VERSION ""

NS_ :

BS_:

BU_: ACCL BGW DBPC DCFL DCFR DCRL DCRR DSM ECPM FBCM FFL FLDC FRDC HLL HLR HUD IHUB LGL PBPC PSM RCLL RCLR RLDC RLSM RRDC RRSM TOOL RCCL RCCR SCAM DEMFL DEMFR DEMRL DEMRR DOSFL DOSFR DOSRL DOSRR
VAL_TABLE_ GLOB_VehicleSpeedDir 3 "SNA" 1 "Positive" 0 "Negative" ;
VAL_TABLE_ GLOB_UnlockPreference 3 "SNA" 1 "UnlockAllDoors" 0 "UnlockNearestDoor" ;
VAL_TABLE_ GLOB_DistanceUnits 3 "SNA" 1 "Mile" 0 "Kilometer" ;
VAL_TABLE_ GLOB_ChargeDisplaySetting 3 "SNA" 1 "Percentage" 0 "Miles" ;
VAL_TABLE_ GLOB_DewPointTempRls 3 "SNA" 2 "Err" 1 "Vel" 0 "Nr" ;
VAL_TABLE_ GLOB_RsSchwallRls 1 "Active" 0 "Inactive" ;
VAL_TABLE_ GLOB_WiperSpeedRls 3 "SNA" 2 "HighWiperSpeed" 1 "LowWiperSpeed" 0 "Stop" ;
VAL_TABLE_ GLOB_RlsStatus 7 "SNA" 3 "RlsActive" 2 "OverVoltage" 1 "LowVoltage" 0 "RlsRebooting" ;
VAL_TABLE_ GLOB_HumSnsIntFltRls 1 "Error" 0 "Normal" ;
VAL_TABLE_ GLOB_HeadLightsOnRls 1 "On" 0 "Off" ;
VAL_TABLE_ GLOB_AmbientBrightnessRls 1 "Error" 0 "Calculating" ;
VAL_TABLE_ GLOB_AmbientBrightnessRlsU16 2047 "Error" ;
VAL_TABLE_ GLOB_LowBeamRequest 15 "SNA" 7 "SubtractThreeDeg" 6 "SubtractTwoDeg" 5 "SubtractOneDeg" 4 "ZeroDeg" 3 "AddOneDeg" 2 "AddTwoDeg" 1 "AddThreeDeg" 0 "Stop" ;
VAL_TABLE_ GLOB_DriverMirrorHeaterState 3 "SNA" 2 "Fault" 1 "On" 0 "Off" ;
VAL_TABLE_ GLOB_ExtLightTemperatureStatus 3 "SNA" 2 "Under" 1 "Over" 0 "Ok" ;
VAL_TABLE_ GLOB_DoorStopSource 15 "SNA" 7 "Overcurrent" 6 "PreventativeObstacleDetection" 5 "ReactiveObstacleDetection" 4 "InteriorButton" 3 "ExteriorButton" 2 "Cpillar" 1 "Bpillar" 0 "Ihub" ;
VAL_TABLE_ BPG_ChargeStatus 15 "SNA" 10 "ChargeRetry" 9 "EvseInterruptedAndPluggedIn" 8 "UserInterruptedAndPluggedIn" 7 "ChargeToTargetAndPluggedIn" 6 "ChargeToTargetAndNotPluggedIn" 5 "ChargeCompleteAndNotPluggedIn" 4 "ChargeCompleteAndPluggedIn" 3 "Faulted" 2 "Charging" 1 "PluggedInAndNotCharging" 0 "NotPluggedIn" ;
VAL_TABLE_ GLOB_HonkThreeTimes 3 "SNA" 1 "HonkThreeTimes" 0 "NoCommand" ;
VAL_TABLE_ GLOB_FlashLights 3 "SNA" 1 "FlashLights" 0 "NoCommand" ;
VAL_TABLE_ GLOB_LedStatus 3 "SNA" 1 "Failure" 0 "Ok" ;
VAL_TABLE_ GLOB_BusStates 1 "Sleep" 0 "DoNotSleep" ;
VAL_TABLE_ GLOB_TemperatureStatus 3 "SNA" 2 "UnderTemperature" 1 "OverTemperature" 0 "Ok" ;
VAL_TABLE_ GLOB_SafeMode 3 "SNA" 1 "SafeMode" 0 "NormalMode" ;
VAL_TABLE_ GLOB_OffOnAutoSna 3 "SNA" 2 "Auto" 1 "On" 0 "Off" ;
VAL_TABLE_ GLOB_LanguageSelection 3 "SNA" 1 "Chinese" 0 "English" ;
VAL_TABLE_ GLOB_MassageIntensity 7 "SNA" 5 "5" 4 "4" 3 "3" 2 "2" 1 "1" 0 "0" ;
VAL_TABLE_ GLOB_SeatBeltState 1 "Buckled" 0 "Unbuckled" ;
VAL_TABLE_ BGW_BPillarScreenReq 7 "SNA" 4 "Doors" 3 "Charging" 2 "Welcome" 1 "Home" 0 "Off" ;
VAL_TABLE_ GLOB_SteerCommand 7 "SNA" 4 "Out" 3 "In" 2 "Down" 1 "Up" 0 "NoCommand" ;
VAL_TABLE_ GLOB_FwdRwdUpDn 7 "SNA" 4 "MoveDown" 3 "MoveUp" 2 "MoveRearward" 1 "MoveForward" 0 "NoCommand" ;
VAL_TABLE_ GLOB_TapHoldUpDn 7 "SNA" 4 "HoldUpward" 3 "TapUpward" 2 "HoldDownward" 1 "TapDownward" 0 "NoCommand" ;
VAL_TABLE_ GLOB_TapHoldFwdRwd 7 "SNA" 4 "HoldRearward" 3 "TapRearward" 2 "HoldForward" 1 "TapForward" 0 "NoCommand" ;
VAL_TABLE_ BGW_SeatShoulderCmd 3 "SNA" 2 "MoveBackward" 1 "MoveForward" 0 "NoCommand" ;
VAL_TABLE_ GLOB_SeatHeatVent 7 "SNA" 6 "VentHigh" 5 "VentMedium" 4 "VentLow" 3 "HeatHigh" 2 "HeatMedium" 1 "HeatLow" 0 "Off" ;
VAL_TABLE_ GLOB_MassageType 7 "SNA" 3 "Type3" 2 "Type2" 1 "Type1" 0 "Off" ;
VAL_TABLE_ GLOB_LatchStatus 6 "Unknown" 7 "SNA" 3 "Error" 2 "Primary" 1 "Secondary" 0 "Open" ;
VAL_TABLE_ GLOB_DoorCloseCmdSource 6 "CpillarClose" 7 "SNA" 5 "BpillarClose" 4 "BrakePressed" 3 "ExteriorButton" 2 "InteriorButton" 1 "EdgeSwitch" 0 "IhubClose" ;
VAL_TABLE_ GLOB_DoorOpenCmdSource 255 "SNA" 10 "CpillarOpen" 9 "CpillarPop" 8 "BpillarOpen" 7 "BpillarPop" 6 "InteriorButtonPop" 5 "InteriorButtonOpen" 4 "ExteriorButtonPop" 3 "ExteriorButtonOpen" 2 "EdgeSwitch" 1 "IhubOpen" 0 "IhubPop" ;
VAL_TABLE_ GLOB_WindowOpenSource 7 "SNA" 4 "IhubOpen" 3 "Dcrr" 2 "Dcrl" 1 "Dcfr" 0 "Dcfl" ;
VAL_TABLE_ GLOB_WindowCloseSource 7 "SNA" 4 "IhubClose" 3 "Dcrr" 2 "Dcrl" 1 "Dcfr" 0 "Dcfl" ;
VAL_TABLE_ GLOB_Latch 3 "SNA" 1 "Latch" 0 "NoLatch" ;
VAL_TABLE_ GLOB_VehicleVoltageMode 3 "SNA" 2 "Reserved" 1 "LowAndHighVoltage" 0 "False" ;
VAL_TABLE_ GLOB_VehicleDriveMode 3 "SNA" 2 "Moving" 1 "Run" 0 "False" ;
VAL_TABLE_ GLOB_VehicleSpeedQ 3 "InSpec" 0 "UndefinableAccuracySna" ;
VAL_TABLE_ GLOB_BaudRateOption 7 "SNA" 2 "Baud500k" 1 "Baud250k" 0 "Baud125k" ;
VAL_TABLE_ BGW_State 7 "SNA" 5 "EndDriveState" 4 "ExitingDriveState" 3 "DriveState" 2 "DriveAuthorizedState" 1 "DriveLikelyState" 0 "IdleState" ;
VAL_TABLE_ BGW_DoorState 3 "SNA" 2 "DoorError" 1 "DoorOpen" 0 "DoorClosed" ;
VAL_TABLE_ BGW_WakeUpCause 31 "SNA" 8 "LiftgateInteriorButton" 7 "IoExpander" 6 "Lin" 5 "WupLine" 4 "Rtc" 3 "ThermalCan" 2 "TelematicsCan" 1 "BodyCan" 0 "UnknownCause" ;
VAL_TABLE_ FBCM_HornStatus 3 "SNA" 2 "Fault" 1 "HornOn" 0 "HornOff" ;
VAL_TABLE_ FBCM_LockRejected 3 "SNA" 1 "LockRejected" 0 "LockNotRejected" ;
VAL_TABLE_ FBCM_StateVehicle 7 "SNA" 4 "SelfDriveState" 3 "DriveState" 2 "AccessoryState" 1 "StandbyState" 0 "SleepState" ;
VAL_TABLE_ FBCM_WasherFluidLevel 3 "SNA" 1 "Low" 0 "Off" ;
VAL_TABLE_ GLOB_LockRequest 3 "SNA" 2 "LockRequest" 1 "UnlockRequest" 0 "NoRequest" ;
VAL_TABLE_ GLOB_LightSync 3 "SNA" 2 "LampOff" 1 "LampOn" 0 "NoEffect" ;
VAL_TABLE_ GLOB_Bool 3 "SNA" 1 "True" 0 "False" ;
VAL_TABLE_ GLOB_BootloaderStuckSignal 255 "SNA" 18 "EcuSpecificReason3" 17 "EcuSpecificReason2" 16 "EcuSpecificReason1" 15 "Reserved12" 14 "Reserved11" 13 "Reserved10" 12 "Reserved9" 11 "Reserved8" 10 "Reserved7" 9 "Reserved6" 8 "Reserved5" 7 "Reserved4" 6 "Reserved3" 5 "Reserved2" 4 "Reserved1" 3 "BootloaderSelfCheckFail" 2 "ApplicationCrcfail" 1 "ApplicationNotPresent" 0 "NormalStartup" ;
VAL_TABLE_ GLOB_FrontTrunkStatus 3 "SNA" 2 "Ambiguous" 1 "Open" 0 "Closed" ;
VAL_TABLE_ GLOB_ChargePortDoorReq 3 "SNA" 2 "NoCommand" 1 "Open" 0 "Close" ;
VAL_TABLE_ GLOB_ChargePortDoorStatus 7 "SNA" 5 "DoorFault" 4 "DoorObstructed" 3 "DoorClosing" 2 "DoorOpen" 1 "DoorOpening" 0 "DoorClosed" ;
VAL_TABLE_ GLOB_DoorController 3 "SNA" 2 "Fault" 1 "Pressed" 0 "Unpressed" ;
VAL_TABLE_ GLOB_DoorOpenClose 7 "SNA" 4 "DoorStop" 3 "DoorPop" 2 "DoorClose" 1 "DoorOpen" 0 "NoCommand" ;
VAL_TABLE_ GLOB_DoorOperations 15 "SNA" 7 "PopDoor" 4 "DoorClose" 3 "DoorOpen" 1 "DoorStop" 0 "NoAction" ;
VAL_TABLE_ GLOB_DoorState 15 "SNA" 9 "DoorCinchingFailure" 8 "DoorUnlatchingError" 7 "DoorClosingError" 6 "DoorOpeningError" 5 "DoorClosingObstruction" 4 "DoorOpeningObstruction" 3 "DoorClosing" 2 "DoorOpening" 1 "DoorOpen" 0 "DoorClosed" ;
VAL_TABLE_ GLOB_FiveLevelIntensity 7 "SNA" 5 "Level5" 4 "Level4" 3 "Level3" 2 "Level2" 1 "Level1" 0 "Off" ;
VAL_TABLE_ GLOB_FimStatus 3 "SNA" 2 "InhibitedOnlyRemoteCause" 1 "InhibitedLocalCause" 0 "NotInhibited" ;
VAL_TABLE_ GLOB_LiftgateOperations 7 "SNA" 3 "Stop" 2 "Open" 1 "Close" 0 "NoAction" ;
VAL_TABLE_ GLOB_LiftgateStatus 15 "SNA" 7 "LiftgateClosingObstruction" 6 "LiftgateOpeningObstruction" 5 "HardwareFault" 4 "LiftgateClosing" 3 "LiftgateOpening" 2 "LiftgateClose" 1 "LiftgateAjar" 0 "LiftgateOpen" ;
VAL_TABLE_ GLOB_LightCmd 3 "SNA" 1 "TurnLightOn" 0 "TurnLightOff" ;
VAL_TABLE_ GLOB_LightStatus 3 "SNA" 2 "LightFault" 1 "LightOn" 0 "LightOff" ;
VAL_TABLE_ GLOB_LockUnlock 3 "SNA" 2 "NoChange" 1 "Unlock" 0 "Lock" ;
VAL_TABLE_ GLOB_LvMode 7 "SNA" 3 "Disconnected" 2 "ExtremelyLimited" 1 "Limited" 0 "LvAvailable" ;
VAL_TABLE_ GLOB_MirrorFold 3 "SNA" 2 "FoldIn" 1 "FoldOut" 0 "NoCommand" ;
VAL_TABLE_ GLOB_MirrorState 7 "SNA" 4 "Retracting" 3 "Retracted" 2 "Presenting" 1 "Presented" 0 "Unknown" ;
VAL_TABLE_ GLOB_MirrorTiltInOut 3 "SNA" 2 "TiltOut" 1 "TiltIn" 0 "NoCommand" ;
VAL_TABLE_ GLOB_MirrorTiltUpDown 3 "SNA" 2 "TiltDown" 1 "TiltUp" 0 "NoCommand" ;
VAL_TABLE_ GLOB_MirrorMoveInOutStatus 3 "SNA" 2 "MovingOut" 1 "MovingIn" 0 "NotMoving" ;
VAL_TABLE_ GLOB_MirrorMoveUpDownStatus 3 "SNA" 2 "MovingDown" 1 "MovingUp" 0 "NotMoving" ;
VAL_TABLE_ GLOB_OnOffError 3 "SNA" 2 "Error" 1 "On" 0 "Off" ;
VAL_TABLE_ GLOB_OnOffSna 3 "SNA" 1 "On" 0 "Off" ;
VAL_TABLE_ GLOB_EnableDisableSna 3 "SNA" 1 "Enable" 0 "Disable" ;
VAL_TABLE_ GLOB_PanelId 7 "SNA" 5 "All" 4 "Dbpc" 3 "Rrdp" 2 "Rldp" 1 "Pdp" 0 "Ddp" ;
VAL_TABLE_ GLOB_ResetCause 255 "SNA" 18 "EcuSpecificReason3" 17 "EcuSpecificReason2" 16 "EcuSpecificReason1" 15 "Reserved10" 14 "Reserved9" 13 "Reserved8" 12 "Reserved7" 11 "Reserved6" 10 "Reserved5" 9 "Reserved4" 8 "Reserved3" 7 "Reserved2" 6 "Reserved1" 5 "SoftwareException" 4 "UdsResetRequest" 3 "PowerMonitor" 2 "WatchdogTimer" 1 "WakeSignal" 0 "NormalWakeCanOrRtc" ;
VAL_TABLE_ GLOB_RsdFoldUnfold 7 "SNA" 3 "NoAction" 2 "Stop" 1 "UnfoldDown" 0 "FoldUp" ;
VAL_TABLE_ GLOB_SeatAntiPanicStatus 3 "SNA" 2 "AntiPanicStatusUnused" 1 "AntiPanicStatusActive" 0 "AntiPanicStatusInactive" ;
VAL_TABLE_ GLOB_BoolNoSNA 1 "True" 0 "False" ;
VAL_TABLE_ GLOB_SeatFaultStatus 3 "SNA" 2 "FaultStatusFaultFailure" 1 "FaultStatusFaultWarning" 0 "FaultStatusNoFault" ;
VAL_TABLE_ GLOB_SeatInitStatus 3 "SNA" 1 "InitStatusFault" 0 "InitStatusNoFault" ;
VAL_TABLE_ GLOB_SeatPsngrTiltCmd 3 "SNA" 2 "MoveDown" 1 "MoveUp" 0 "Stop" ;
VAL_TABLE_ GLOB_SeatRearRBackrestCmd 3 "SNA" 2 "MoveBackward" 1 "MoveForward" 0 "Stop" ;
VAL_TABLE_ GLOB_SeatVBatEleStatus 3 "SNA" 1 "VbatComfortFault" 0 "VbatComfortNoFault" ;
VAL_TABLE_ GLOB_SeatVBatPowerStatus 3 "SNA" 1 "VbatMotorFault" 0 "VbatMotorNoFault" ;
VAL_TABLE_ GLOB_SequenceIdAes 255 "SNA" 99 "Null" 98 "PreparingToCharge" 97 "ChargingInProgress" 96 "ChargingErrorState" 95 "BatteryLowState" 94 "ScheduleToCharge" 93 "PickupMode" 92 "Awake" 91 "Unlock" 90 "Lock" 89 "GoodBye" 88 "OpenLeftFront" 87 "CloseLeftFront" 86 "OpenRightFront" 85 "CloseRightFront" 84 "OpenLeftRear" 83 "CloseLeftRear" 82 "OpenRightRear" 81 "CloseRightRear" 80 "DriveDefault" 79 "DriveEce" 78 "DriveFmvss" 77 "DriveCcc" ;
VAL_TABLE_ GLOB_SequenceIdExterior 61 "RedCalibration" 60 "GreenCalibration" 59 "BlueCalibration" 58 "PinkCalibration" 255 "SNA" 23 "ReservedC" 22 "ReservedB" 21 "ReservedA" 20 "ChargeComplete" 19 "ScheduledToCharge" 18 "ErrorState" 17 "ChargingInProgress" 16 "PreparingToCharge" 15 "AirportPickupMode" 14 "RndToP" 13 "PtoRnd" 12 "DoorCloseRearRight" 11 "DoorCloseRearLeft" 10 "DoorCloseFrontRight" 9 "DoorCloseFrontLeft" 8 "DoorOpenRearRight" 7 "DoorOpenRearLeft" 6 "DoorOpenFrontRight" 5 "DoorOpenFrontLeft" 4 "Lock" 3 "Unlock" 2 "Sleep" 1 "Awake" 0 "Off" ;
VAL_TABLE_ GLOB_SequenceStatus 3 "SNA" 1 "Running" 0 "NotRunning" ;
VAL_TABLE_ GLOB_SnaU08 255 "SNA" ;
VAL_TABLE_ GLOB_SnaU10 1023 "SNA" ;
VAL_TABLE_ GLOB_TempDisplayUnits 3 "SNA" 1 "Fahrenheit" 0 "Celsius" ;
VAL_TABLE_ GLOB_EventsUnread 3 "SNA" 2 "NotUsed" 1 "NewEvents" 0 "NoNewEvents" ;
VAL_TABLE_ GLOB_Dem 3 "SNA" 2 "Untested" 1 "Set" 0 "Cleared" ;
VAL_TABLE_ GLOB_WindowStatus 7 "SNA" 5 "TempShutoff" 4 "Error" 3 "WindowRollingDown" 2 "WindowRollingUp" 1 "WindowOpen" 0 "WindowClosed" ;
VAL_TABLE_ GLOB_WindowRequest 7 "SNA" 4 "PropUp" 3 "PropDown" 2 "AutoUp" 1 "AutoDown" 0 "NoCommand" ;
VAL_TABLE_ GLOB_WindowDoorControllerReq 7 "SNA" 6 "AutoUp" 5 "AutoDown" 2 "PropUp" 1 "PropDown" 0 "NoCommand" ;
VAL_TABLE_ GLOB_WiperCommand 15 "SNA" 9 "IntermittentMode1" 8 "IntermittentMode2" 7 "IntermittentMode3" 6 "IntermittentMode4" 5 "IntermittentMode5" 4 "ServicePosition" 3 "HighWipes" 2 "LowWipes" 1 "Park" 0 "NoWipe" ;
VAL_TABLE_ GLOB_WiperStatus 15 "SNA" 10 "WiperFailure" 9 "IntermittentMode1" 8 "IntermittentMode2" 7 "IntermittentMode3" 6 "IntermittentMode4" 5 "IntermittentMode5" 4 "ServicePosition" 3 "HighWipes" 2 "LowWipes" 1 "Parked" 0 "NoWipe" ;
VAL_TABLE_ GLOB_LightLaneChangeOnReq 3 "SNA" 2 "TurnLightOn" 1 "TurnLightOff" 0 "NoCommand" ;
VAL_TABLE_ GLOB_Prnd 255 "SNA" 3 "Drive" 2 "Neutral" 1 "Reverse" 0 "Park" ;
VAL_TABLE_ IHUB_ExteriorLightReq 7 "SNA" 4 "Auto" 3 "HighBeam" 2 "LowBeam" 1 "Parking" 0 "Off" ;
VAL_TABLE_ GLOB_LocalSwitchState 7 "SNA" 2 "LocalSwitchClosed" 1 "LocalSwitchOpen" 0 "NoSwitch" ;
VAL_TABLE_ GLOB_FbcmWakeCause 5 "HornSwitch" 7 "SNA" 4 "Dcfr" 3 "Dcfl" 2 "Bgw" 1 "HazardLights" 0 "Unknown" ;
VAL_TABLE_ GLOB_DoorFrontWakeCause 7 "SNA" 4 "Fbcm" 3 "ExtDoorOpenSw" 2 "IntOpenCloseSw" 1 "IntDoorReleaseSw" 0 "Unknown" ;
VAL_TABLE_ GLOB_DoorRearWakeCause 7 "SNA" 4 "Bgw" 3 "ExtDoorOpenSw" 2 "IntOpenCloseSw" 1 "IntDoorReleaseSw" 0 "Unknown" ;
VAL_TABLE_ BGW_ResetCause 255 "SNA" 250 "UnknownReason" 21 "ExrF31" 20 "HsmF29" 19 "SoftF28" 18 "NmiF27" 17 "StDoneF25" 16 "OscResetF24" 15 "FccuLongResetF23" 14 "FccuShortResetF22" 13 "Z4aDbgResetF21" 12 "Z4bDbgResetF20" 11 "Z2DbgResetF19" 10 "LvdResetF18" 9 "HvdResetF17" 8 "Pd2LvdResetF14" 7 "HsmResetD29" 6 "SoftwareD28" 5 "SscmResetD27" 4 "SufResetD25" 3 "Core0ResetD24" 2 "Core1ResetD23" 1 "Core2ResetD22" 0 "NormalWakeD31" ;
VAL_TABLE_ GLOB_RSDStatus 3 "SNA" 2 "Unknown" 1 "Moving" 0 "Idle" ;
VAL_TABLE_ GLOB_DEMGesture 3 "SNA" 1 "Swipe" 0 "Tap" ;

BO_ 632 DEMFL_DoorCommand: 1 DEMFL
 SG_ doorDemGesture_DEMFL : 1|2@0+ (1,0) [0|1] ""  DCFL,DCFR,DCRL,DCRR,TOOL

BO_ 664 DEMFR_DoorCommand: 1 DEMFR
 SG_ doorDemGesture_DEMFR : 1|2@0+ (1,0) [0|1] ""  DCFL,DCFR,DCRL,DCRR,TOOL

BO_ 696 DEMRL_DoorCommand: 1 DEMRL
 SG_ doorDemGesture_DEMRL : 1|2@0+ (1,0) [0|1] ""  DCFL,DCFR,DCRL,DCRR,TOOL

BO_ 736 DEMRR_DoorCommand: 1 DEMRR
 SG_ doorDemGesture_DEMRR : 1|2@0+ (1,0) [0|1] ""  DCFL,DCFR,DCRL,DCRR,TOOL

BO_ 808 DOSFL_DoorStatus: 1 DOSFL
 SG_ doorDosObstruction_DOSFL : 1|2@0+ (1,0) [0|1] ""  DCFL,DCFR,DCRL,DCRR,TOOL

BO_ 872 DOSFR_DoorStatus: 1 DOSFR
 SG_ doorDosObstruction_DOSFR : 1|2@0+ (1,0) [0|1] ""  DCFL,DCFR,DCRL,DCRR,TOOL

BO_ 880 DOSRL_DoorStatus: 1 DOSRL
 SG_ doorDosObstruction_DOSRL : 1|2@0+ (1,0) [0|1] ""  DCFL,DCFR,DCRL,DCRR,TOOL

BO_ 888 DOSRR_DoorStatus: 1 DOSRR
 SG_ doorDosObstruction_DOSRR : 1|2@0+ (1,0) [0|1] ""  DCFL,DCFR,DCRL,DCRR,TOOL

BO_ 1661 DEMFL_UDSRequest: 8 TOOL
 SG_ udsClientDataDEMFL_TOOL : 7|64@0+ (1,0) [0|1.84467440737094E+019] ""  DEMFL

BO_ 1662 DEMFL_UDSResponse: 8 DEMFL
 SG_ udsServerData_DEMFL : 7|64@0+ (1,0) [0|1.84467440737094E+019] ""  TOOL

BO_ 1693 DEMFR_UDSRequest: 8 TOOL
 SG_ udsClientDataDEMFR_TOOL : 7|64@0+ (1,0) [0|1.84467440737094E+019] ""  DEMFR

BO_ 1694 DEMFR_UDSResponse: 8 DEMFR
 SG_ udsServerData_DEMFR : 7|64@0+ (1,0) [0|1.84467440737094E+019] ""  TOOL

BO_ 1725 DEMRL_UDSRequest: 8 TOOL
 SG_ udsClientDataDEMRL_TOOL : 7|64@0+ (1,0) [0|1.84467440737094E+019] ""  DEMRL

BO_ 1726 DEMRL_UDSResponse: 8 DEMRL
 SG_ udsServerData_DEMRL : 7|64@0+ (1,0) [0|1.84467440737094E+019] ""  TOOL

BO_ 1765 DEMRR_UDSRequest: 8 TOOL
 SG_ udsClientDataDEMRR_TOOL : 7|64@0+ (1,0) [0|1.84467440737094E+019] ""  DEMRR

BO_ 1766 DEMRR_UDSResponse: 8 DEMRR
 SG_ udsServerData_DEMRR : 7|64@0+ (1,0) [0|1.84467440737094E+019] ""  TOOL

BO_ 1837 DOSFL_UDSRequest: 8 TOOL
 SG_ udsClientDataDOSFL_TOOL : 7|64@0+ (1,0) [0|1.84467440737094E+019] ""  DOSFL

BO_ 1838 DOSFL_UDSResponse: 8 DOSFL
 SG_ udsServerData_DOSFL : 7|64@0+ (1,0) [0|1.84467440737094E+019] ""  TOOL

BO_ 1901 DOSFR_UDSRequest: 8 TOOL
 SG_ udsClientDataDOSFR_TOOL : 7|64@0+ (1,0) [0|1.84467440737094E+019] ""  DOSFR

BO_ 1902 DOSFR_UDSResponse: 8 DOSFR
 SG_ udsServerData_DOSFR : 7|64@0+ (1,0) [0|1.84467440737094E+019] ""  TOOL

BO_ 1909 DOSRL_UDSRequest: 8 TOOL
 SG_ udsClientDataDOSRL_TOOL : 7|64@0+ (1,0) [0|1.84467440737094E+019] ""  DOSRL

BO_ 1910 DOSRL_UDSResponse: 8 DOSRL
 SG_ udsServerData_DOSRL : 7|64@0+ (1,0) [0|1.84467440737094E+019] ""  TOOL

BO_ 1917 DOSRR_UDSRequest: 8 TOOL
 SG_ udsClientDataDOSRR_TOOL : 7|64@0+ (1,0) [0|1.84467440737094E+019] ""  DOSRR

BO_ 1918 DOSRR_UDSResponse: 8 DOSRR
 SG_ udsServerData_DOSRR : 7|64@0+ (1,0) [0|1.84467440737094E+019] ""  TOOL

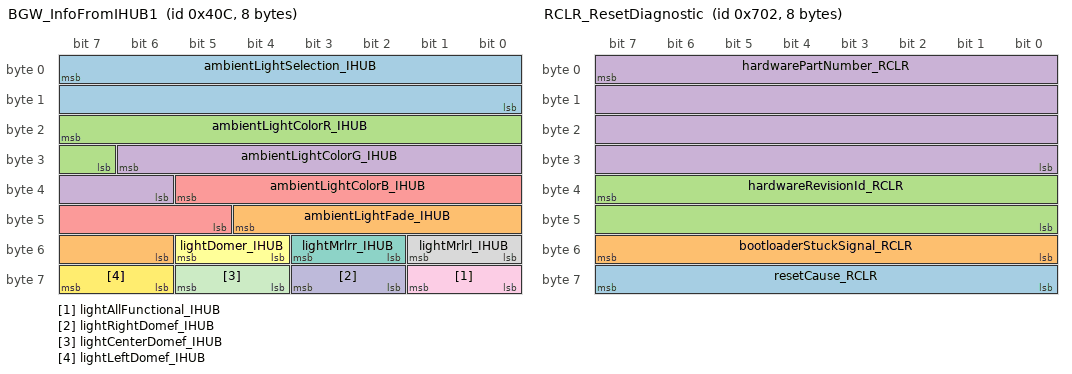
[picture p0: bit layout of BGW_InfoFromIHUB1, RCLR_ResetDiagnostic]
BO_ 1036 BGW_InfoFromIHUB1: 8 BGW
 SG_ ambientLightSelection_IHUB : 7|16@0+ (1,0) [0|65534] ""  FBCM,DCFL,DCFR,DCRL,DCRR
 SG_ ambientLightFade_IHUB : 44|7@0+ (1,0) [0|126] ""  FBCM,DCFL,DCFR,DCRL,DCRR
 SG_ ambientLightColorR_IHUB : 23|9@0+ (1,0) [0|510] ""  FBCM,DCFL,DCFR,DCRL,DCRR
 SG_ ambientLightColorG_IHUB : 30|9@0+ (1,0) [0|510] ""  FBCM,DCFL,DCFR,DCRL,DCRR
 SG_ ambientLightColorB_IHUB : 37|9@0+ (1,0) [0|510] ""  FBCM,DCFL,DCFR,DCRL,DCRR
 SG_ lightDomer_IHUB : 53|2@0+ (1,0) [0|3] ""  FBCM
 SG_ lightMrlrr_IHUB : 51|2@0+ (1,0) [0|3] ""  FBCM
 SG_ lightMrlrl_IHUB : 49|2@0+ (1,0) [0|3] ""  FBCM
 SG_ lightAllFunctional_IHUB : 57|2@0+ (1,0) [0|3] ""  FBCM
 SG_ lightRightDomef_IHUB : 59|2@0+ (1,0) [0|3] ""  FBCM
 SG_ lightCenterDomef_IHUB : 61|2@0+ (1,0) [0|3] ""  FBCM
 SG_ lightLeftDomef_IHUB : 63|2@0+ (1,0) [0|3] ""  FBCM

BO_ 683 DCRL_WindowMirrorPosition: 4 DCRL
 SG_ windowPositionRL_DCRL : 31|8@0+ (1,0) [0|100] ""  BGW

BO_ 715 DCRR_WindowMirrorPosition: 4 DCRR
 SG_ windowPositionRR_DCRR : 31|8@0+ (1,0) [0|100] ""  BGW

BO_ 1740 DCRR_XCPResponse: 8 DCRR
 SG_ xcpResponseData_DCRR : 7|64@0+ (1,0) [0|1.84467440737094E+019] ""  TOOL

BO_ 1739 DCRR_XCPRequest: 8 TOOL
 SG_ xcpRequestDataDCRR_TOOL : 7|64@0+ (1,0) [0|1.84467440737094E+019] ""  DCRR

BO_ 1708 DCRL_XCPResponse: 8 DCRL
 SG_ xcpResponseData_DCRL : 7|64@0+ (1,0) [0|1.84467440737094E+019] ""  TOOL

BO_ 1707 DCRL_XCPRequest: 8 TOOL
 SG_ xcpRequestDataDCRL_TOOL : 7|64@0+ (1,0) [0|1.84467440737094E+019] ""  DCRL

BO_ 1644 DCFR_XCPResponse: 8 DCFR
 SG_ xcpResponseData_DCFR : 7|64@0+ (1,0) [0|1.84467440737094E+019] ""  TOOL

BO_ 1643 DCFR_XCPRequest: 8 TOOL
 SG_ xcpRequestDataDCFR_TOOL : 7|64@0+ (1,0) [0|1.84467440737094E+019] ""  DCFR

BO_ 1636 DCFL_XCPResponse: 8 DCFL
 SG_ xcpResponseData_DCFL : 7|64@0+ (1,0) [0|1.84467440737094E+019] ""  TOOL

BO_ 1635 DCFL_XCPRequest: 8 TOOL
 SG_ xcpRequestDataDCFL_TOOL : 7|64@0+ (1,0) [0|1.84467440737094E+019] ""  DCFL

BO_ 266 BGW_MirrorandSteerCommand2: 3 BGW
 SG_ steeringMoveAbsTiltPos_BGW : 11|12@0+ (1,0) [0|4095] "HallCounts"  FBCM
 SG_ steeringMoveAbsTelePos_BGW : 7|12@0+ (1,0) [0|4095] "HallCounts"  FBCM

BO_ 1794 RCLR_ResetDiagnostic: 8 RCLR
 SG_ resetCause_RCLR : 63|8@0+ (1,0) [0|254] ""  TOOL,BGW
 SG_ bootloaderStuckSignal_RCLR : 55|8@0+ (1,0) [0|254] ""  TOOL,BGW
 SG_ hardwareRevisionId_RCLR : 39|16@0+ (1,0) [0|65534] ""  TOOL,BGW
 SG_ hardwarePartNumber_RCLR : 7|32@0+ (1,0) [0|4294967294] ""  TOOL,BGW

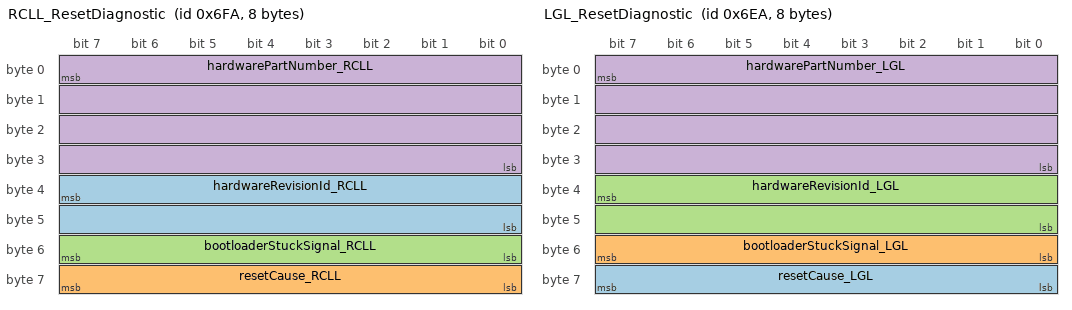
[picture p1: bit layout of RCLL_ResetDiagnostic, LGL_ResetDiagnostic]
BO_ 1786 RCLL_ResetDiagnostic: 8 RCLL
 SG_ hardwareRevisionId_RCLL : 39|16@0+ (1,0) [0|65534] ""  TOOL,BGW
 SG_ resetCause_RCLL : 63|8@0+ (1,0) [0|254] ""  TOOL,BGW
 SG_ bootloaderStuckSignal_RCLL : 55|8@0+ (1,0) [0|254] ""  TOOL,BGW
 SG_ hardwarePartNumber_RCLL : 7|32@0+ (1,0) [0|4294967294] ""  TOOL,BGW

BO_ 1770 LGL_ResetDiagnostic: 8 LGL
 SG_ resetCause_LGL : 63|8@0+ (1,0) [0|254] ""  TOOL,BGW
 SG_ bootloaderStuckSignal_LGL : 55|8@0+ (1,0) [0|254] ""  TOOL,BGW
 SG_ hardwareRevisionId_LGL : 39|16@0+ (1,0) [0|65534] ""  TOOL,BGW
 SG_ hardwarePartNumber_LGL : 7|32@0+ (1,0) [0|4294967294] ""  BGW,TOOL

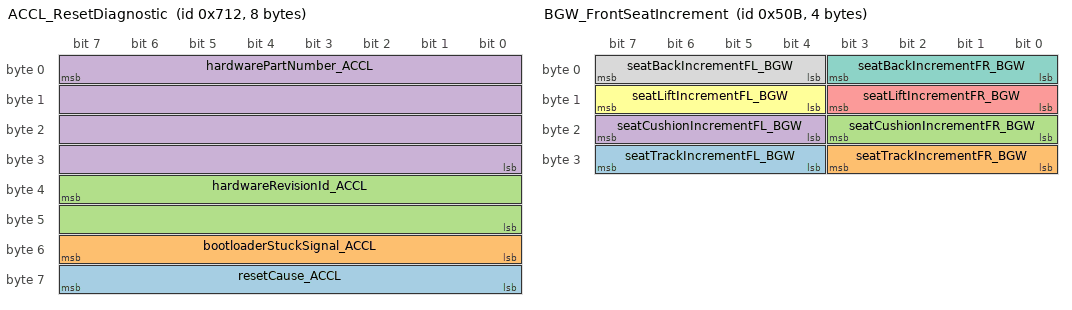
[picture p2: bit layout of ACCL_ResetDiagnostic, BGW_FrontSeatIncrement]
BO_ 1810 ACCL_ResetDiagnostic: 8 ACCL
 SG_ resetCause_ACCL : 63|8@0+ (1,0) [0|254] ""  BGW,TOOL
 SG_ bootloaderStuckSignal_ACCL : 55|8@0+ (1,0) [0|254] ""  BGW,TOOL
 SG_ hardwareRevisionId_ACCL : 39|16@0+ (1,0) [0|65534] ""  BGW,TOOL
 SG_ hardwarePartNumber_ACCL : 7|32@0+ (1,0) [0|4294967294] ""  BGW,TOOL

BO_ 1383 RRDC_SequenceResponse: 8 RRDC
 SG_ sequenceServerData_RRDC : 7|64@0+ (1,0) [0|1.84467440737094E+019] ""  TOOL

BO_ 1382 RRDC_SequenceUpload: 8 TOOL
 SG_ sequenceClientDataRRDC_TOOL : 7|64@0+ (1,0) [0|1.84467440737094E+019] ""  RRDC

BO_ 1375 RLDC_SequenceResponse: 8 RLDC
 SG_ sequenceServerData_RLDC : 7|64@0+ (1,0) [0|1.84467440737094E+019] ""  TOOL

BO_ 1374 RLDC_SequenceUpload: 8 TOOL
 SG_ sequenceClientDataRLDC_TOOL : 7|64@0+ (1,0) [0|1.84467440737094E+019] ""  RLDC

BO_ 1367 FRDC_SequenceResponse: 8 FRDC
 SG_ sequenceServerData_FRDC : 7|64@0+ (1,0) [0|1.84467440737094E+019] ""  TOOL

BO_ 1366 FRDC_SequenceUpload: 8 TOOL
 SG_ sequenceClientDataFRDC_TOOL : 7|64@0+ (1,0) [0|1.84467440737094E+019] ""  FRDC

BO_ 1359 FLDC_SequenceResponse: 8 FLDC
 SG_ sequenceServerData_FLDC : 7|64@0+ (1,0) [0|1.84467440737094E+019] ""  TOOL

BO_ 1358 FLDC_SequenceUpload: 8 TOOL
 SG_ sequenceClientDataFLDC_TOOL : 7|64@0+ (1,0) [0|1.84467440737094E+019] ""  FLDC

BO_ 1291 BGW_FrontSeatIncrement: 4 BGW
 SG_ seatTrackIncrementFL_BGW : 31|4@0+ (1,0) [0|14] "mm"  DSM
 SG_ seatTrackIncrementFR_BGW : 27|4@0+ (1,0) [0|14] "mm"  PSM
 SG_ seatCushionIncrementFR_BGW : 19|4@0+ (0.1,0) [0|1.4] "degrees"  PSM
 SG_ seatCushionIncrementFL_BGW : 23|4@0+ (0.1,0) [0|1.4] "degrees"  DSM
 SG_ seatLiftIncrementFR_BGW : 11|4@0+ (1,0) [0|14] "mm"  PSM
 SG_ seatLiftIncrementFL_BGW : 15|4@0+ (1,0) [0|14] "mm"  DSM
 SG_ seatBackIncrementFR_BGW : 3|4@0+ (0.1,0) [0|1.4] "degrees"  PSM
 SG_ seatBackIncrementFL_BGW : 7|4@0+ (0.1,0) [0|1.4] "degrees"  DSM

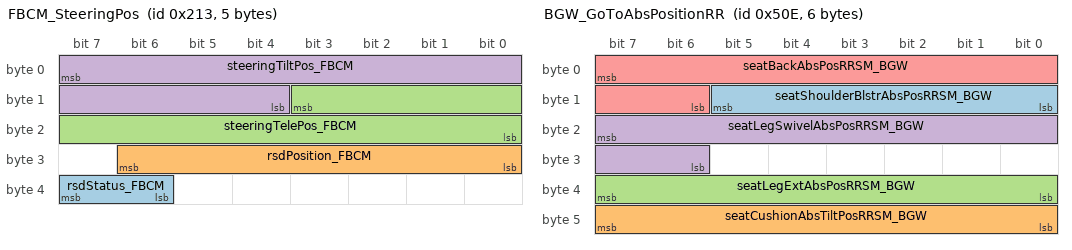
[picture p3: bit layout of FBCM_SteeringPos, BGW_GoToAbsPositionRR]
BO_ 531 FBCM_SteeringPos: 5 FBCM
 SG_ rsdStatus_FBCM : 39|2@0+ (1,0) [0|3] ""  IHUB,BGW
 SG_ rsdPosition_FBCM : 30|7@0+ (1,0) [0|105] ""  IHUB,BGW
 SG_ steeringTelePos_FBCM : 11|12@0+ (1,0) [0|4095] "HallCounts"  BGW
 SG_ steeringTiltPos_FBCM : 7|12@0+ (1,0) [0|4095] "HallCount"  BGW

BO_ 1288 BGW_RearSeatCmds: 8 BGW
 SG_ seatCushionTiltCmdRR_BGW : 11|2@0+ (1,0) [0|0] ""  RRSM
 SG_ seatCushionTiltCmdRL_BGW : 13|2@0+ (1,0) [0|0] ""  RLSM
 SG_ seatLegSwivelIncrementRL_BGW : 63|4@0+ (0.1,0) [0|1.4] "degrees"  RLSM
 SG_ seatLegSwivelIncrementRR_BGW : 59|4@0+ (0.1,0) [0|1.4] "degrees"  RRSM
 SG_ seatLegExtIncrementRL_BGW : 55|4@0+ (1,0) [0|14] "mm"  RLSM
 SG_ seatLegExtIncrementRR_BGW : 51|4@0+ (1,0) [0|14] "mm"  RRSM
 SG_ seatCushionIncrementRL_BGW : 47|4@0+ (0.1,0) [0|1.4] "degrees"  RLSM
 SG_ seatCushionIncrementRR_BGW : 43|4@0+ (0.1,0) [0|1.4] "degrees"  RRSM
 SG_ seatBackIncrementRL_BGW : 39|4@0+ (0.1,0) [0|1.4] "degrees"  RLSM
 SG_ seatBackIncrementRR_BGW : 35|4@0+ (0.1,0) [0|1.4] "degrees"  RRSM
 SG_ seatLegExtCmdRR_BGW : 31|2@0+ (1,0) [0|2] ""  RRSM
 SG_ seatBackCmdRR_BGW : 17|2@0+ (1,0) [0|2] ""  RRSM
 SG_ seatShoulderBolsterCmdRR_BGW : 19|2@0+ (1,0) [0|0] ""  RRSM
 SG_ seatShoulderBolsterCmdRL_BGW : 21|2@0+ (1,0) [0|0] ""  RLSM
 SG_ seatBackCmdRL_BGW : 23|2@0+ (1,0) [0|2] ""  RLSM
 SG_ seatLegSwivelCmdRL_BGW : 9|2@0+ (1,0) [0|2] ""  RLSM
 SG_ seatLegSwivelCmdRR_BGW : 15|2@0+ (1,0) [0|2] ""  RRSM
 SG_ seatLegExtCmdRL_BGW : 1|2@0+ (1,0) [0|2] ""  RLSM
 SG_ seatBackLumbarCmdRR_BGW : 4|3@0+ (1,0) [0|0] ""  RRSM
 SG_ seatBackLumbarCmdRL_BGW : 7|3@0+ (1,0) [0|0] ""  RLSM

BO_ 1294 BGW_GoToAbsPositionRR: 6 BGW
 SG_ seatShoulderBlstrAbsPosRRSM_BGW : 13|6@0+ (0.1,0.4) [0.4|2.4] "V"  RRSM
 SG_ seatCushionAbsTiltPosRRSM_BGW : 47|8@0+ (0.1,0) [0|20] "degrees"  RRSM
 SG_ seatLegExtAbsPosRRSM_BGW : 39|8@0+ (1,0) [0|130] "mm"  RRSM
 SG_ seatLegSwivelAbsPosRRSM_BGW : 23|10@0+ (0.1,0) [0|72.5] "degrees"  RRSM
 SG_ seatBackAbsPosRRSM_BGW : 7|10@0- (0.1,0) [-32|8] "degrees"  RRSM

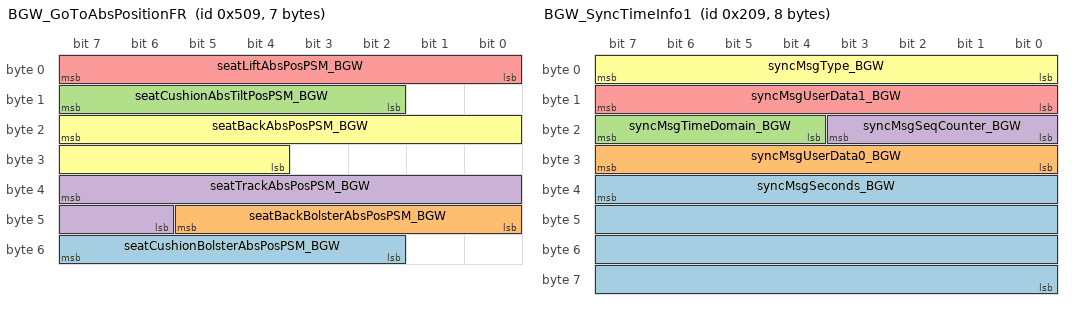
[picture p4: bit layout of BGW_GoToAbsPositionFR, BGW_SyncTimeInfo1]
BO_ 1289 BGW_GoToAbsPositionFR: 7 BGW
 SG_ seatCushionBolsterAbsPosPSM_BGW : 55|6@0+ (0.1,0.4) [0.4|2.4] "V"  PSM
 SG_ seatBackBolsterAbsPosPSM_BGW : 45|6@0+ (0.1,0.4) [0.4|2.4] "V"  PSM
 SG_ seatCushionAbsTiltPosPSM_BGW : 15|6@0+ (0.1,0) [0|6] "degrees"  PSM
 SG_ seatTrackAbsPosPSM_BGW : 39|10@0- (1,0) [-75|185] "mm"  PSM
 SG_ seatLiftAbsPosPSM_BGW : 7|8@0- (1,0) [-22|43] "mm"  PSM
 SG_ seatBackAbsPosPSM_BGW : 23|12@0- (0.1,0) [-20|54] "degrees"  PSM

BO_ 521 BGW_SyncTimeInfo1: 8 BGW
 SG_ syncMsgSeconds_BGW : 39|32@0+ (1,0) [0|4294967294] ""  DCFL,DCFR,DCRL,DCRR,FBCM
 SG_ syncMsgUserData0_BGW : 31|8@0+ (1,0) [0|254] ""  DCFL,DCFR,DCRL,DCRR,FBCM
 SG_ syncMsgTimeDomain_BGW : 23|4@0+ (1,0) [0|14] ""  DCFL,DCFR,DCRL,DCRR,FBCM
 SG_ syncMsgSeqCounter_BGW : 19|4@0+ (1,0) [0|14] ""  DCFL,DCFR,DCRL,DCRR,FBCM
 SG_ syncMsgUserData1_BGW : 15|8@0+ (1,0) [0|254] ""  DCFL,DCFR,DCRL,DCRR,FBCM
 SG_ syncMsgType_BGW : 7|8@0+ (1,0) [0|254] ""  DCFL,DCFR,DCRL,DCRR,FBCM

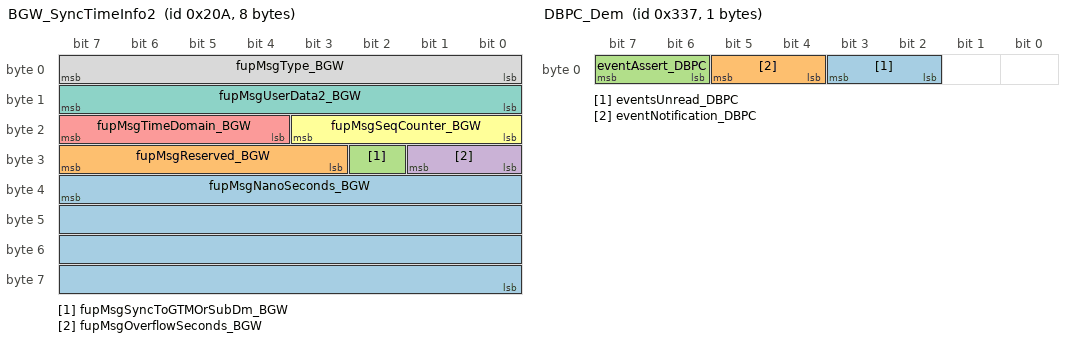
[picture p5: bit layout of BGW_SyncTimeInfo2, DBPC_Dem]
BO_ 522 BGW_SyncTimeInfo2: 8 BGW
 SG_ fupMsgNanoSeconds_BGW : 39|32@0+ (1,0) [0|4294967294] ""  DCFL,DCFR,DCRL,DCRR,FBCM
 SG_ fupMsgReserved_BGW : 31|5@0+ (1,0) [0|30] ""  DCFL,DCFR,DCRL,DCRR,FBCM
 SG_ fupMsgSyncToGTMOrSubDm_BGW : 26|1@0+ (1,0) [0|1] ""  DCFL,DCFR,DCRL,DCRR,FBCM
 SG_ fupMsgOverflowSeconds_BGW : 25|2@0+ (1,0) [0|2] ""  DCFL,DCFR,DCRL,DCRR,FBCM
 SG_ fupMsgTimeDomain_BGW : 23|4@0+ (1,0) [0|14] ""  DCFL,DCFR,DCRL,DCRR,FBCM
 SG_ fupMsgSeqCounter_BGW : 19|4@0+ (1,0) [0|14] ""  DCFL,DCFR,DCRL,DCRR,FBCM
 SG_ fupMsgUserData2_BGW : 15|8@0+ (1,0) [0|254] ""  DCFL,DCFR,DCRL,DCRR,FBCM
 SG_ fupMsgType_BGW : 7|8@0+ (1,0) [0|254] ""  DCFL,DCFR,DCRL,DCRR,FBCM

BO_ 780 BGW_ScreenReq: 2 BGW
 SG_ chargeTargetSOE_BGW : 15|6@0+ (1,38) [38|100] "%"  DBPC
 SG_ bPillarScreenReq_BGW : 7|3@0+ (1,0) [0|7] ""  DBPC

BO_ 823 DBPC_Dem: 1 DBPC
 SG_ eventsUnread_DBPC : 3|2@0+ (1,0) [0|0] ""  TOOL,BGW
 SG_ eventNotification_DBPC : 5|2@0+ (1,0) [0|0] ""  TOOL,BGW
 SG_ eventAssert_DBPC : 7|2@0+ (1,0) [0|0] ""  TOOL,BGW

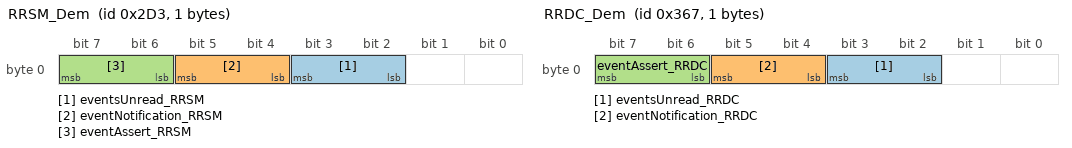
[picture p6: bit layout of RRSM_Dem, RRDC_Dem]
BO_ 723 RRSM_Dem: 1 RRSM
 SG_ eventsUnread_RRSM : 3|2@0+ (1,0) [0|0] ""  BGW,TOOL
 SG_ eventNotification_RRSM : 5|2@0+ (1,0) [0|0] ""  TOOL,BGW
 SG_ eventAssert_RRSM : 7|2@0+ (1,0) [0|0] ""  TOOL,BGW

BO_ 871 RRDC_Dem: 1 RRDC
 SG_ eventsUnread_RRDC : 3|2@0+ (1,0) [0|0] ""  TOOL,BGW
 SG_ eventNotification_RRDC : 5|2@0+ (1,0) [0|0] ""  TOOL,BGW
 SG_ eventAssert_RRDC : 7|2@0+ (1,0) [0|0] ""  TOOL,BGW

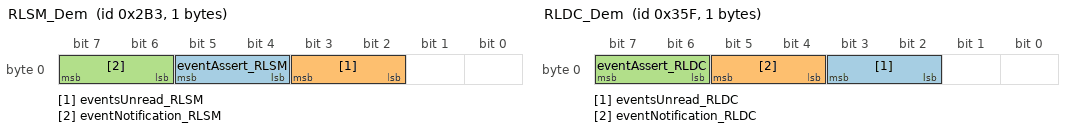
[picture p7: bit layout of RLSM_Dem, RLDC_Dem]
BO_ 691 RLSM_Dem: 1 RLSM
 SG_ eventAssert_RLSM : 5|2@0+ (1,0) [0|0] ""  TOOL,BGW
 SG_ eventsUnread_RLSM : 3|2@0+ (1,0) [0|0] ""  TOOL,BGW
 SG_ eventNotification_RLSM : 7|2@0+ (1,0) [0|0] ""  TOOL,BGW

BO_ 863 RLDC_Dem: 1 RLDC
 SG_ eventsUnread_RLDC : 3|2@0+ (1,0) [0|0] ""  TOOL,BGW
 SG_ eventNotification_RLDC : 5|2@0+ (1,0) [0|0] ""  TOOL,BGW
 SG_ eventAssert_RLDC : 7|2@0+ (1,0) [0|0] ""  TOOL,BGW

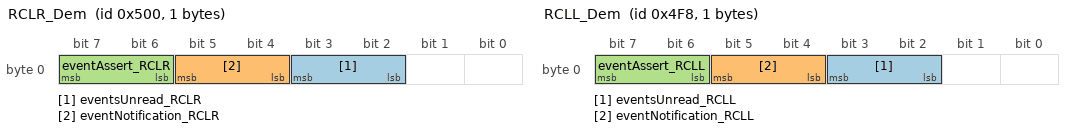
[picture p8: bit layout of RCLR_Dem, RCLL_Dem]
BO_ 1280 RCLR_Dem: 1 RCLR
 SG_ eventsUnread_RCLR : 3|2@0+ (1,0) [0|0] ""  TOOL,BGW
 SG_ eventNotification_RCLR : 5|2@0+ (1,0) [0|0] ""  TOOL,BGW
 SG_ eventAssert_RCLR : 7|2@0+ (1,0) [0|0] ""  TOOL,BGW

BO_ 1272 RCLL_Dem: 1 RCLL
 SG_ eventsUnread_RCLL : 3|2@0+ (1,0) [0|0] ""  TOOL,BGW
 SG_ eventNotification_RCLL : 5|2@0+ (1,0) [0|0] ""  TOOL,BGW
 SG_ eventAssert_RCLL : 7|2@0+ (1,0) [0|0] ""  TOOL,BGW

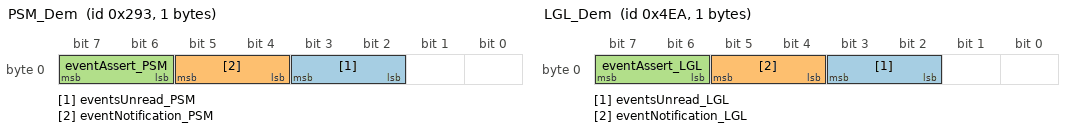
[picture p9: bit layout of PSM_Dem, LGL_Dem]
BO_ 659 PSM_Dem: 1 PSM
 SG_ eventsUnread_PSM : 3|2@0+ (1,0) [0|0] ""  TOOL,BGW
 SG_ eventNotification_PSM : 5|2@0+ (1,0) [0|0] ""  TOOL,BGW
 SG_ eventAssert_PSM : 7|2@0+ (1,0) [0|0] ""  TOOL,BGW

BO_ 1258 LGL_Dem: 1 LGL
 SG_ eventsUnread_LGL : 3|2@0+ (1,0) [0|0] ""  TOOL,BGW
 SG_ eventNotification_LGL : 5|2@0+ (1,0) [0|0] ""  TOOL,BGW
 SG_ eventAssert_LGL : 7|2@0+ (1,0) [0|0] ""  TOOL,BGW

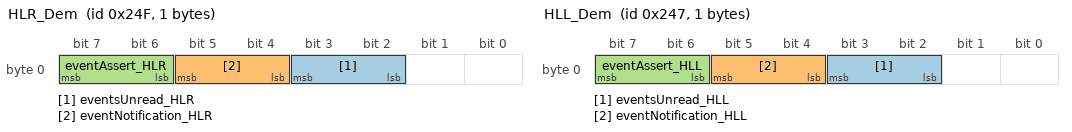
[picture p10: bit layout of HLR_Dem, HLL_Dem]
BO_ 591 HLR_Dem: 1 HLR
 SG_ eventsUnread_HLR : 3|2@0+ (1,0) [0|0] ""  TOOL,BGW
 SG_ eventNotification_HLR : 5|2@0+ (1,0) [0|0] ""  TOOL,BGW
 SG_ eventAssert_HLR : 7|2@0+ (1,0) [0|0] ""  TOOL,BGW

BO_ 583 HLL_Dem: 1 HLL
 SG_ eventsUnread_HLL : 3|2@0+ (1,0) [0|0] ""  TOOL,BGW
 SG_ eventNotification_HLL : 5|2@0+ (1,0) [0|0] ""  TOOL,BGW
 SG_ eventAssert_HLL : 7|2@0+ (1,0) [0|0] ""  TOOL,BGW

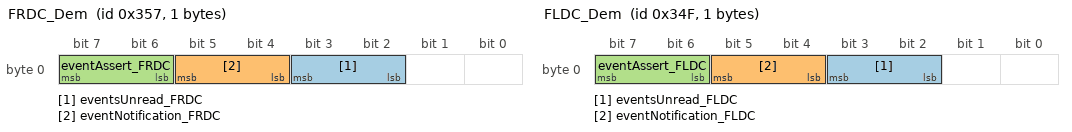
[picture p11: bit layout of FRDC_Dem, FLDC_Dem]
BO_ 855 FRDC_Dem: 1 FRDC
 SG_ eventsUnread_FRDC : 3|2@0+ (1,0) [0|0] ""  TOOL,BGW
 SG_ eventNotification_FRDC : 5|2@0+ (1,0) [0|0] ""  TOOL,BGW
 SG_ eventAssert_FRDC : 7|2@0+ (1,0) [0|0] ""  TOOL,BGW

BO_ 847 FLDC_Dem: 1 FLDC
 SG_ eventsUnread_FLDC : 3|2@0+ (1,0) [0|0] ""  TOOL,BGW
 SG_ eventNotification_FLDC : 5|2@0+ (1,0) [0|0] ""  TOOL,BGW
 SG_ eventAssert_FLDC : 7|2@0+ (1,0) [0|0] ""  TOOL,BGW

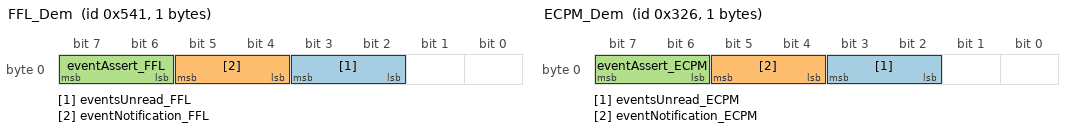
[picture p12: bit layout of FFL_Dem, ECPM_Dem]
BO_ 1345 FFL_Dem: 1 FFL
 SG_ eventsUnread_FFL : 3|2@0+ (1,0) [0|0] ""  TOOL,BGW
 SG_ eventNotification_FFL : 5|2@0+ (1,0) [0|0] ""  TOOL,BGW
 SG_ eventAssert_FFL : 7|2@0+ (1,0) [0|0] ""  TOOL,BGW

BO_ 806 ECPM_Dem: 1 ECPM
 SG_ eventsUnread_ECPM : 3|2@0+ (1,0) [0|0] ""  IHUB,TOOL,BGW
 SG_ eventNotification_ECPM : 5|2@0+ (1,0) [0|0] ""  TOOL,BGW
 SG_ eventAssert_ECPM : 7|2@0+ (1,0) [0|0] ""  TOOL,BGW

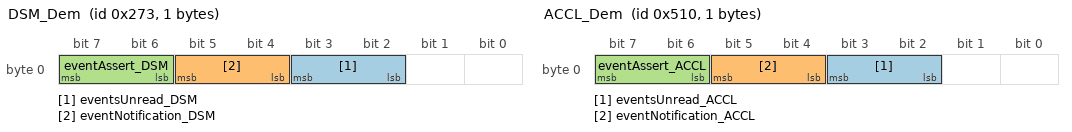
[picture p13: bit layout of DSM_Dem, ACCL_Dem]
BO_ 627 DSM_Dem: 1 DSM
 SG_ eventsUnread_DSM : 3|2@0+ (1,0) [0|0] ""  TOOL,BGW
 SG_ eventNotification_DSM : 5|2@0+ (1,0) [0|0] ""  TOOL,BGW
 SG_ eventAssert_DSM : 7|2@0+ (1,0) [0|0] ""  TOOL,BGW

BO_ 1296 ACCL_Dem: 1 ACCL
 SG_ eventsUnread_ACCL : 3|2@0+ (1,0) [0|0] ""  TOOL,BGW
 SG_ eventNotification_ACCL : 5|2@0+ (1,0) [0|0] ""  TOOL,BGW
 SG_ eventAssert_ACCL : 7|2@0+ (1,0) [0|0] ""  TOOL,BGW

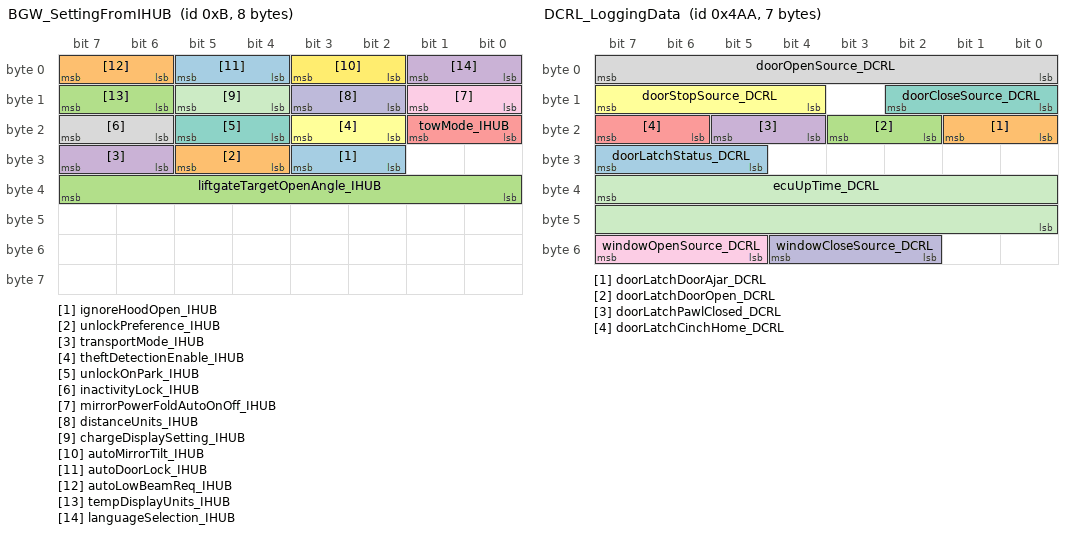
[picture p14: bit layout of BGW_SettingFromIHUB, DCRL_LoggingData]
BO_ 11 BGW_SettingFromIHUB: 8 BGW
 SG_ ignoreHoodOpen_IHUB : 27|2@0+ (1,0) [0|0] ""  FBCM
 SG_ unlockPreference_IHUB : 29|2@0+ (1,0) [0|3] ""  TOOL
 SG_ liftgateTargetOpenAngle_IHUB : 39|8@0+ (0.5,0) [0|73.5] "Degree"  TOOL
 SG_ transportMode_IHUB : 31|2@0+ (1,0) [0|0] ""  TOOL
 SG_ towMode_IHUB : 17|2@0+ (1,0) [0|0] ""  TOOL
 SG_ theftDetectionEnable_IHUB : 19|2@0+ (1,0) [0|0] ""  TOOL
 SG_ unlockOnPark_IHUB : 21|2@0+ (1,0) [0|0] ""  TOOL
 SG_ inactivityLock_IHUB : 23|2@0+ (1,0) [0|0] ""  TOOL
 SG_ mirrorPowerFoldAutoOnOff_IHUB : 9|2@0+ (1,0) [0|2] ""  DCFL,DCFR
 SG_ distanceUnits_IHUB : 11|2@0+ (1,0) [0|0] ""  DBPC
 SG_ chargeDisplaySetting_IHUB : 13|2@0+ (1,0) [0|0] ""  DBPC
 SG_ autoMirrorTilt_IHUB : 3|2@0+ (1,0) [0|0] ""  DCFL,DCFR,DCRL,DCRR
 SG_ autoDoorLock_IHUB : 5|2@0+ (1,0) [0|0] ""  DCFL,DCFR,DCRL,DCRR
 SG_ autoLowBeamReq_IHUB : 7|2@0+ (1,0) [0|2] ""  FBCM
 SG_ tempDisplayUnits_IHUB : 15|2@0+ (1,0) [0|0] ""  DBPC
 SG_ languageSelection_IHUB : 1|2@0+ (1,0) [0|0] ""  DBPC

BO_ 1194 DCRL_LoggingData: 7 DCRL
 SG_ doorLatchStatus_DCRL : 31|3@0+ (1,0) [0|0] ""  BGW,TOOL
 SG_ doorLatchDoorAjar_DCRL : 17|2@0+ (1,0) [0|0] ""  BGW,TOOL
 SG_ doorLatchDoorOpen_DCRL : 19|2@0+ (1,0) [0|0] ""  BGW,TOOL
 SG_ doorLatchPawlClosed_DCRL : 21|2@0+ (1,0) [0|0] ""  BGW,TOOL
 SG_ doorLatchCinchHome_DCRL : 23|2@0+ (1,0) [0|2] ""  BGW,TOOL
 SG_ doorStopSource_DCRL : 15|4@0+ (1,0) [0|0] ""  BGW,TOOL
 SG_ doorCloseSource_DCRL : 10|3@0+ (1,0) [0|0] ""  BGW,TOOL
 SG_ doorOpenSource_DCRL : 7|8@0+ (1,0) [0|0] ""  BGW,TOOL
 SG_ windowOpenSource_DCRL : 55|3@0+ (1,0) [0|2] ""  BGW,TOOL
 SG_ windowCloseSource_DCRL : 52|3@0+ (1,0) [0|2] ""  BGW,TOOL
 SG_ ecuUpTime_DCRL : 39|16@0+ (1,0) [0|65534] "Seconds"  BGW,TOOL

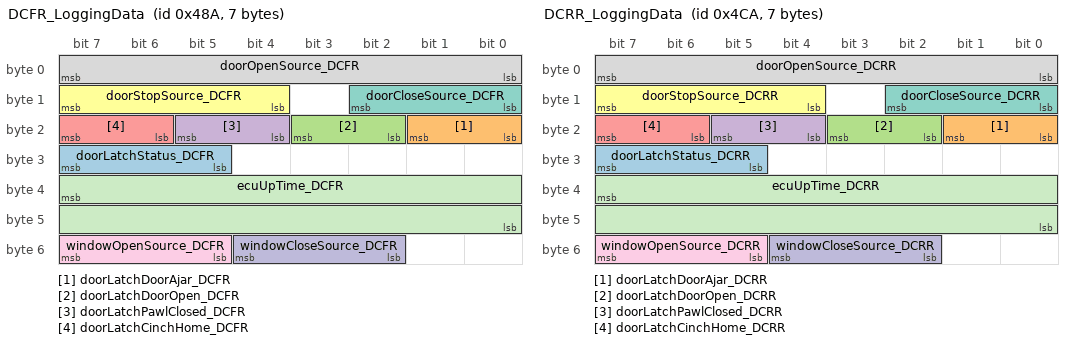
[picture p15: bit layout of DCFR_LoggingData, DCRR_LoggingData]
BO_ 1162 DCFR_LoggingData: 7 DCFR
 SG_ doorLatchStatus_DCFR : 31|3@0+ (1,0) [0|0] ""  BGW,TOOL
 SG_ doorLatchDoorAjar_DCFR : 17|2@0+ (1,0) [0|0] ""  BGW,TOOL
 SG_ doorLatchDoorOpen_DCFR : 19|2@0+ (1,0) [0|0] ""  BGW,TOOL
 SG_ doorLatchPawlClosed_DCFR : 21|2@0+ (1,0) [0|0] ""  BGW,TOOL
 SG_ doorLatchCinchHome_DCFR : 23|2@0+ (1,0) [0|2] ""  BGW,TOOL
 SG_ doorStopSource_DCFR : 15|4@0+ (1,0) [0|0] ""  BGW,TOOL
 SG_ doorCloseSource_DCFR : 10|3@0+ (1,0) [0|0] ""  BGW,TOOL
 SG_ doorOpenSource_DCFR : 7|8@0+ (1,0) [0|0] ""  BGW,TOOL
 SG_ windowOpenSource_DCFR : 55|3@0+ (1,0) [0|2] ""  BGW,TOOL
 SG_ windowCloseSource_DCFR : 52|3@0+ (1,0) [0|2] ""  BGW,TOOL
 SG_ ecuUpTime_DCFR : 39|16@0+ (1,0) [0|65534] "Seconds"  BGW,TOOL

BO_ 1226 DCRR_LoggingData: 7 DCRR
 SG_ doorLatchStatus_DCRR : 31|3@0+ (1,0) [0|0] ""  BGW,TOOL
 SG_ doorLatchDoorAjar_DCRR : 17|2@0+ (1,0) [0|0] ""  BGW,TOOL
 SG_ doorLatchDoorOpen_DCRR : 19|2@0+ (1,0) [0|0] ""  BGW,TOOL
 SG_ doorLatchPawlClosed_DCRR : 21|2@0+ (1,0) [0|0] ""  BGW,TOOL
 SG_ doorLatchCinchHome_DCRR : 23|2@0+ (1,0) [0|2] ""  BGW,TOOL
 SG_ doorStopSource_DCRR : 15|4@0+ (1,0) [0|0] ""  BGW,TOOL
 SG_ doorCloseSource_DCRR : 10|3@0+ (1,0) [0|0] ""  BGW,TOOL
 SG_ doorOpenSource_DCRR : 7|8@0+ (1,0) [0|0] ""  BGW,TOOL
 SG_ windowOpenSource_DCRR : 55|3@0+ (1,0) [0|2] ""  BGW,TOOL
 SG_ windowCloseSource_DCRR : 52|3@0+ (1,0) [0|2] ""  BGW,TOOL
 SG_ ecuUpTime_DCRR : 39|16@0+ (1,0) [0|65534] "Seconds"  BGW,TOOL

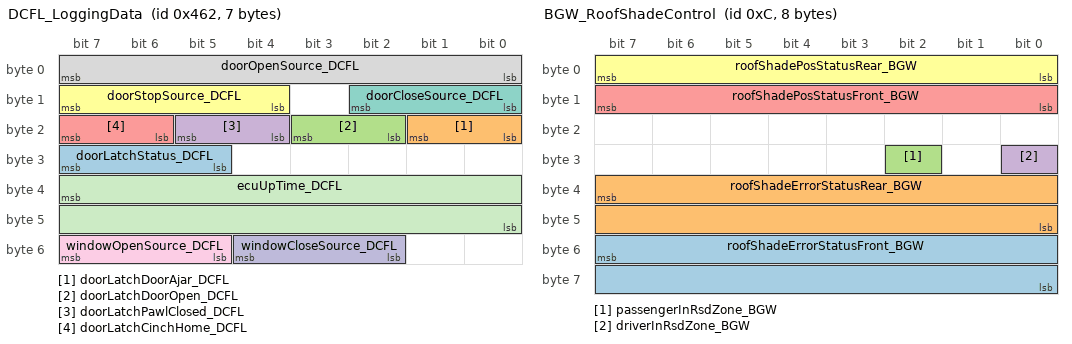
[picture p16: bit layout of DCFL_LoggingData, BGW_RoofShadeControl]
BO_ 1122 DCFL_LoggingData: 7 DCFL
 SG_ doorLatchStatus_DCFL : 31|3@0+ (1,0) [0|0] ""  BGW,TOOL
 SG_ doorLatchDoorAjar_DCFL : 17|2@0+ (1,0) [0|0] ""  BGW,TOOL
 SG_ doorLatchDoorOpen_DCFL : 19|2@0+ (1,0) [0|0] ""  BGW,TOOL
 SG_ doorLatchPawlClosed_DCFL : 21|2@0+ (1,0) [0|0] ""  BGW,TOOL
 SG_ doorLatchCinchHome_DCFL : 23|2@0+ (1,0) [0|2] ""  BGW,TOOL
 SG_ doorStopSource_DCFL : 15|4@0+ (1,0) [0|0] ""  BGW,TOOL
 SG_ doorCloseSource_DCFL : 10|3@0+ (1,0) [0|0] ""  BGW,TOOL
 SG_ doorOpenSource_DCFL : 7|8@0+ (1,0) [0|0] ""  BGW,TOOL
 SG_ windowOpenSource_DCFL : 55|3@0+ (1,0) [0|2] ""  BGW,TOOL
 SG_ windowCloseSource_DCFL : 52|3@0+ (1,0) [0|2] ""  BGW,TOOL
 SG_ ecuUpTime_DCFL : 39|16@0+ (1,0) [0|65534] "Seconds"  BGW,TOOL

BO_ 12 BGW_RoofShadeControl: 8 BGW
 SG_ roofShadeErrorStatusFront_BGW : 55|16@0+ (1,0) [0|65534] ""  TOOL
 SG_ roofShadeErrorStatusRear_BGW : 39|16@0+ (1,0) [0|65534] ""  TOOL
 SG_ passengerInRsdZone_BGW : 26|1@0+ (1,0) [0|1] ""  FBCM
 SG_ driverInRsdZone_BGW : 24|1@0+ (1,0) [0|1] ""  FBCM
 SG_ roofShadePosStatusFront_BGW : 15|8@0+ (0.394,0) [0|100] "Percent"  FBCM
 SG_ roofShadePosStatusRear_BGW : 7|8@0+ (0.394,0) [0|100] "Percent"  FBCM

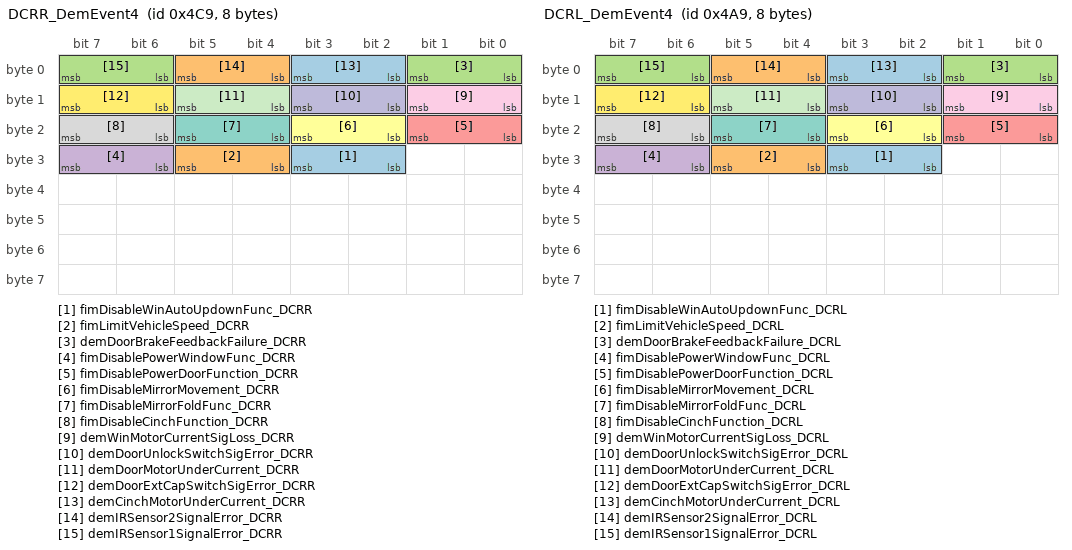
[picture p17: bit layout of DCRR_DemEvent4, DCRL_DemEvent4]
BO_ 1225 DCRR_DemEvent4: 8 DCRR
 SG_ fimDisableWinAutoUpdownFunc_DCRR : 27|2@0+ (1,0) [0|2] ""  TOOL
 SG_ fimLimitVehicleSpeed_DCRR : 29|2@0+ (1,0) [0|2] ""  TOOL
 SG_ demDoorBrakeFeedbackFailure_DCRR : 1|2@0+ (1,0) [0|0] ""  TOOL
 SG_ fimDisablePowerWindowFunc_DCRR : 31|2@0+ (1,0) [0|2] ""  TOOL
 SG_ fimDisablePowerDoorFunction_DCRR : 17|2@0+ (1,0) [0|2] ""  TOOL
 SG_ fimDisableMirrorMovement_DCRR : 19|2@0+ (1,0) [0|2] ""  TOOL
 SG_ fimDisableMirrorFoldFunc_DCRR : 21|2@0+ (1,0) [0|2] ""  TOOL
 SG_ fimDisableCinchFunction_DCRR : 23|2@0+ (1,0) [0|2] ""  TOOL
 SG_ demWinMotorCurrentSigLoss_DCRR : 9|2@0+ (1,0) [0|0] ""  TOOL
 SG_ demDoorUnlockSwitchSigError_DCRR : 11|2@0+ (1,0) [0|0] ""  TOOL
 SG_ demDoorMotorUnderCurrent_DCRR : 13|2@0+ (1,0) [0|0] ""  TOOL
 SG_ demDoorExtCapSwitchSigError_DCRR : 15|2@0+ (1,0) [0|0] ""  TOOL
 SG_ demCinchMotorUnderCurrent_DCRR : 3|2@0+ (1,0) [0|0] ""  TOOL
 SG_ demIRSensor2SignalError_DCRR : 5|2@0+ (1,0) [0|0] ""  TOOL
 SG_ demIRSensor1SignalError_DCRR : 7|2@0+ (1,0) [0|0] ""  TOOL

BO_ 1193 DCRL_DemEvent4: 8 DCRL
 SG_ fimDisableWinAutoUpdownFunc_DCRL : 27|2@0+ (1,0) [0|2] ""  TOOL
 SG_ fimLimitVehicleSpeed_DCRL : 29|2@0+ (1,0) [0|2] ""  TOOL
 SG_ demDoorBrakeFeedbackFailure_DCRL : 1|2@0+ (1,0) [0|0] ""  TOOL
 SG_ fimDisablePowerWindowFunc_DCRL : 31|2@0+ (1,0) [0|2] ""  TOOL
 SG_ fimDisablePowerDoorFunction_DCRL : 17|2@0+ (1,0) [0|2] ""  TOOL
 SG_ fimDisableMirrorMovement_DCRL : 19|2@0+ (1,0) [0|2] ""  TOOL
 SG_ fimDisableMirrorFoldFunc_DCRL : 21|2@0+ (1,0) [0|2] ""  TOOL
 SG_ fimDisableCinchFunction_DCRL : 23|2@0+ (1,0) [0|2] ""  TOOL
 SG_ demWinMotorCurrentSigLoss_DCRL : 9|2@0+ (1,0) [0|0] ""  TOOL
 SG_ demDoorUnlockSwitchSigError_DCRL : 11|2@0+ (1,0) [0|0] ""  TOOL
 SG_ demDoorMotorUnderCurrent_DCRL : 13|2@0+ (1,0) [0|0] ""  TOOL
 SG_ demDoorExtCapSwitchSigError_DCRL : 15|2@0+ (1,0) [0|0] ""  TOOL
 SG_ demCinchMotorUnderCurrent_DCRL : 3|2@0+ (1,0) [0|0] ""  TOOL
 SG_ demIRSensor2SignalError_DCRL : 5|2@0+ (1,0) [0|0] ""  TOOL
 SG_ demIRSensor1SignalError_DCRL : 7|2@0+ (1,0) [0|0] ""  TOOL

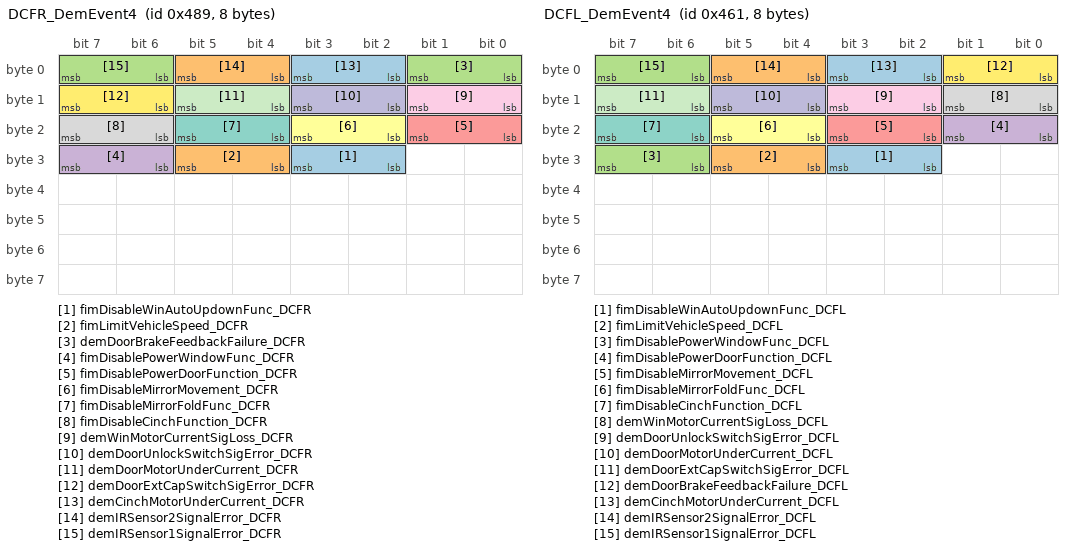
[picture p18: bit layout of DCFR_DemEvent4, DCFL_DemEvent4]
BO_ 1161 DCFR_DemEvent4: 8 DCFR
 SG_ fimDisableWinAutoUpdownFunc_DCFR : 27|2@0+ (1,0) [0|2] ""  TOOL
 SG_ fimLimitVehicleSpeed_DCFR : 29|2@0+ (1,0) [0|2] ""  TOOL
 SG_ demDoorBrakeFeedbackFailure_DCFR : 1|2@0+ (1,0) [0|0] ""  TOOL
 SG_ fimDisablePowerWindowFunc_DCFR : 31|2@0+ (1,0) [0|2] ""  TOOL
 SG_ fimDisablePowerDoorFunction_DCFR : 17|2@0+ (1,0) [0|2] ""  TOOL
 SG_ fimDisableMirrorMovement_DCFR : 19|2@0+ (1,0) [0|2] ""  TOOL
 SG_ fimDisableMirrorFoldFunc_DCFR : 21|2@0+ (1,0) [0|2] ""  TOOL
 SG_ fimDisableCinchFunction_DCFR : 23|2@0+ (1,0) [0|2] ""  TOOL
 SG_ demWinMotorCurrentSigLoss_DCFR : 9|2@0+ (1,0) [0|0] ""  TOOL
 SG_ demDoorUnlockSwitchSigError_DCFR : 11|2@0+ (1,0) [0|0] ""  TOOL
 SG_ demDoorMotorUnderCurrent_DCFR : 13|2@0+ (1,0) [0|0] ""  TOOL
 SG_ demDoorExtCapSwitchSigError_DCFR : 15|2@0+ (1,0) [0|0] ""  TOOL
 SG_ demCinchMotorUnderCurrent_DCFR : 3|2@0+ (1,0) [0|0] ""  TOOL
 SG_ demIRSensor2SignalError_DCFR : 5|2@0+ (1,0) [0|0] ""  TOOL
 SG_ demIRSensor1SignalError_DCFR : 7|2@0+ (1,0) [0|0] ""  TOOL

BO_ 1121 DCFL_DemEvent4: 8 DCFL
 SG_ fimDisableWinAutoUpdownFunc_DCFL : 27|2@0+ (1,0) [0|2] ""  TOOL
 SG_ fimLimitVehicleSpeed_DCFL : 29|2@0+ (1,0) [0|2] ""  TOOL
 SG_ fimDisablePowerWindowFunc_DCFL : 31|2@0+ (1,0) [0|2] ""  TOOL
 SG_ fimDisablePowerDoorFunction_DCFL : 17|2@0+ (1,0) [0|2] ""  TOOL
 SG_ fimDisableMirrorMovement_DCFL : 19|2@0+ (1,0) [0|2] ""  TOOL
 SG_ fimDisableMirrorFoldFunc_DCFL : 21|2@0+ (1,0) [0|2] ""  TOOL
 SG_ fimDisableCinchFunction_DCFL : 23|2@0+ (1,0) [0|2] ""  TOOL
 SG_ demWinMotorCurrentSigLoss_DCFL : 9|2@0+ (1,0) [0|0] ""  TOOL
 SG_ demDoorUnlockSwitchSigError_DCFL : 11|2@0+ (1,0) [0|0] ""  TOOL
 SG_ demDoorMotorUnderCurrent_DCFL : 13|2@0+ (1,0) [0|0] ""  TOOL
 SG_ demDoorExtCapSwitchSigError_DCFL : 15|2@0+ (1,0) [0|0] ""  TOOL
 SG_ demDoorBrakeFeedbackFailure_DCFL : 1|2@0+ (1,0) [0|0] ""  TOOL
 SG_ demCinchMotorUnderCurrent_DCFL : 3|2@0+ (1,0) [0|0] ""  TOOL
 SG_ demIRSensor2SignalError_DCFL : 5|2@0+ (1,0) [0|0] ""  TOOL
 SG_ demIRSensor1SignalError_DCFL : 7|2@0+ (1,0) [0|0] ""  TOOL

BO_ 13 BGW_DemEvent1: 8 BGW
 SG_ demDEMNotification_BGW : 63|2@0+ (1,0) [0|0] ""  TOOL
 SG_ demDEMAssert_BGW : 49|2@0+ (1,0) [0|0] ""  TOOL
 SG_ demLIN2Unresponsive_BGW : 51|2@0+ (1,0) [0|0] ""  TOOL
 SG_ demLIN1Unresponsive_BGW : 53|2@0+ (1,0) [0|0] ""  TOOL
 SG_ demTelematicsCANNetworkError_BGW : 55|2@0+ (1,0) [0|0] ""  TOOL
 SG_ demThermalCANNetworkError_BGW : 41|2@0+ (1,0) [0|0] ""  TOOL
 SG_ demEthernetIHUBMIA_BGW : 43|2@0+ (1,0) [0|0] ""  TOOL
 SG_ demEthernetSDCMMIA_BGW : 45|2@0+ (1,0) [0|0] ""  TOOL
 SG_ demEthernetUnresponsive_BGW : 47|2@0+ (1,0) [0|0] ""  TOOL
 SG_ demRearFogLightNoCurrent_BGW : 33|2@0+ (1,0) [0|0] ""  TOOL
 SG_ demFBCMWakeInMIA_BGW : 35|2@0+ (1,0) [0|0] ""  TOOL
 SG_ demDCFRWakeInMIA_BGW : 37|2@0+ (1,0) [0|0] ""  TOOL
 SG_ demDCFLWakeInMIA_BGW : 39|2@0+ (1,0) [0|0] ""  TOOL
 SG_ demLiftgateLatchHomeSnLoss_BGW : 25|2@0+ (1,0) [0|0] ""  TOOL
 SG_ demLiftgatePawlSignalMissing_BGW : 27|2@0+ (1,0) [0|0] ""  TOOL
 SG_ demLiftgateAjarSignalMissing_BGW : 29|2@0+ (1,0) [0|0] ""  TOOL
 SG_ demLiftgateOpenSignalMissing_BGW : 31|2@0+ (1,0) [0|0] ""  TOOL
 SG_ demLiftgateHallSnsRtSnLoss_BGW : 17|2@0+ (1,0) [0|0] ""  TOOL
 SG_ demLiftgateHallSnsLeftSnLoss_BGW : 19|2@0+ (1,0) [0|0] ""  TOOL
 SG_ demLiftgateMotorRightOvCrn_BGW : 21|2@0+ (1,0) [0|0] ""  TOOL
 SG_ demLiftgateMotorRightSnLoss_BGW : 23|2@0+ (1,0) [0|0] ""  TOOL
 SG_ demLiftgateMotorRightSnErr_BGW : 9|2@0+ (1,0) [0|0] ""  TOOL
 SG_ demLiftgateMotorOvercurrent_BGW : 11|2@0+ (1,0) [0|0] ""  TOOL
 SG_ demLiftgateMotorLeftSnLoss_BGW : 13|2@0+ (1,0) [0|0] ""  TOOL
 SG_ demLiftgateMotorLeftSnErr_BGW : 15|2@0+ (1,0) [0|0] ""  TOOL
 SG_ demLiftgateFailsToClose_BGW : 1|2@0+ (1,0) [0|0] ""  TOOL
 SG_ demLiftgateClosesUncommanded_BGW : 3|2@0+ (1,0) [0|0] ""  TOOL
 SG_ demLgMotorOpAttLt_BGW : 5|2@0+ (1,0) [0|0] ""  TOOL
 SG_ demLiftgateMotorFailsToOpen_BGW : 7|2@0+ (1,0) [0|0] ""  TOOL

BO_ 1224 DCRR_DemEvent3: 8 DCRR
 SG_ demIntOpenSwSnLoss_DCRR : 1|2@0+ (1,0) [0|0] ""  TOOL
 SG_ demIntRelSwSnEr_DCRR : 3|2@0+ (1,0) [0|0] ""  TOOL
 SG_ demInteriorReleaseSwSnLoss_DCRR : 5|2@0+ (1,0) [0|0] ""  TOOL
 SG_ demDoorUnlockSwSnError_DCRR : 7|2@0+ (1,0) [0|0] ""  TOOL
 SG_ demMirrorGlassPosNotReached_DCRR : 9|2@0+ (1,0) [0|0] ""  TOOL
 SG_ demMirrorGlassMvtUcmd_DCRR : 11|2@0+ (1,0) [0|0] ""  TOOL
 SG_ demMirrorGlassMvFail_DCRR : 13|2@0+ (1,0) [0|0] ""  TOOL
 SG_ demIntOpenSwSnEr_DCRR : 15|2@0+ (1,0) [0|0] ""  TOOL
 SG_ demMirrorGlassPosSnsShCir_DCRR : 17|2@0+ (1,0) [0|0] ""  TOOL
 SG_ demMirrorGlassPosSnsOpenCir_DCRR : 19|2@0+ (1,0) [0|0] ""  TOOL
 SG_ demMirrorGlassPosSnsSnEr_DCRR : 21|2@0+ (1,0) [0|0] ""  TOOL
 SG_ demMirrorGlassPosSnsSnLoss_DCRR : 23|2@0+ (1,0) [0|0] ""  TOOL
 SG_ demBodyCANIMUMsgMiss_DCRR : 25|2@0+ (1,0) [0|0] ""  TOOL
 SG_ demBodyCANVehSpdMsgErr_DCRR : 27|2@0+ (1,0) [0|0] ""  TOOL
 SG_ demBodyCANVehSpdMsgMiss_DCRR : 29|2@0+ (1,0) [0|0] ""  TOOL
 SG_ demBodyCANNetworkFailure_DCRR : 31|2@0+ (1,0) [0|0] ""  TOOL
 SG_ demBodyCANLkUnlkMsgMiss_DCRR : 33|2@0+ (1,0) [0|0] ""  TOOL
 SG_ demBodyCANOpClMsgErr_DCRR : 35|2@0+ (1,0) [0|0] ""  TOOL
 SG_ demBodyCANOpClMsgMiss_DCRR : 37|2@0+ (1,0) [0|0] ""  TOOL
 SG_ demBodyCANIMUMessageError_DCRR : 39|2@0+ (1,0) [0|0] ""  TOOL
 SG_ demBodyCANCrashMsgMiss_DCRR : 41|2@0+ (1,0) [0|0] ""  TOOL
 SG_ demBodyCANChildLkMsgErr_DCRR : 43|2@0+ (1,0) [0|0] ""  TOOL
 SG_ demBodyCANChildLkMsgMiss_DCRR : 45|2@0+ (1,0) [0|0] ""  TOOL
 SG_ demBodyCANLockMessageError_DCRR : 47|2@0+ (1,0) [0|0] ""  TOOL
 SG_ demLINNetworkFail_DCRR : 49|2@0+ (1,0) [0|0] ""  TOOL
 SG_ demBodyCANAmbTempMsgErr_DCRR : 51|2@0+ (1,0) [0|0] ""  TOOL
 SG_ demBodyCANAmbTempMsgMiss_DCRR : 53|2@0+ (1,0) [0|0] ""  TOOL
 SG_ demBodyCANCrashMsgErr_DCRR : 55|2@0+ (1,0) [0|0] ""  TOOL
 SG_ demIRSensor2MIA_DCRR : 57|2@0+ (1,0) [0|0] ""  TOOL
 SG_ demIRSensor1MIA_DCRR : 59|2@0+ (1,0) [0|0] ""  TOOL
 SG_ demWinSwErr_DCRR : 61|2@0+ (1,0) [0|0] ""  TOOL
 SG_ demWinSwMIA_DCRR : 63|2@0+ (1,0) [0|0] ""  TOOL

BO_ 719 DCRR_DemEvent2: 8 DCRR
 SG_ demDoorLockSwitchSignalLoss_DCRR : 57|2@0+ (1,0) [0|0] ""  TOOL
 SG_ demDoorExtCapSwSnEr_DCRR : 59|2@0+ (1,0) [0|0] ""  TOOL
 SG_ demDoorExtCapSwSnLoss_DCRR : 61|2@0+ (1,0) [0|0] ""  TOOL
 SG_ demDoorExtCapSwPower_DCRR : 63|2@0+ (1,0) [0|0] ""  TOOL
 SG_ demDoorExtCapSwNoPower_DCRR : 49|2@0+ (1,0) [0|0] ""  TOOL
 SG_ demDoorExtMechSwSnEr_DCRR : 51|2@0+ (1,0) [0|0] ""  TOOL
 SG_ demDoorExtMechSwSnLoss_DCRR : 53|2@0+ (1,0) [0|0] ""  TOOL
 SG_ demDoorExtMechSwPower_DCRR : 55|2@0+ (1,0) [0|0] ""  TOOL
 SG_ demDoorExtMechSwPowerLoss_DCRR : 41|2@0+ (1,0) [0|0] ""  TOOL
 SG_ demWindowHallSignalError_DCRR : 43|2@0+ (1,0) [0|0] ""  TOOL
 SG_ demWindowHallSnsPowerLoss_DCRR : 45|2@0+ (1,0) [0|0] ""  TOOL
 SG_ demWindowHallSignalLoss_DCRR : 47|2@0+ (1,0) [0|0] ""  TOOL
 SG_ demWindowVelocityTimeout_DCRR : 33|2@0+ (1,0) [0|0] ""  TOOL
 SG_ demCinchCloseSignalError_DCRR : 35|2@0+ (1,0) [0|0] ""  TOOL
 SG_ demReverseCinchTimeout_DCRR : 37|2@0+ (1,0) [0|0] ""  TOOL
 SG_ demCinchOpenSignalError_DCRR : 39|2@0+ (1,0) [0|0] ""  TOOL
 SG_ demDoorCinchTimeout_DCRR : 25|2@0+ (1,0) [0|0] ""  TOOL
 SG_ demDoorLatchOpenAlwaysOn_DCRR : 27|2@0+ (1,0) [0|0] ""  TOOL
 SG_ demDoorLatchOpenPowerLoss_DCRR : 29|2@0+ (1,0) [0|0] ""  TOOL
 SG_ demDoorLatchOpenSignalError_DCRR : 31|2@0+ (1,0) [0|0] ""  TOOL
 SG_ demDoorLatchOpenSignalLoss_DCRR : 17|2@0+ (1,0) [0|0] ""  TOOL
 SG_ demDoorLatchPawlSignalError_DCRR : 19|2@0+ (1,0) [0|0] ""  TOOL
 SG_ demDoorLatchPawlSignalLoss_DCRR : 21|2@0+ (1,0) [0|0] ""  TOOL
 SG_ demDoorLatchSensorSnError_DCRR : 23|2@0+ (1,0) [0|0] ""  TOOL
 SG_ demDoorLatchAjarSigLoss_DCRR : 9|2@0+ (1,0) [0|0] ""  TOOL
 SG_ demDoorBrakeHallSnLoss_DCRR : 11|2@0+ (1,0) [0|0] ""  TOOL
 SG_ demDoorHallSensorSnErr_DCRR : 13|2@0+ (1,0) [0|0] ""  TOOL
 SG_ doorHallSensorSlow_DCRR : 15|2@0+ (1,0) [0|0] ""  TOOL
 SG_ demDoorHallSensorFast_DCRR : 1|2@0+ (1,0) [0|0] ""  TOOL
 SG_ demDoorHallSensorSignalLoss_DCRR : 3|2@0+ (1,0) [0|0] ""  TOOL
 SG_ demMirrorMovetUncmd_DCRR : 5|2@0+ (1,0) [0|0] ""  TOOL
 SG_ demMirrorMovementFailure_DCRR : 7|2@0+ (1,0) [0|0] ""  TOOL

BO_ 718 DCRR_DemEvent1: 8 DCRR
 SG_ demDEMNotification_DCRR : 31|2@0+ (1,0) [0|0] ""  TOOL
 SG_ demDEMAssert_DCRR : 1|2@0+ (1,0) [0|0] ""  TOOL
 SG_ demWindowDownFailure_DCRR : 57|2@0+ (1,0) [0|0] ""  TOOL
 SG_ demWindowDownUncommanded_DCRR : 59|2@0+ (1,0) [0|0] ""  TOOL
 SG_ demWindowUpUncommanded_DCRR : 61|2@0+ (1,0) [0|0] ""  TOOL
 SG_ demWindowUpFailure_DCRR : 63|2@0+ (1,0) [0|0] ""  TOOL
 SG_ demDoorCinchUncommanded_DCRR : 49|2@0+ (1,0) [0|0] ""  TOOL
 SG_ demDoorCinchReleaseFailure_DCRR : 51|2@0+ (1,0) [0|0] ""  TOOL
 SG_ demDoorMovementFault_DCRR : 53|2@0+ (1,0) [0|0] ""  TOOL
 SG_ demDoorCloseUncommanded_DCRR : 55|2@0+ (1,0) [0|0] ""  TOOL
 SG_ demDoorCloseFailure_DCRR : 41|2@0+ (1,0) [0|0] ""  TOOL
 SG_ demLatchTimeout_DCRR : 43|2@0+ (1,0) [0|0] ""  TOOL
 SG_ demDoorDirectionFault_DCRR : 45|2@0+ (1,0) [0|0] ""  TOOL
 SG_ demDoorOpenUncommanded_DCRR : 47|2@0+ (1,0) [0|0] ""  TOOL
 SG_ demDoorOpenFailure_DCRR : 33|2@0+ (1,0) [0|0] ""  TOOL
 SG_ demMirrorMotorSignalLoss_DCRR : 35|2@0+ (1,0) [0|0] ""  TOOL
 SG_ demMirrorMotorOvercurrent_DCRR : 37|2@0+ (1,0) [0|0] ""  TOOL
 SG_ demWindowMotorSignalLoss_DCRR : 39|2@0+ (1,0) [0|0] ""  TOOL
 SG_ demWindowCurrentFailure_DCRR : 25|2@0+ (1,0) [0|0] ""  TOOL
 SG_ demWindowMotorUndercurrent_DCRR : 27|2@0+ (1,0) [0|0] ""  TOOL
 SG_ demWindowMotorOvercurrent_DCRR : 29|2@0+ (1,0) [0|0] ""  TOOL
 SG_ demCinchMotorPowerLoss_DCRR : 17|2@0+ (1,0) [0|0] ""  TOOL
 SG_ demCinchMotorOvercurrent_DCRR : 19|2@0+ (1,0) [0|0] ""  TOOL
 SG_ demLatchUncommandedOpen_DCRR : 21|2@0+ (1,0) [0|0] ""  TOOL
 SG_ demDoorLatchStateError_DCRR : 23|2@0+ (1,0) [0|0] ""  TOOL
 SG_ demDoorLatchPowerLoss_DCRR : 9|2@0+ (1,0) [0|0] ""  TOOL
 SG_ demLatchMotorOvercurrent_DCRR : 11|2@0+ (1,0) [0|0] ""  TOOL
 SG_ demDoorBrakeMotorSignalLoss_DCRR : 13|2@0+ (1,0) [0|0] ""  TOOL
 SG_ demDoorBrakeOvercurrent_DCRR : 15|2@0+ (1,0) [0|0] ""  TOOL
 SG_ demDoorCurrentSignalLoss_DCRR : 3|2@0+ (1,0) [0|0] ""  TOOL
 SG_ demDoorMotorCurrentFailure_DCRR : 5|2@0+ (1,0) [0|0] ""  TOOL
 SG_ demDoorMotorOvercurrent_DCRR : 7|2@0+ (1,0) [0|0] ""  TOOL

BO_ 1192 DCRL_DemEvent3: 8 DCRL
 SG_ demIRSensor2MIA_DCRL : 57|2@0+ (1,0) [0|0] ""  TOOL
 SG_ demIRSensor1MIA_DCRL : 59|2@0+ (1,0) [0|0] ""  TOOL
 SG_ demWinSwErr_DCRL : 61|2@0+ (1,0) [0|0] ""  TOOL
 SG_ demWinSwMIA_DCRL : 63|2@0+ (1,0) [0|0] ""  TOOL
 SG_ demLINNetworkFail_DCRL : 49|2@0+ (1,0) [0|0] ""  TOOL
 SG_ demBodyCANAmbTempMsgErr_DCRL : 51|2@0+ (1,0) [0|0] ""  TOOL
 SG_ demBodyCANAmbTempMsgMiss_DCRL : 53|2@0+ (1,0) [0|0] ""  TOOL
 SG_ demBodyCANCrashMsgErr_DCRL : 55|2@0+ (1,0) [0|0] ""  TOOL
 SG_ demBodyCANCrashMsgMiss_DCRL : 41|2@0+ (1,0) [0|0] ""  TOOL
 SG_ demBodyCANChildLkMsgErr_DCRL : 43|2@0+ (1,0) [0|0] ""  TOOL
 SG_ demBodyCANChildLkMsgMiss_DCRL : 45|2@0+ (1,0) [0|0] ""  TOOL
 SG_ demBodyCANLockMessageError_DCRL : 47|2@0+ (1,0) [0|0] ""  TOOL
 SG_ demBodyCANLkUnlkMsgMiss_DCRL : 33|2@0+ (1,0) [0|0] ""  TOOL
 SG_ demBodyCANOpClMsgErr_DCRL : 35|2@0+ (1,0) [0|0] ""  TOOL
 SG_ demBodyCANOpClMsgMiss_DCRL : 37|2@0+ (1,0) [0|0] ""  TOOL
 SG_ demBodyCANIMUMessageError_DCRL : 39|2@0+ (1,0) [0|0] ""  TOOL
 SG_ demBodyCANIMUMsgMiss_DCRL : 25|2@0+ (1,0) [0|0] ""  TOOL
 SG_ demBodyCANVehSpdMsgErr_DCRL : 27|2@0+ (1,0) [0|0] ""  TOOL
 SG_ demBodyCANVehSpdMsgMiss_DCRL : 29|2@0+ (1,0) [0|0] ""  TOOL
 SG_ demBodyCANNetworkFailure_DCRL : 31|2@0+ (1,0) [0|0] ""  TOOL
 SG_ demMirrorGlassPosSnsShCir_DCRL : 17|2@0+ (1,0) [0|0] ""  TOOL
 SG_ demMirrorGlassPosSnsOpenCir_DCRL : 19|2@0+ (1,0) [0|0] ""  TOOL
 SG_ demMirrorGlassPosSnsSnEr_DCRL : 21|2@0+ (1,0) [0|0] ""  TOOL
 SG_ demMirrorGlassPosSnsSnLoss_DCRL : 23|2@0+ (1,0) [0|0] ""  TOOL
 SG_ demMirrorGlassPosNotReached_DCRL : 9|2@0+ (1,0) [0|0] ""  TOOL
 SG_ demMirrorGlassMvtUcmd_DCRL : 11|2@0+ (1,0) [0|0] ""  TOOL
 SG_ demMirrorGlassMvFail_DCRL : 13|2@0+ (1,0) [0|0] ""  TOOL
 SG_ demIntOpenSwSnEr_DCRL : 15|2@0+ (1,0) [0|0] ""  TOOL
 SG_ demIntOpenSwSnLoss_DCRL : 1|2@0+ (1,0) [0|0] ""  TOOL
 SG_ demIntRelSwSnEr_DCRL : 3|2@0+ (1,0) [0|0] ""  TOOL
 SG_ demInteriorReleaseSwSnLoss_DCRL : 5|2@0+ (1,0) [0|0] ""  TOOL
 SG_ demDoorUnlockSwSnError_DCRL : 7|2@0+ (1,0) [0|0] ""  TOOL

BO_ 687 DCRL_DemEvent2: 8 DCRL
 SG_ demDoorLockSwitchSignalLoss_DCRL : 57|2@0+ (1,0) [0|0] ""  TOOL
 SG_ demDoorExtCapSwSnEr_DCRL : 59|2@0+ (1,0) [0|0] ""  TOOL
 SG_ demDoorExtCapSwSnLoss_DCRL : 61|2@0+ (1,0) [0|0] ""  TOOL
 SG_ demDoorExtCapSwPower_DCRL : 63|2@0+ (1,0) [0|0] ""  TOOL
 SG_ demDoorExtCapSwNoPower_DCRL : 49|2@0+ (1,0) [0|0] ""  TOOL
 SG_ demDoorExtMechSwSnEr_DCRL : 51|2@0+ (1,0) [0|0] ""  TOOL
 SG_ demDoorExtMechSwSnLoss_DCRL : 53|2@0+ (1,0) [0|0] ""  TOOL
 SG_ demDoorExtMechSwPower_DCRL : 55|2@0+ (1,0) [0|0] ""  TOOL
 SG_ demDoorExtMechSwPowerLoss_DCRL : 41|2@0+ (1,0) [0|0] ""  TOOL
 SG_ demWindowHallSignalError_DCRL : 43|2@0+ (1,0) [0|0] ""  TOOL
 SG_ demWindowHallSnsPowerLoss_DCRL : 45|2@0+ (1,0) [0|0] ""  TOOL
 SG_ demWindowHallSignalLoss_DCRL : 47|2@0+ (1,0) [0|0] ""  TOOL
 SG_ demWindowVelocityTimeout_DCRL : 33|2@0+ (1,0) [0|0] ""  TOOL
 SG_ demCinchCloseSignalError_DCRL : 35|2@0+ (1,0) [0|0] ""  TOOL
 SG_ demReverseCinchTimeout_DCRL : 37|2@0+ (1,0) [0|0] ""  TOOL
 SG_ demCinchOpenSignalError_DCRL : 39|2@0+ (1,0) [0|0] ""  TOOL
 SG_ demDoorCinchTimeout_DCRL : 25|2@0+ (1,0) [0|0] ""  TOOL
 SG_ demDoorLatchOpenAlwaysOn_DCRL : 27|2@0+ (1,0) [0|0] ""  TOOL
 SG_ demDoorLatchOpenPowerLoss_DCRL : 29|2@0+ (1,0) [0|0] ""  TOOL
 SG_ demDoorLatchOpenSignalError_DCRL : 31|2@0+ (1,0) [0|0] ""  TOOL
 SG_ demDoorLatchOpenSignalLoss_DCRL : 17|2@0+ (1,0) [0|0] ""  TOOL
 SG_ demDoorLatchPawlSignalError_DCRL : 19|2@0+ (1,0) [0|0] ""  TOOL
 SG_ demDoorLatchPawlSignalLoss_DCRL : 21|2@0+ (1,0) [0|0] ""  TOOL
 SG_ demDoorLatchSensorSnError_DCRL : 23|2@0+ (1,0) [0|0] ""  TOOL
 SG_ demDoorLatchAjarSigLoss_DCRL : 9|2@0+ (1,0) [0|0] ""  TOOL
 SG_ demDoorBrakeHallSnLoss_DCRL : 11|2@0+ (1,0) [0|0] ""  TOOL
 SG_ demDoorHallSensorSnErr_DCRL : 13|2@0+ (1,0) [0|0] ""  TOOL
 SG_ doorHallSensorSlow_DCRL : 15|2@0+ (1,0) [0|0] ""  TOOL
 SG_ demDoorHallSensorFast_DCRL : 1|2@0+ (1,0) [0|0] ""  TOOL
 SG_ demDoorHallSensorSignalLoss_DCRL : 3|2@0+ (1,0) [0|0] ""  TOOL
 SG_ demMirrorMovetUncmd_DCRL : 5|2@0+ (1,0) [0|0] ""  TOOL
 SG_ demMirrorMovementFailure_DCRL : 7|2@0+ (1,0) [0|0] ""  TOOL

BO_ 686 DCRL_DemEvent1: 8 DCRL
 SG_ demDEMNotification_DCRL : 31|2@0+ (1,0) [0|0] ""  TOOL
 SG_ demDEMAssert_DCRL : 1|2@0+ (1,0) [0|0] ""  TOOL
 SG_ demWindowDownFailure_DCRL : 57|2@0+ (1,0) [0|0] ""  TOOL
 SG_ demWindowDownUncommanded_DCRL : 59|2@0+ (1,0) [0|0] ""  TOOL
 SG_ demWindowUpUncommanded_DCRL : 61|2@0+ (1,0) [0|0] ""  TOOL
 SG_ demWindowUpFailure_DCRL : 63|2@0+ (1,0) [0|0] ""  TOOL
 SG_ demDoorCinchUncommanded_DCRL : 49|2@0+ (1,0) [0|0] ""  TOOL
 SG_ demDoorCinchReleaseFailure_DCRL : 51|2@0+ (1,0) [0|0] ""  TOOL
 SG_ demDoorMovementFault_DCRL : 53|2@0+ (1,0) [0|0] ""  TOOL
 SG_ demDoorCloseUncommanded_DCRL : 55|2@0+ (1,0) [0|0] ""  TOOL
 SG_ demDoorCloseFailure_DCRL : 41|2@0+ (1,0) [0|0] ""  TOOL
 SG_ demLatchTimeout_DCRL : 43|2@0+ (1,0) [0|0] ""  TOOL
 SG_ demDoorDirectionFault_DCRL : 45|2@0+ (1,0) [0|0] ""  TOOL
 SG_ demDoorOpenUncommanded_DCRL : 47|2@0+ (1,0) [0|0] ""  TOOL
 SG_ demDoorOpenFailure_DCRL : 33|2@0+ (1,0) [0|0] ""  TOOL
 SG_ demMirrorMotorSignalLoss_DCRL : 35|2@0+ (1,0) [0|0] ""  TOOL
 SG_ demMirrorMotorOvercurrent_DCRL : 37|2@0+ (1,0) [0|0] ""  TOOL
 SG_ demWindowMotorSignalLoss_DCRL : 39|2@0+ (1,0) [0|0] ""  TOOL
 SG_ demWindowCurrentFailure_DCRL : 25|2@0+ (1,0) [0|0] ""  TOOL
 SG_ demWindowMotorUndercurrent_DCRL : 27|2@0+ (1,0) [0|0] ""  TOOL
 SG_ demWindowMotorOvercurrent_DCRL : 29|2@0+ (1,0) [0|0] ""  TOOL
 SG_ demCinchMotorPowerLoss_DCRL : 17|2@0+ (1,0) [0|0] ""  TOOL
 SG_ demCinchMotorOvercurrent_DCRL : 19|2@0+ (1,0) [0|0] ""  TOOL
 SG_ demLatchUncommandedOpen_DCRL : 21|2@0+ (1,0) [0|0] ""  TOOL
 SG_ demDoorLatchStateError_DCRL : 23|2@0+ (1,0) [0|0] ""  TOOL
 SG_ demDoorLatchPowerLoss_DCRL : 9|2@0+ (1,0) [0|0] ""  TOOL
 SG_ demLatchMotorOvercurrent_DCRL : 11|2@0+ (1,0) [0|0] ""  TOOL
 SG_ demDoorBrakeMotorSignalLoss_DCRL : 13|2@0+ (1,0) [0|0] ""  TOOL
 SG_ demDoorBrakeOvercurrent_DCRL : 15|2@0+ (1,0) [0|0] ""  TOOL
 SG_ demDoorCurrentSignalLoss_DCRL : 3|2@0+ (1,0) [0|0] ""  TOOL
 SG_ demDoorMotorCurrentFailure_DCRL : 5|2@0+ (1,0) [0|0] ""  TOOL
 SG_ demDoorMotorOvercurrent_DCRL : 7|2@0+ (1,0) [0|0] ""  TOOL

BO_ 1120 DCFL_DemEvent3: 8 DCFL
 SG_ demIRSensor2MIA_DCFL : 57|2@0+ (1,0) [0|0] ""  TOOL
 SG_ demIRSensor1MIA_DCFL : 59|2@0+ (1,0) [0|0] ""  TOOL
 SG_ demWinSwErr_DCFL : 61|2@0+ (1,0) [0|0] ""  TOOL
 SG_ demWinSwMIA_DCFL : 63|2@0+ (1,0) [0|0] ""  TOOL
 SG_ demLINNetworkFail_DCFL : 49|2@0+ (1,0) [0|0] ""  TOOL
 SG_ demBodyCANAmbTempMsgErr_DCFL : 51|2@0+ (1,0) [0|0] ""  TOOL
 SG_ demBodyCANAmbTempMsgMiss_DCFL : 53|2@0+ (1,0) [0|0] ""  TOOL
 SG_ demBodyCANCrashMsgErr_DCFL : 55|2@0+ (1,0) [0|0] ""  TOOL
 SG_ demBodyCANCrashMsgMiss_DCFL : 41|2@0+ (1,0) [0|0] ""  TOOL
 SG_ demBodyCANChildLkMsgErr_DCFL : 43|2@0+ (1,0) [0|0] ""  TOOL
 SG_ demBodyCANChildLkMsgMiss_DCFL : 45|2@0+ (1,0) [0|0] ""  TOOL
 SG_ demBodyCANLockMessageError_DCFL : 47|2@0+ (1,0) [0|0] ""  TOOL
 SG_ demBodyCANLkUnlkMsgMiss_DCFL : 33|2@0+ (1,0) [0|0] ""  TOOL
 SG_ demBodyCANOpClMsgErr_DCFL : 35|2@0+ (1,0) [0|0] ""  TOOL
 SG_ demBodyCANOpClMsgMiss_DCFL : 37|2@0+ (1,0) [0|0] ""  TOOL
 SG_ demBodyCANIMUMessageError_DCFL : 39|2@0+ (1,0) [0|0] ""  TOOL
 SG_ demBodyCANIMUMsgMiss_DCFL : 25|2@0+ (1,0) [0|0] ""  TOOL
 SG_ demBodyCANVehSpdMsgErr_DCFL : 27|2@0+ (1,0) [0|0] ""  TOOL
 SG_ demBodyCANVehSpdMsgMiss_DCFL : 29|2@0+ (1,0) [0|0] ""  TOOL
 SG_ demBodyCANNetworkFailure_DCFL : 31|2@0+ (1,0) [0|0] ""  TOOL
 SG_ demMirrorGlassPosSnsShCir_DCFL : 17|2@0+ (1,0) [0|0] ""  TOOL
 SG_ demMirrorGlassPosSnsOpenCir_DCFL : 19|2@0+ (1,0) [0|0] ""  TOOL
 SG_ demMirrorGlassPosSnsSnEr_DCFL : 21|2@0+ (1,0) [0|0] ""  TOOL
 SG_ demMirrorGlassPosSnsSnLoss_DCFL : 23|2@0+ (1,0) [0|0] ""  TOOL
 SG_ demMirrorGlassPosNotReached_DCFL : 9|2@0+ (1,0) [0|0] ""  TOOL
 SG_ demMirrorGlassMvtUcmd_DCFL : 11|2@0+ (1,0) [0|0] ""  TOOL
 SG_ demMirrorGlassMvFail_DCFL : 13|2@0+ (1,0) [0|0] ""  TOOL
 SG_ demIntOpenSwSnEr_DCFL : 15|2@0+ (1,0) [0|0] ""  TOOL
 SG_ demIntOpenSwSnLoss_DCFL : 1|2@0+ (1,0) [0|0] ""  TOOL
 SG_ demIntRelSwSnEr_DCFL : 3|2@0+ (1,0) [0|0] ""  TOOL
 SG_ demInteriorReleaseSwSnLoss_DCFL : 5|2@0+ (1,0) [0|0] ""  TOOL
 SG_ demDoorUnlockSwSnError_DCFL : 7|2@0+ (1,0) [0|0] ""  TOOL

BO_ 615 DCFL_DemEvent2: 8 DCFL
 SG_ demDoorLockSwitchSignalLoss_DCFL : 57|2@0+ (1,0) [0|0] ""  TOOL
 SG_ demDoorExtCapSwSnEr_DCFL : 59|2@0+ (1,0) [0|0] ""  TOOL
 SG_ demDoorExtCapSwSnLoss_DCFL : 61|2@0+ (1,0) [0|0] ""  TOOL
 SG_ demDoorExtCapSwPower_DCFL : 63|2@0+ (1,0) [0|0] ""  TOOL
 SG_ demDoorExtCapSwNoPower_DCFL : 49|2@0+ (1,0) [0|0] ""  TOOL
 SG_ demDoorExtMechSwSnEr_DCFL : 51|2@0+ (1,0) [0|0] ""  TOOL
 SG_ demDoorExtMechSwSnLoss_DCFL : 53|2@0+ (1,0) [0|0] ""  TOOL
 SG_ demDoorExtMechSwPower_DCFL : 55|2@0+ (1,0) [0|0] ""  TOOL
 SG_ demDoorExtMechSwPowerLoss_DCFL : 41|2@0+ (1,0) [0|0] ""  TOOL
 SG_ demWindowHallSignalError_DCFL : 43|2@0+ (1,0) [0|0] ""  TOOL
 SG_ demWindowHallSnsPowerLoss_DCFL : 45|2@0+ (1,0) [0|0] ""  TOOL
 SG_ demWindowHallSignalLoss_DCFL : 47|2@0+ (1,0) [0|0] ""  TOOL
 SG_ demWindowVelocityTimeout_DCFL : 33|2@0+ (1,0) [0|0] ""  TOOL
 SG_ demCinchCloseSignalError_DCFL : 35|2@0+ (1,0) [0|0] ""  TOOL
 SG_ demReverseCinchTimeout_DCFL : 37|2@0+ (1,0) [0|0] ""  TOOL
 SG_ demCinchOpenSignalError_DCFL : 39|2@0+ (1,0) [0|0] ""  TOOL
 SG_ demDoorCinchTimeout_DCFL : 25|2@0+ (1,0) [0|0] ""  TOOL
 SG_ demDoorLatchOpenAlwaysOn_DCFL : 27|2@0+ (1,0) [0|0] ""  TOOL
 SG_ demDoorLatchOpenPowerLoss_DCFL : 29|2@0+ (1,0) [0|0] ""  TOOL
 SG_ demDoorLatchOpenSignalError_DCFL : 31|2@0+ (1,0) [0|0] ""  TOOL
 SG_ demDoorLatchOpenSignalLoss_DCFL : 17|2@0+ (1,0) [0|0] ""  TOOL
 SG_ demDoorLatchPawlSignalError_DCFL : 19|2@0+ (1,0) [0|0] ""  TOOL
 SG_ demDoorLatchPawlSignalLoss_DCFL : 21|2@0+ (1,0) [0|0] ""  TOOL
 SG_ demDoorLatchSensorSnError_DCFL : 23|2@0+ (1,0) [0|0] ""  TOOL
 SG_ demDoorLatchAjarSigLoss_DCFL : 9|2@0+ (1,0) [0|0] ""  TOOL
 SG_ demDoorBrakeHallSnLoss_DCFL : 11|2@0+ (1,0) [0|0] ""  TOOL
 SG_ demDoorHallSensorSnErr_DCFL : 13|2@0+ (1,0) [0|0] ""  TOOL
 SG_ doorHallSensorSlow_DCFL : 15|2@0+ (1,0) [0|0] ""  TOOL
 SG_ demDoorHallSensorFast_DCFL : 1|2@0+ (1,0) [0|0] ""  TOOL
 SG_ demDoorHallSensorSignalLoss_DCFL : 3|2@0+ (1,0) [0|0] ""  TOOL
 SG_ demMirrorMovetUncmd_DCFL : 5|2@0+ (1,0) [0|0] ""  TOOL
 SG_ demMirrorMovementFailure_DCFL : 7|2@0+ (1,0) [0|0] ""  TOOL

BO_ 614 DCFL_DemEvent1: 8 DCFL
 SG_ demDEMNotification_DCFL : 31|2@0+ (1,0) [0|0] ""  TOOL
 SG_ demDEMAssert_DCFL : 1|2@0+ (1,0) [0|0] ""  TOOL
 SG_ demWindowDownFailure_DCFL : 57|2@0+ (1,0) [0|0] ""  TOOL
 SG_ demWindowDownUncommanded_DCFL : 59|2@0+ (1,0) [0|0] ""  TOOL
 SG_ demWindowUpUncommanded_DCFL : 61|2@0+ (1,0) [0|0] ""  TOOL
 SG_ demWindowUpFailure_DCFL : 63|2@0+ (1,0) [0|0] ""  TOOL
 SG_ demDoorCinchUncommanded_DCFL : 49|2@0+ (1,0) [0|0] ""  TOOL
 SG_ demDoorCinchReleaseFailure_DCFL : 51|2@0+ (1,0) [0|0] ""  TOOL
 SG_ demDoorMovementFault_DCFL : 53|2@0+ (1,0) [0|0] ""  TOOL
 SG_ demDoorCloseUncommanded_DCFL : 55|2@0+ (1,0) [0|0] ""  TOOL
 SG_ demDoorCloseFailure_DCFL : 41|2@0+ (1,0) [0|0] ""  TOOL
 SG_ demLatchTimeout_DCFL : 43|2@0+ (1,0) [0|0] ""  TOOL
 SG_ demDoorDirectionFault_DCFL : 45|2@0+ (1,0) [0|0] ""  TOOL
 SG_ demDoorOpenUncommanded_DCFL : 47|2@0+ (1,0) [0|0] ""  TOOL
 SG_ demDoorOpenFailure_DCFL : 33|2@0+ (1,0) [0|0] ""  TOOL
 SG_ demMirrorMotorSignalLoss_DCFL : 35|2@0+ (1,0) [0|0] ""  TOOL
 SG_ demMirrorMotorOvercurrent_DCFL : 37|2@0+ (1,0) [0|0] ""  TOOL
 SG_ demWindowMotorSignalLoss_DCFL : 39|2@0+ (1,0) [0|0] ""  TOOL
 SG_ demWindowCurrentFailure_DCFL : 25|2@0+ (1,0) [0|0] ""  TOOL
 SG_ demWindowMotorUndercurrent_DCFL : 27|2@0+ (1,0) [0|0] ""  TOOL
 SG_ demWindowMotorOvercurrent_DCFL : 29|2@0+ (1,0) [0|0] ""  TOOL
 SG_ demCinchMotorPowerLoss_DCFL : 17|2@0+ (1,0) [0|0] ""  TOOL
 SG_ demCinchMotorOvercurrent_DCFL : 19|2@0+ (1,0) [0|0] ""  TOOL
 SG_ demLatchUncommandedOpen_DCFL : 21|2@0+ (1,0) [0|0] ""  TOOL
 SG_ demDoorLatchStateError_DCFL : 23|2@0+ (1,0) [0|0] ""  TOOL
 SG_ demDoorLatchPowerLoss_DCFL : 9|2@0+ (1,0) [0|0] ""  TOOL
 SG_ demLatchMotorOvercurrent_DCFL : 11|2@0+ (1,0) [0|0] ""  TOOL
 SG_ demDoorBrakeMotorSignalLoss_DCFL : 13|2@0+ (1,0) [0|0] ""  TOOL
 SG_ demDoorBrakeOvercurrent_DCFL : 15|2@0+ (1,0) [0|0] ""  TOOL
 SG_ demDoorCurrentSignalLoss_DCFL : 3|2@0+ (1,0) [0|0] ""  TOOL
 SG_ demDoorMotorCurrentFailure_DCFL : 5|2@0+ (1,0) [0|0] ""  TOOL
 SG_ demDoorMotorOvercurrent_DCFL : 7|2@0+ (1,0) [0|0] ""  TOOL

CM_ BU_ ACCL "Accessory Lamp";
CM_ BU_ BGW "Body Control Gateway";
CM_ BU_ DBPC "Driver B-Pillar Controller";
CM_ BU_ DCFL "Door Controller Front Left";
CM_ BU_ DCFR "Door Controller Front Right";
CM_ BU_ DCRL "Door Controller Rear Left";
CM_ BU_ DCRR "Door Controller Rear Right";
CM_ BU_ DSM "Driver Seat Module";
CM_ BU_ ECPM "Exterior Camera Processing Module";
CM_ BU_ FBCM "Front Body Control Module";
CM_ BU_ FFL "Front Facia Lighting";
CM_ BU_ FLDC "Front Left Door Cladding";
CM_ BU_ FRDC "Front Right Door Cladding";
CM_ BU_ HLL "Head Light Left ";
CM_ BU_ HLR "Head Light Right";
CM_ BU_ HUD "Heads Up Display (Receiver Only)";
CM_ BU_ IHUB "IPC portion of Infotainment Hub (Receiver Only)";
CM_ BU_ LGL "Lift Gate Lighting";
CM_ BU_ PSM "Passenger Seat Module";
CM_ BU_ RCLL "RCL Tail Lamp Left";
CM_ BU_ RCLR "RCL Tail Lamp Right";
CM_ BU_ RLDC "Rear Left Door Cladding";
CM_ BU_ RLSM "Rear Left Seat Module";
CM_ BU_ RRDC "Rear Right Door Cladding";
CM_ BU_ RRSM "Rear Right Seat Module";
CM_ BU_ TOOL "Diagnostic tool";
CM_ SG_ 1036 ambientLightSelection_IHUB "0x0 NoCommand
0x1 Amprr
0x2 Amprl
0x4 Ampfr
0x8 Ampfl
0x10 Aldrr
0x20 Aldrl
0x40 Aldfr
0x80 Aldfl
0x100 Domef
0x200 Alcpt
0x400 Flipr
0x800 Flipl
0x1000 Alcpr
0x2000 Alcpl
0x4000 Aflrr
0xFFFF SNA";
CM_ SG_ 1288 seatLegExtCmdRR_BGW "Command rear right leg extension to increment or decrement";
CM_ SG_ 1288 seatBackCmdRR_BGW "Command rear right seat backrest to increment or decrement";
CM_ SG_ 1288 seatBackCmdRL_BGW "Command rear left seat tilt to increment or decrement";
CM_ SG_ 1288 seatLegSwivelCmdRL_BGW "Command rear left seat leg swivel to increment or decrement";
CM_ SG_ 1288 seatLegSwivelCmdRR_BGW "Command rear right leg swivel to increment or decrement";
CM_ SG_ 1288 seatLegExtCmdRL_BGW "Command rear left seat leg extension to increment or decrement";
CM_ SG_ 1294 seatLegExtAbsPosRRSM_BGW "Set rear right seat leg extension position in millimeters.";
CM_ SG_ 1294 seatLegSwivelAbsPosRRSM_BGW "Set rear right seat leg swivel position in degrees.";
CM_ SG_ 1294 seatBackAbsPosRRSM_BGW "Set rear right seat back tilt position in degrees.";
CM_ SG_ 1289 seatTrackAbsPosPSM_BGW "Set passenger seat slide position in millimeters.";
CM_ SG_ 1289 seatLiftAbsPosPSM_BGW "Set passenger seat lift position in millimeters.";
CM_ SG_ 1289 seatBackAbsPosPSM_BGW "Set the passenger seat back tilt position in degrees.";
CM_ SG_ 780 chargeTargetSOE_BGW "User selected percentage for when to stop charging";
CM_ SG_ 11 autoLowBeamReq_IHUB "turn on or off the autoLowBeam for Rain Light Sensor";
CM_ SG_ 12 roofShadeErrorStatusFront_BGW "BIT = 1(Error) / BIT = 0(No Error) Bit 8: frontRoofShadeError | Bit 7: AntiPinchTriggerError | Bit 6: MotorStatusError | Bit 5: ThermalProtectError | Bit 4: BatteryError | Bit 3: NormalizationStatusError | Bit 2: RelayError | Bit 1: HallSensorError | Bit 0: linBusError ";
CM_ SG_ 12 roofShadeErrorStatusRear_BGW "BIT = 1(Error) / BIT = 0(No Error) Bit 8: rearRoofShadeError | Bit 7: AntiPinchTriggerError | Bit 6: MotorStatusError | Bit 5: ThermalProtectError | Bit 4: BatteryError | Bit 3: NormalizationStatusError | Bit 2: RelayError | Bit 1: HallSensorError | Bit 0: linBusError ";
BA_DEF_ BO_  "CloudLogRate" INT 0 65000;
BA_DEF_ SG_  "ExpirationValue" STRING ;
BA_DEF_ BU_  "ILUsed" ENUM  "No","Yes";
BA_DEF_ BU_  "NmDefaultAddress" ENUM  "USE_PRIMARY_ADDRESS","USE_SECONDARY_ADDRESS";
BA_DEF_ BU_  "NmHasSecondaryAddress" ENUM  "TRUE","FALSE";
BA_DEF_ BU_  "NmNode" ENUM  "No","Yes";
BA_DEF_ BU_  "NmSecondaryAddress" HEX 0 255;
BA_DEF_ BU_  "NmStationAddress" HEX 0 255;
BA_DEF_ BU_  "NodeLayerModules" STRING ;
BA_DEF_ BO_  "MsgTxIsRx" INT 0 1;
BA_DEF_ BO_  "DebugMessage" INT 0 1;
BA_DEF_ BO_  "DebugMessageTransmitAlways" INT 0 1;
BA_DEF_ BO_  "DiagRequest" ENUM  "No","Yes";
BA_DEF_ BO_  "GatewayHandlerEnum" ENUM  "noHandler","uds","alertLog","messageLogOnReception","udsClient";
BA_DEF_ BO_  "GatewayMessageSendType" ENUM  "UseGenMsgSendType","onWrite","noAutoCode";
BA_DEF_ BO_  "GenMsgCycleTime" INT 0 65000;
BA_DEF_ BO_  "GenMsgGatewayNotification" STRING ;
BA_DEF_ BO_  "GenMsgILSupport" ENUM  "No","Yes";
BA_DEF_ BO_  "GenMsgMinAcceptLength" INT 0 0;
BA_DEF_ BO_  "GenMsgSendType" ENUM  "Cyclic","IfActive","NoMsgSendType","OnEvent";
BA_DEF_ BO_  "GenMsgTimeoutTime" INT 0 10000;
BA_DEF_ BO_  "Type" ENUM  "-","P","E","PE","vector_leerstring";
BA_DEF_ BO_  "cycleMilliSecs100" INT 0 100;
BA_DEF_ BO_  "receiveMsgFromEthernet" INT 0 1;
BA_DEF_ BO_  "sendMsgToEthernet" INT 0 1;
BA_DEF_ BO_  "targetGw" ENUM  "BPG","BGW","IHUB","SDCM","BGW,IHUB","BGW,BPG","BPG,IHUB","SDCM,IHUB","SDCM,BGW","SDCM,BPG","ALL","SDCM,ADC","IHUB,ADC","IHUB,BGW,ADC","ADC","ADC,BGW","SDCM,ADC,IHUB";
BA_DEF_ BO_  "targetMsgECUs" ENUM  "BPG","BGW","IVI","SDCM","ALL","vector_leerstring";
BA_DEF_ BO_  "transmitMsgRateEthernetMs" ENUM  "100","1000","0","10000","250","500","10","20","40","200","50";
BA_DEF_ SG_  "GatewayedSignal" INT 0 1;
BA_DEF_ SG_  "GenSigEnvVarType" ENUM  "int","float","undef";
BA_DEF_ SG_  "GenSigInactiveValue" INT 0 0;
BA_DEF_ SG_  "GenSigSNA" STRING ;
BA_DEF_ SG_  "GenSigSendType" ENUM  "Cyclic","OnWrite","OnWriteWithRepetition","OnChange","OnChangeWithRepetition","IfActive","IfActiveWithRepetition","NoSigSendType";
BA_DEF_ SG_  "GenSigStartValue" INT 0 0;
BA_DEF_ SG_  "OriginatingECU" STRING ;
BA_DEF_ SG_  "SNARequired" ENUM  "Required","NotRequired";
BA_DEF_  "Baudrate" INT 0 1000000;
BA_DEF_  "BusECUIdLength" INT 5 6;
BA_DEF_  "BusID" INT 0 255;
BA_DEF_  "BusName" STRING ;
BA_DEF_  "BusType" STRING ;
BA_DEF_  "DBName" STRING ;
BA_DEF_  "GenNWMSleepTime" INT 0 10000000;
BA_DEF_  "ILTxTimeout" INT 0 10000;
BA_DEF_  "Manufacturer" STRING ;
BA_DEF_  "NBTMax" INT 0 255;
BA_DEF_  "NBTMin" INT 0 255;
BA_DEF_  "NetworkName" STRING ;
BA_DEF_  "NmMessageCount" INT 0 64;
BA_DEF_  "NmType" STRING ;
BA_DEF_  "SamplePointMax" FLOAT 0 100;
BA_DEF_  "SamplePointMin" FLOAT 0 100;
BA_DEF_  "Version" HEX 0 255;
BA_DEF_  "VersionWeek" INT 0 53;
BA_DEF_  "VersionYear" INT 0 99;
BA_DEF_  "Autogen_Version" STRING ;
BA_DEF_DEF_  "CloudLogRate" 1000;
BA_DEF_DEF_  "ExpirationValue" "";
BA_DEF_DEF_  "ILUsed" "No";
BA_DEF_DEF_  "NmDefaultAddress" "USE_PRIMARY_ADDRESS";
BA_DEF_DEF_  "NmHasSecondaryAddress" "FALSE";
BA_DEF_DEF_  "NmNode" "Yes";
BA_DEF_DEF_  "NmSecondaryAddress" 0;
BA_DEF_DEF_  "NmStationAddress" 0;
BA_DEF_DEF_  "NodeLayerModules" "CANoeILNLVector.dll";
BA_DEF_DEF_  "MsgTxIsRx" 0;
BA_DEF_DEF_  "DebugMessage" 0;
BA_DEF_DEF_  "DebugMessageTransmitAlways" 0;
BA_DEF_DEF_  "DiagRequest" "No";
BA_DEF_DEF_  "GatewayHandlerEnum" "noHandler";
BA_DEF_DEF_  "GatewayMessageSendType" "UseGenMsgSendType";
BA_DEF_DEF_  "GenMsgCycleTime" 0;
BA_DEF_DEF_  "GenMsgGatewayNotification" "";
BA_DEF_DEF_  "GenMsgILSupport" "Yes";
BA_DEF_DEF_  "GenMsgMinAcceptLength" 8;
BA_DEF_DEF_  "GenMsgSendType" "NoMsgSendType";
BA_DEF_DEF_  "GenMsgTimeoutTime" 0;
BA_DEF_DEF_  "Type" "";
BA_DEF_DEF_  "cycleMilliSecs100" 100;
BA_DEF_DEF_  "receiveMsgFromEthernet" 0;
BA_DEF_DEF_  "sendMsgToEthernet" 0;
BA_DEF_DEF_  "targetGw" "ALL";
BA_DEF_DEF_  "targetMsgECUs" "";
BA_DEF_DEF_  "transmitMsgRateEthernetMs" "1000";
BA_DEF_DEF_  "GatewayedSignal" 0;
BA_DEF_DEF_  "GenSigEnvVarType" "undef";
BA_DEF_DEF_  "GenSigInactiveValue" 0;
BA_DEF_DEF_  "GenSigSNA" "";
BA_DEF_DEF_  "GenSigSendType" "NoSigSendType";
BA_DEF_DEF_  "GenSigStartValue" 0;
BA_DEF_DEF_  "OriginatingECU" "";
BA_DEF_DEF_  "SNARequired" "Required";
BA_DEF_DEF_  "Baudrate" 125000;
BA_DEF_DEF_  "BusECUIdLength" 5;
BA_DEF_DEF_  "BusID" 0;
BA_DEF_DEF_  "BusName" "body";
BA_DEF_DEF_  "BusType" "";
BA_DEF_DEF_  "DBName" "";
BA_DEF_DEF_  "GenNWMSleepTime" 10000000;
BA_DEF_DEF_  "ILTxTimeout" 30;
BA_DEF_DEF_  "Manufacturer" "";
BA_DEF_DEF_  "NBTMax" 21;
BA_DEF_DEF_  "NBTMin" 9;
BA_DEF_DEF_  "NetworkName" "";
BA_DEF_DEF_  "NmMessageCount" 64;
BA_DEF_DEF_  "NmType" "";
BA_DEF_DEF_  "SamplePointMax" 81.25;
BA_DEF_DEF_  "SamplePointMin" 75;
BA_DEF_DEF_  "Version" 160;
BA_DEF_DEF_  "VersionWeek" 6;
BA_DEF_DEF_  "VersionYear" 7;
BA_DEF_DEF_  "Autogen_Version" "None";
BA_ "BusECUIdLength" 6;
BA_ "BusID" 64;
BA_ "BusName" "body_new";
BA_ "BusType" "CAN";
BA_ "Manufacturer" "FF";
BA_ "NBTMax" 20;
BA_ "NBTMin" 8;
BA_ "NetworkName" "FF";
BA_ "NmMessageCount" 32;
BA_ "NmType" "Vector";
BA_ "Autogen_Version" "1.3.48";
BA_ "DBName" "body";
BA_ "NmStationAddress" BU_ ACCL 34;
BA_ "ILUsed" BU_ BGW 1;
BA_ "NmHasSecondaryAddress" BU_ BGW 0;
BA_ "NmSecondaryAddress" BU_ BGW 33;
BA_ "NmStationAddress" BU_ BGW 1;
BA_ "NmStationAddress" BU_ DBPC 38;
BA_ "ILUsed" BU_ DCFL 1;
BA_ "NmStationAddress" BU_ DCFL 12;
BA_ "ILUsed" BU_ DCFR 1;
BA_ "NmStationAddress" BU_ DCFR 17;
BA_ "ILUsed" BU_ DCRL 1;
BA_ "NmStationAddress" BU_ DCRL 21;
BA_ "ILUsed" BU_ DCRR 1;
BA_ "NmStationAddress" BU_ DCRR 25;
BA_ "ILUsed" BU_ DSM 1;
BA_ "NmStationAddress" BU_ DSM 14;
BA_ "NmStationAddress" BU_ ECPM 36;
BA_ "ILUsed" BU_ FBCM 1;
BA_ "NmStationAddress" BU_ FBCM 2;
BA_ "ILUsed" BU_ FFL 1;
BA_ "NmStationAddress" BU_ FFL 40;
BA_ "ILUsed" BU_ FLDC 1;
BA_ "NmStationAddress" BU_ FLDC 41;
BA_ "ILUsed" BU_ FRDC 1;
BA_ "NmStationAddress" BU_ FRDC 42;
BA_ "ILUsed" BU_ HLL 1;
BA_ "NmStationAddress" BU_ HLL 8;
BA_ "ILUsed" BU_ HLR 1;
BA_ "NmStationAddress" BU_ HLR 9;
BA_ "ILUsed" BU_ HUD 1;
BA_ "NmStationAddress" BU_ HUD 20;
BA_ "ILUsed" BU_ IHUB 1;
BA_ "NmStationAddress" BU_ IHUB 10;
BA_ "NmStationAddress" BU_ LGL 29;
BA_ "ILUsed" BU_ PSM 1;
BA_ "NmStationAddress" BU_ PSM 18;
BA_ "NmStationAddress" BU_ RCLL 31;
BA_ "NmStationAddress" BU_ RCLR 32;
BA_ "ILUsed" BU_ RLDC 1;
BA_ "NmStationAddress" BU_ RLDC 43;
BA_ "ILUsed" BU_ RLSM 1;
BA_ "NmStationAddress" BU_ RLSM 22;
BA_ "ILUsed" BU_ RRDC 1;
BA_ "NmStationAddress" BU_ RRDC 44;
BA_ "ILUsed" BU_ RRSM 1;
BA_ "NmStationAddress" BU_ RRSM 26;
BA_ "GenMsgSendType" BO_ 632 0;
BA_ "GenMsgCycleTime" BO_ 632 100;
BA_ "GenMsgSendType" BO_ 664 0;
BA_ "GenMsgCycleTime" BO_ 664 100;
BA_ "GenMsgSendType" BO_ 696 0;
BA_ "GenMsgCycleTime" BO_ 696 100;
BA_ "GenMsgSendType" BO_ 736 0;
BA_ "GenMsgCycleTime" BO_ 736 100;
BA_ "GenMsgSendType" BO_ 808 0;
BA_ "GenMsgCycleTime" BO_ 808 100;
BA_ "GenMsgSendType" BO_ 872 0;
BA_ "GenMsgCycleTime" BO_ 872 100;
BA_ "GenMsgSendType" BO_ 880 0;
BA_ "GenMsgCycleTime" BO_ 880 100;
BA_ "GenMsgSendType" BO_ 888 0;
BA_ "GenMsgCycleTime" BO_ 888 100;
BA_ "transmitMsgRateEthernetMs" BO_ 1036 2;
BA_ "receiveMsgFromEthernet" BO_ 1036 1;
BA_ "transmitMsgRateEthernetMs" BO_ 683 5;
BA_ "targetGw" BO_ 683 2;
BA_ "sendMsgToEthernet" BO_ 683 1;
BA_ "GenMsgSendType" BO_ 683 0;
BA_ "GenMsgCycleTime" BO_ 683 500;
BA_ "transmitMsgRateEthernetMs" BO_ 715 5;
BA_ "targetGw" BO_ 715 2;
BA_ "sendMsgToEthernet" BO_ 715 1;
BA_ "GenMsgSendType" BO_ 715 0;
BA_ "GenMsgCycleTime" BO_ 715 500;
BA_ "transmitMsgRateEthernetMs" BO_ 1794 2;
BA_ "targetGw" BO_ 1794 2;
BA_ "sendMsgToEthernet" BO_ 1794 1;
BA_ "transmitMsgRateEthernetMs" BO_ 1786 2;
BA_ "targetGw" BO_ 1786 2;
BA_ "sendMsgToEthernet" BO_ 1786 1;
BA_ "transmitMsgRateEthernetMs" BO_ 1770 2;
BA_ "targetGw" BO_ 1770 2;
BA_ "sendMsgToEthernet" BO_ 1770 1;
BA_ "transmitMsgRateEthernetMs" BO_ 1810 2;
BA_ "targetGw" BO_ 1810 2;
BA_ "sendMsgToEthernet" BO_ 1810 1;
BA_ "transmitMsgRateEthernetMs" BO_ 531 0;
BA_ "targetGw" BO_ 531 2;
BA_ "sendMsgToEthernet" BO_ 531 1;
BA_ "GenMsgSendType" BO_ 531 0;
BA_ "GenMsgCycleTime" BO_ 531 100;
BA_ "GenMsgSendType" BO_ 521 3;
BA_ "GenMsgSendType" BO_ 522 3;
BA_ "targetGw" BO_ 780 2;
BA_ "transmitMsgRateEthernetMs" BO_ 823 2;
BA_ "targetGw" BO_ 823 2;
BA_ "sendMsgToEthernet" BO_ 823 1;
BA_ "transmitMsgRateEthernetMs" BO_ 723 2;
BA_ "targetGw" BO_ 723 2;
BA_ "sendMsgToEthernet" BO_ 723 1;
BA_ "transmitMsgRateEthernetMs" BO_ 871 2;
BA_ "targetGw" BO_ 871 2;
BA_ "sendMsgToEthernet" BO_ 871 1;
BA_ "transmitMsgRateEthernetMs" BO_ 691 2;
BA_ "targetGw" BO_ 691 2;
BA_ "sendMsgToEthernet" BO_ 691 1;
BA_ "transmitMsgRateEthernetMs" BO_ 863 2;
BA_ "targetGw" BO_ 863 2;
BA_ "sendMsgToEthernet" BO_ 863 1;
BA_ "transmitMsgRateEthernetMs" BO_ 1280 2;
BA_ "targetGw" BO_ 1280 2;
BA_ "sendMsgToEthernet" BO_ 1280 1;
BA_ "transmitMsgRateEthernetMs" BO_ 1272 2;
BA_ "targetGw" BO_ 1272 2;
BA_ "sendMsgToEthernet" BO_ 1272 1;
BA_ "transmitMsgRateEthernetMs" BO_ 659 2;
BA_ "targetGw" BO_ 659 2;
BA_ "sendMsgToEthernet" BO_ 659 1;
BA_ "transmitMsgRateEthernetMs" BO_ 1258 2;
BA_ "targetGw" BO_ 1258 2;
BA_ "sendMsgToEthernet" BO_ 1258 1;
BA_ "transmitMsgRateEthernetMs" BO_ 591 2;
BA_ "targetGw" BO_ 591 2;
BA_ "sendMsgToEthernet" BO_ 591 1;
BA_ "transmitMsgRateEthernetMs" BO_ 583 2;
BA_ "targetGw" BO_ 583 2;
BA_ "sendMsgToEthernet" BO_ 583 1;
BA_ "transmitMsgRateEthernetMs" BO_ 855 2;
BA_ "targetGw" BO_ 855 2;
BA_ "sendMsgToEthernet" BO_ 855 1;
BA_ "transmitMsgRateEthernetMs" BO_ 847 2;
BA_ "targetGw" BO_ 847 2;
BA_ "sendMsgToEthernet" BO_ 847 1;
BA_ "transmitMsgRateEthernetMs" BO_ 1345 2;
BA_ "targetGw" BO_ 1345 2;
BA_ "sendMsgToEthernet" BO_ 1345 1;
BA_ "transmitMsgRateEthernetMs" BO_ 806 2;
BA_ "targetGw" BO_ 806 2;
BA_ "sendMsgToEthernet" BO_ 806 1;
BA_ "transmitMsgRateEthernetMs" BO_ 627 2;
BA_ "targetGw" BO_ 627 2;
BA_ "sendMsgToEthernet" BO_ 627 1;
BA_ "transmitMsgRateEthernetMs" BO_ 1296 2;
BA_ "targetGw" BO_ 1296 2;
BA_ "sendMsgToEthernet" BO_ 1296 1;
BA_ "transmitMsgRateEthernetMs" BO_ 11 2;
BA_ "receiveMsgFromEthernet" BO_ 11 1;
BA_ "GenMsgSendType" BO_ 1194 3;
BA_ "transmitMsgRateEthernetMs" BO_ 1194 2;
BA_ "CloudLogRate" BO_ 1194 0;
BA_ "targetGw" BO_ 1194 2;
BA_ "sendMsgToEthernet" BO_ 1194 1;
BA_ "GenMsgSendType" BO_ 1162 3;
BA_ "transmitMsgRateEthernetMs" BO_ 1162 2;
BA_ "CloudLogRate" BO_ 1162 0;
BA_ "targetGw" BO_ 1162 2;
BA_ "sendMsgToEthernet" BO_ 1162 1;
BA_ "GenMsgSendType" BO_ 1226 3;
BA_ "transmitMsgRateEthernetMs" BO_ 1226 2;
BA_ "CloudLogRate" BO_ 1226 0;
BA_ "targetGw" BO_ 1226 2;
BA_ "sendMsgToEthernet" BO_ 1226 1;
BA_ "GenMsgSendType" BO_ 1122 3;
BA_ "transmitMsgRateEthernetMs" BO_ 1122 2;
BA_ "CloudLogRate" BO_ 1122 0;
BA_ "targetGw" BO_ 1122 2;
BA_ "sendMsgToEthernet" BO_ 1122 1;
BA_ "GenMsgSendType" BO_ 12 0;
BA_ "GenMsgCycleTime" BO_ 12 250;
BA_ "GenSigSendType" SG_ 1661 udsClientDataDEMFL_TOOL 1;
BA_ "SNARequired" SG_ 1661 udsClientDataDEMFL_TOOL 1;
BA_ "GenSigSendType" SG_ 1662 udsServerData_DEMFL 1;
BA_ "SNARequired" SG_ 1662 udsServerData_DEMFL 1;
BA_ "GenSigSendType" SG_ 1693 udsClientDataDEMFR_TOOL 1;
BA_ "SNARequired" SG_ 1693 udsClientDataDEMFR_TOOL 1;
BA_ "GenSigSendType" SG_ 1694 udsServerData_DEMFR 1;
BA_ "SNARequired" SG_ 1694 udsServerData_DEMFR 1;
BA_ "GenSigSendType" SG_ 1725 udsClientDataDEMRL_TOOL 1;
BA_ "SNARequired" SG_ 1725 udsClientDataDEMRL_TOOL 1;
BA_ "GenSigSendType" SG_ 1726 udsServerData_DEMRL 1;
BA_ "SNARequired" SG_ 1726 udsServerData_DEMRL 1;
BA_ "GenSigSendType" SG_ 1765 udsClientDataDEMRR_TOOL 1;
BA_ "SNARequired" SG_ 1765 udsClientDataDEMRR_TOOL 1;
BA_ "GenSigSendType" SG_ 1766 udsServerData_DEMRR 1;
BA_ "SNARequired" SG_ 1766 udsServerData_DEMRR 1;
BA_ "GenSigSendType" SG_ 1837 udsClientDataDOSFL_TOOL 1;
BA_ "SNARequired" SG_ 1837 udsClientDataDOSFL_TOOL 1;
BA_ "GenSigSendType" SG_ 1838 udsServerData_DOSFL 1;
BA_ "SNARequired" SG_ 1838 udsServerData_DOSFL 1;
BA_ "GenSigSendType" SG_ 1901 udsClientDataDOSFR_TOOL 1;
BA_ "SNARequired" SG_ 1901 udsClientDataDOSFR_TOOL 1;
BA_ "GenSigSendType" SG_ 1902 udsServerData_DOSFR 1;
BA_ "SNARequired" SG_ 1902 udsServerData_DOSFR 1;
BA_ "GenSigSendType" SG_ 1909 udsClientDataDOSRL_TOOL 1;
BA_ "SNARequired" SG_ 1909 udsClientDataDOSRL_TOOL 1;
BA_ "GenSigSendType" SG_ 1910 udsServerData_DOSRL 1;
BA_ "SNARequired" SG_ 1910 udsServerData_DOSRL 1;
BA_ "GenSigSendType" SG_ 1917 udsClientDataDOSRR_TOOL 1;
BA_ "SNARequired" SG_ 1917 udsClientDataDOSRR_TOOL 1;
BA_ "GenSigSendType" SG_ 1918 udsServerData_DOSRR 1;
BA_ "SNARequired" SG_ 1918 udsServerData_DOSRR 1;
BA_ "ExpirationValue" SG_ 1036 ambientLightSelection_IHUB "SNA";
BA_ "GenSigSendType" SG_ 1036 ambientLightSelection_IHUB 1;
BA_ "OriginatingECU" SG_ 1036 ambientLightSelection_IHUB "IHUB";
BA_ "GatewayedSignal" SG_ 1036 ambientLightSelection_IHUB 1;
BA_ "ExpirationValue" SG_ 1036 ambientLightFade_IHUB "SNA";
BA_ "GenSigSendType" SG_ 1036 ambientLightFade_IHUB 1;
BA_ "OriginatingECU" SG_ 1036 ambientLightFade_IHUB "IHUB";
BA_ "GatewayedSignal" SG_ 1036 ambientLightFade_IHUB 1;
BA_ "ExpirationValue" SG_ 1036 ambientLightColorR_IHUB "SNA";
BA_ "GenSigSendType" SG_ 1036 ambientLightColorR_IHUB 1;
BA_ "OriginatingECU" SG_ 1036 ambientLightColorR_IHUB "IHUB";
BA_ "GatewayedSignal" SG_ 1036 ambientLightColorR_IHUB 1;
BA_ "ExpirationValue" SG_ 1036 ambientLightColorG_IHUB "SNA";
BA_ "GenSigSendType" SG_ 1036 ambientLightColorG_IHUB 1;
BA_ "OriginatingECU" SG_ 1036 ambientLightColorG_IHUB "IHUB";
BA_ "GatewayedSignal" SG_ 1036 ambientLightColorG_IHUB 1;
BA_ "ExpirationValue" SG_ 1036 ambientLightColorB_IHUB "SNA";
BA_ "GenSigSendType" SG_ 1036 ambientLightColorB_IHUB 1;
BA_ "OriginatingECU" SG_ 1036 ambientLightColorB_IHUB "IHUB";
BA_ "GatewayedSignal" SG_ 1036 ambientLightColorB_IHUB 1;
BA_ "ExpirationValue" SG_ 1036 lightDomer_IHUB "SNA";
BA_ "GenSigSendType" SG_ 1036 lightDomer_IHUB 1;
BA_ "OriginatingECU" SG_ 1036 lightDomer_IHUB "IHUB";
BA_ "GatewayedSignal" SG_ 1036 lightDomer_IHUB 1;
BA_ "ExpirationValue" SG_ 1036 lightMrlrr_IHUB "SNA";
BA_ "GenSigSendType" SG_ 1036 lightMrlrr_IHUB 1;
BA_ "OriginatingECU" SG_ 1036 lightMrlrr_IHUB "IHUB";
BA_ "GatewayedSignal" SG_ 1036 lightMrlrr_IHUB 1;
BA_ "ExpirationValue" SG_ 1036 lightMrlrl_IHUB "SNA";
BA_ "GenSigSendType" SG_ 1036 lightMrlrl_IHUB 1;
BA_ "OriginatingECU" SG_ 1036 lightMrlrl_IHUB "IHUB";
BA_ "GatewayedSignal" SG_ 1036 lightMrlrl_IHUB 1;
BA_ "ExpirationValue" SG_ 1036 lightAllFunctional_IHUB "SNA";
BA_ "GenSigSendType" SG_ 1036 lightAllFunctional_IHUB 1;
BA_ "OriginatingECU" SG_ 1036 lightAllFunctional_IHUB "IHUB";
BA_ "GatewayedSignal" SG_ 1036 lightAllFunctional_IHUB 1;
BA_ "ExpirationValue" SG_ 1036 lightRightDomef_IHUB "SNA";
BA_ "GenSigSendType" SG_ 1036 lightRightDomef_IHUB 1;
BA_ "OriginatingECU" SG_ 1036 lightRightDomef_IHUB "IHUB";
BA_ "GatewayedSignal" SG_ 1036 lightRightDomef_IHUB 1;
BA_ "ExpirationValue" SG_ 1036 lightCenterDomef_IHUB "SNA";
BA_ "GenSigSendType" SG_ 1036 lightCenterDomef_IHUB 1;
BA_ "OriginatingECU" SG_ 1036 lightCenterDomef_IHUB "IHUB";
BA_ "GatewayedSignal" SG_ 1036 lightCenterDomef_IHUB 1;
BA_ "ExpirationValue" SG_ 1036 lightLeftDomef_IHUB "SNA";
BA_ "GenSigSendType" SG_ 1036 lightLeftDomef_IHUB 1;
BA_ "OriginatingECU" SG_ 1036 lightLeftDomef_IHUB "IHUB";
BA_ "GatewayedSignal" SG_ 1036 lightLeftDomef_IHUB 1;
BA_ "OriginatingECU" SG_ 683 windowPositionRL_DCRL "DCRL";
BA_ "GatewayedSignal" SG_ 683 windowPositionRL_DCRL 1;
BA_ "OriginatingECU" SG_ 715 windowPositionRR_DCRR "DCRR";
BA_ "GatewayedSignal" SG_ 715 windowPositionRR_DCRR 1;
BA_ "GenSigSendType" SG_ 1740 xcpResponseData_DCRR 1;
BA_ "GenSigSendType" SG_ 1739 xcpRequestDataDCRR_TOOL 1;
BA_ "GenSigSendType" SG_ 1708 xcpResponseData_DCRL 1;
BA_ "GenSigSendType" SG_ 1707 xcpRequestDataDCRL_TOOL 1;
BA_ "GenSigSendType" SG_ 1644 xcpResponseData_DCFR 1;
BA_ "GenSigSendType" SG_ 1643 xcpRequestDataDCFR_TOOL 1;
BA_ "GenSigSendType" SG_ 1636 xcpResponseData_DCFL 1;
BA_ "GenSigSendType" SG_ 1635 xcpRequestDataDCFL_TOOL 1;
BA_ "SNARequired" SG_ 266 steeringMoveAbsTiltPos_BGW 1;
BA_ "OriginatingECU" SG_ 266 steeringMoveAbsTiltPos_BGW "BGW";
BA_ "GenSigSendType" SG_ 266 steeringMoveAbsTiltPos_BGW 1;
BA_ "SNARequired" SG_ 266 steeringMoveAbsTelePos_BGW 1;
BA_ "OriginatingECU" SG_ 266 steeringMoveAbsTelePos_BGW "BGW";
BA_ "GenSigSendType" SG_ 266 steeringMoveAbsTelePos_BGW 1;
BA_ "OriginatingECU" SG_ 1794 resetCause_RCLR "RCLR";
BA_ "GenSigSendType" SG_ 1794 resetCause_RCLR 1;
BA_ "GatewayedSignal" SG_ 1794 resetCause_RCLR 1;
BA_ "OriginatingECU" SG_ 1794 bootloaderStuckSignal_RCLR "RCLR";
BA_ "GenSigSendType" SG_ 1794 bootloaderStuckSignal_RCLR 1;
BA_ "GatewayedSignal" SG_ 1794 bootloaderStuckSignal_RCLR 1;
BA_ "OriginatingECU" SG_ 1794 hardwareRevisionId_RCLR "RCLR";
BA_ "GenSigSendType" SG_ 1794 hardwareRevisionId_RCLR 1;
BA_ "GatewayedSignal" SG_ 1794 hardwareRevisionId_RCLR 1;
BA_ "OriginatingECU" SG_ 1794 hardwarePartNumber_RCLR "RCLR";
BA_ "GenSigSendType" SG_ 1794 hardwarePartNumber_RCLR 1;
BA_ "GatewayedSignal" SG_ 1794 hardwarePartNumber_RCLR 1;
BA_ "OriginatingECU" SG_ 1786 hardwareRevisionId_RCLL "RCLL";
BA_ "GenSigSendType" SG_ 1786 hardwareRevisionId_RCLL 1;
BA_ "GatewayedSignal" SG_ 1786 hardwareRevisionId_RCLL 1;
BA_ "OriginatingECU" SG_ 1786 resetCause_RCLL "RCLL";
BA_ "GenSigSendType" SG_ 1786 resetCause_RCLL 1;
BA_ "GatewayedSignal" SG_ 1786 resetCause_RCLL 1;
BA_ "OriginatingECU" SG_ 1786 bootloaderStuckSignal_RCLL "RCLL";
BA_ "GenSigSendType" SG_ 1786 bootloaderStuckSignal_RCLL 1;
BA_ "GatewayedSignal" SG_ 1786 bootloaderStuckSignal_RCLL 1;
BA_ "OriginatingECU" SG_ 1786 hardwarePartNumber_RCLL "RCLL";
BA_ "GenSigSendType" SG_ 1786 hardwarePartNumber_RCLL 1;
BA_ "GatewayedSignal" SG_ 1786 hardwarePartNumber_RCLL 1;
BA_ "OriginatingECU" SG_ 1770 resetCause_LGL "LGL";
BA_ "GenSigSendType" SG_ 1770 resetCause_LGL 1;
BA_ "GatewayedSignal" SG_ 1770 resetCause_LGL 1;
BA_ "OriginatingECU" SG_ 1770 bootloaderStuckSignal_LGL "LGL";
BA_ "GenSigSendType" SG_ 1770 bootloaderStuckSignal_LGL 1;
BA_ "GatewayedSignal" SG_ 1770 bootloaderStuckSignal_LGL 1;
BA_ "OriginatingECU" SG_ 1770 hardwareRevisionId_LGL "LGL";
BA_ "GenSigSendType" SG_ 1770 hardwareRevisionId_LGL 1;
BA_ "GatewayedSignal" SG_ 1770 hardwareRevisionId_LGL 1;
BA_ "OriginatingECU" SG_ 1770 hardwarePartNumber_LGL "LGL";
BA_ "GenSigSendType" SG_ 1770 hardwarePartNumber_LGL 1;
BA_ "GatewayedSignal" SG_ 1770 hardwarePartNumber_LGL 1;
BA_ "GenSigSendType" SG_ 1810 resetCause_ACCL 1;
BA_ "OriginatingECU" SG_ 1810 resetCause_ACCL "ACCL";
BA_ "GatewayedSignal" SG_ 1810 resetCause_ACCL 1;
BA_ "GenSigSendType" SG_ 1810 bootloaderStuckSignal_ACCL 1;
BA_ "OriginatingECU" SG_ 1810 bootloaderStuckSignal_ACCL "ACCL";
BA_ "GatewayedSignal" SG_ 1810 bootloaderStuckSignal_ACCL 1;
BA_ "GenSigSendType" SG_ 1810 hardwareRevisionId_ACCL 1;
BA_ "OriginatingECU" SG_ 1810 hardwareRevisionId_ACCL "ACCL";
BA_ "GatewayedSignal" SG_ 1810 hardwareRevisionId_ACCL 1;
BA_ "OriginatingECU" SG_ 1810 hardwarePartNumber_ACCL "ACCL";
BA_ "GenSigSendType" SG_ 1810 hardwarePartNumber_ACCL 1;
BA_ "GatewayedSignal" SG_ 1810 hardwarePartNumber_ACCL 1;
BA_ "GenSigSendType" SG_ 1383 sequenceServerData_RRDC 1;
BA_ "GenSigSendType" SG_ 1382 sequenceClientDataRRDC_TOOL 1;
BA_ "GenSigSendType" SG_ 1375 sequenceServerData_RLDC 1;
BA_ "GenSigSendType" SG_ 1374 sequenceClientDataRLDC_TOOL 1;
BA_ "GenSigSendType" SG_ 1367 sequenceServerData_FRDC 1;
BA_ "GenSigSendType" SG_ 1366 sequenceClientDataFRDC_TOOL 1;
BA_ "GenSigSendType" SG_ 1359 sequenceServerData_FLDC 1;
BA_ "GenSigSendType" SG_ 1358 sequenceClientDataFLDC_TOOL 1;
BA_ "GenSigSendType" SG_ 1291 seatTrackIncrementFL_BGW 1;
BA_ "GenSigSendType" SG_ 1291 seatTrackIncrementFR_BGW 1;
BA_ "GenSigSendType" SG_ 1291 seatCushionIncrementFR_BGW 1;
BA_ "GenSigSendType" SG_ 1291 seatCushionIncrementFL_BGW 1;
BA_ "GenSigSendType" SG_ 1291 seatLiftIncrementFR_BGW 1;
BA_ "GenSigSendType" SG_ 1291 seatLiftIncrementFL_BGW 1;
BA_ "GenSigSendType" SG_ 1291 seatBackIncrementFR_BGW 1;
BA_ "GenSigSendType" SG_ 1291 seatBackIncrementFL_BGW 1;
BA_ "GatewayedSignal" SG_ 531 rsdStatus_FBCM 1;
BA_ "OriginatingECU" SG_ 531 rsdStatus_FBCM "FBCM";
BA_ "GatewayedSignal" SG_ 531 rsdPosition_FBCM 1;
BA_ "OriginatingECU" SG_ 531 rsdPosition_FBCM "FBCM";
BA_ "SNARequired" SG_ 531 steeringTelePos_FBCM 1;
BA_ "OriginatingECU" SG_ 531 steeringTelePos_FBCM "FBCM";
BA_ "GatewayedSignal" SG_ 531 steeringTelePos_FBCM 1;
BA_ "SNARequired" SG_ 531 steeringTiltPos_FBCM 1;
BA_ "OriginatingECU" SG_ 531 steeringTiltPos_FBCM "FBCM";
BA_ "GatewayedSignal" SG_ 531 steeringTiltPos_FBCM 1;
BA_ "GenSigSendType" SG_ 1288 seatCushionTiltCmdRR_BGW 1;
BA_ "GenSigSendType" SG_ 1288 seatCushionTiltCmdRL_BGW 1;
BA_ "GenSigSendType" SG_ 1288 seatLegSwivelIncrementRL_BGW 1;
BA_ "GenSigSendType" SG_ 1288 seatLegSwivelIncrementRR_BGW 1;
BA_ "GenSigSendType" SG_ 1288 seatLegExtIncrementRL_BGW 1;
BA_ "GenSigSendType" SG_ 1288 seatLegExtIncrementRR_BGW 1;
BA_ "GenSigSendType" SG_ 1288 seatCushionIncrementRL_BGW 1;
BA_ "GenSigSendType" SG_ 1288 seatCushionIncrementRR_BGW 1;
BA_ "GenSigSendType" SG_ 1288 seatBackIncrementRL_BGW 1;
BA_ "GenSigSendType" SG_ 1288 seatBackIncrementRR_BGW 1;
BA_ "GenSigSendType" SG_ 1288 seatLegExtCmdRR_BGW 1;
BA_ "GenSigSendType" SG_ 1288 seatBackCmdRR_BGW 1;
BA_ "GenSigSendType" SG_ 1288 seatShoulderBolsterCmdRR_BGW 1;
BA_ "GenSigSendType" SG_ 1288 seatShoulderBolsterCmdRL_BGW 1;
BA_ "GenSigSendType" SG_ 1288 seatBackCmdRL_BGW 1;
BA_ "GenSigSendType" SG_ 1288 seatLegSwivelCmdRL_BGW 1;
BA_ "GenSigSendType" SG_ 1288 seatLegSwivelCmdRR_BGW 1;
BA_ "GenSigSendType" SG_ 1288 seatLegExtCmdRL_BGW 1;
BA_ "GenSigSendType" SG_ 1288 seatBackLumbarCmdRR_BGW 1;
BA_ "GenSigSendType" SG_ 1288 seatBackLumbarCmdRL_BGW 1;
BA_ "GenSigSendType" SG_ 1294 seatShoulderBlstrAbsPosRRSM_BGW 1;
BA_ "GenSigSendType" SG_ 1294 seatCushionAbsTiltPosRRSM_BGW 1;
BA_ "GenSigSendType" SG_ 1294 seatLegExtAbsPosRRSM_BGW 1;
BA_ "GenSigSendType" SG_ 1294 seatLegSwivelAbsPosRRSM_BGW 1;
BA_ "GenSigSendType" SG_ 1294 seatBackAbsPosRRSM_BGW 1;
BA_ "GenSigSendType" SG_ 1289 seatCushionBolsterAbsPosPSM_BGW 1;
BA_ "GenSigSendType" SG_ 1289 seatBackBolsterAbsPosPSM_BGW 1;
BA_ "GenSigSendType" SG_ 1289 seatCushionAbsTiltPosPSM_BGW 1;
BA_ "GenSigSendType" SG_ 1289 seatTrackAbsPosPSM_BGW 1;
BA_ "GenSigSendType" SG_ 1289 seatLiftAbsPosPSM_BGW 1;
BA_ "GenSigSendType" SG_ 1289 seatBackAbsPosPSM_BGW 1;
BA_ "GenSigSendType" SG_ 780 chargeTargetSOE_BGW 1;
BA_ "GenSigSendType" SG_ 780 bPillarScreenReq_BGW 1;
BA_ "OriginatingECU" SG_ 823 eventsUnread_DBPC "DBPC";
BA_ "GatewayedSignal" SG_ 823 eventsUnread_DBPC 1;
BA_ "GenSigSendType" SG_ 823 eventsUnread_DBPC 1;
BA_ "GenSigSendType" SG_ 823 eventNotification_DBPC 1;
BA_ "GenSigSendType" SG_ 823 eventAssert_DBPC 1;
BA_ "OriginatingECU" SG_ 723 eventsUnread_RRSM "RRSM";
BA_ "GatewayedSignal" SG_ 723 eventsUnread_RRSM 1;
BA_ "GenSigSendType" SG_ 723 eventsUnread_RRSM 1;
BA_ "GenSigSendType" SG_ 723 eventNotification_RRSM 1;
BA_ "GenSigSendType" SG_ 723 eventAssert_RRSM 1;
BA_ "OriginatingECU" SG_ 871 eventsUnread_RRDC "RRDC";
BA_ "GatewayedSignal" SG_ 871 eventsUnread_RRDC 1;
BA_ "GenSigSendType" SG_ 871 eventsUnread_RRDC 1;
BA_ "GenSigSendType" SG_ 871 eventNotification_RRDC 1;
BA_ "GenSigSendType" SG_ 871 eventAssert_RRDC 1;
BA_ "GenSigSendType" SG_ 691 eventAssert_RLSM 1;
BA_ "OriginatingECU" SG_ 691 eventsUnread_RLSM "RLSM";
BA_ "GatewayedSignal" SG_ 691 eventsUnread_RLSM 1;
BA_ "GenSigSendType" SG_ 691 eventsUnread_RLSM 1;
BA_ "GenSigSendType" SG_ 691 eventNotification_RLSM 1;
BA_ "OriginatingECU" SG_ 863 eventsUnread_RLDC "RLDC";
BA_ "GatewayedSignal" SG_ 863 eventsUnread_RLDC 1;
BA_ "GenSigSendType" SG_ 863 eventsUnread_RLDC 1;
BA_ "GenSigSendType" SG_ 863 eventNotification_RLDC 1;
BA_ "GenSigSendType" SG_ 863 eventAssert_RLDC 1;
BA_ "OriginatingECU" SG_ 1280 eventsUnread_RCLR "RCLR";
BA_ "GatewayedSignal" SG_ 1280 eventsUnread_RCLR 1;
BA_ "GenSigSendType" SG_ 1280 eventsUnread_RCLR 1;
BA_ "GenSigSendType" SG_ 1280 eventNotification_RCLR 1;
BA_ "GenSigSendType" SG_ 1280 eventAssert_RCLR 1;
BA_ "OriginatingECU" SG_ 1272 eventsUnread_RCLL "RCLL";
BA_ "GatewayedSignal" SG_ 1272 eventsUnread_RCLL 1;
BA_ "GenSigSendType" SG_ 1272 eventsUnread_RCLL 1;
BA_ "GenSigSendType" SG_ 1272 eventNotification_RCLL 1;
BA_ "GenSigSendType" SG_ 1272 eventAssert_RCLL 1;
BA_ "OriginatingECU" SG_ 659 eventsUnread_PSM "PSM";
BA_ "GatewayedSignal" SG_ 659 eventsUnread_PSM 1;
BA_ "GenSigSendType" SG_ 659 eventsUnread_PSM 1;
BA_ "GenSigSendType" SG_ 659 eventNotification_PSM 1;
BA_ "GenSigSendType" SG_ 659 eventAssert_PSM 1;
BA_ "OriginatingECU" SG_ 1258 eventsUnread_LGL "LGL";
BA_ "GatewayedSignal" SG_ 1258 eventsUnread_LGL 1;
BA_ "GenSigSendType" SG_ 1258 eventsUnread_LGL 1;
BA_ "GenSigSendType" SG_ 1258 eventNotification_LGL 1;
BA_ "GenSigSendType" SG_ 1258 eventAssert_LGL 1;
BA_ "OriginatingECU" SG_ 591 eventsUnread_HLR "HLR";
BA_ "GatewayedSignal" SG_ 591 eventsUnread_HLR 1;
BA_ "GenSigSendType" SG_ 591 eventsUnread_HLR 1;
BA_ "GenSigSendType" SG_ 591 eventNotification_HLR 1;
BA_ "GenSigSendType" SG_ 591 eventAssert_HLR 1;
BA_ "OriginatingECU" SG_ 583 eventsUnread_HLL "HLL";
BA_ "GatewayedSignal" SG_ 583 eventsUnread_HLL 1;
BA_ "GenSigSendType" SG_ 583 eventsUnread_HLL 1;
BA_ "GenSigSendType" SG_ 583 eventNotification_HLL 1;
BA_ "GenSigSendType" SG_ 583 eventAssert_HLL 1;
BA_ "OriginatingECU" SG_ 855 eventsUnread_FRDC "FRDC";
BA_ "GatewayedSignal" SG_ 855 eventsUnread_FRDC 1;
BA_ "GenSigSendType" SG_ 855 eventsUnread_FRDC 1;
BA_ "GenSigSendType" SG_ 855 eventNotification_FRDC 1;
BA_ "GenSigSendType" SG_ 855 eventAssert_FRDC 1;
BA_ "OriginatingECU" SG_ 847 eventsUnread_FLDC "FLDC";
BA_ "GatewayedSignal" SG_ 847 eventsUnread_FLDC 1;
BA_ "GenSigSendType" SG_ 847 eventsUnread_FLDC 1;
BA_ "GenSigSendType" SG_ 847 eventNotification_FLDC 1;
BA_ "GenSigSendType" SG_ 847 eventAssert_FLDC 1;
BA_ "OriginatingECU" SG_ 1345 eventsUnread_FFL "FFL";
BA_ "GatewayedSignal" SG_ 1345 eventsUnread_FFL 1;
BA_ "GenSigSendType" SG_ 1345 eventsUnread_FFL 1;
BA_ "GenSigSendType" SG_ 1345 eventNotification_FFL 1;
BA_ "GenSigSendType" SG_ 1345 eventAssert_FFL 1;
BA_ "OriginatingECU" SG_ 806 eventsUnread_ECPM "ECPM";
BA_ "GatewayedSignal" SG_ 806 eventsUnread_ECPM 1;
BA_ "GenSigSendType" SG_ 806 eventsUnread_ECPM 1;
BA_ "GenSigSendType" SG_ 806 eventNotification_ECPM 1;
BA_ "GenSigSendType" SG_ 806 eventAssert_ECPM 1;
BA_ "OriginatingECU" SG_ 627 eventsUnread_DSM "DSM";
BA_ "GatewayedSignal" SG_ 627 eventsUnread_DSM 1;
BA_ "GenSigSendType" SG_ 627 eventsUnread_DSM 1;
BA_ "GenSigSendType" SG_ 627 eventNotification_DSM 1;
BA_ "GenSigSendType" SG_ 627 eventAssert_DSM 1;
BA_ "OriginatingECU" SG_ 1296 eventsUnread_ACCL "ACCL";
BA_ "GatewayedSignal" SG_ 1296 eventsUnread_ACCL 1;
BA_ "GenSigSendType" SG_ 1296 eventsUnread_ACCL 1;
BA_ "GenSigSendType" SG_ 1296 eventNotification_ACCL 1;
BA_ "GenSigSendType" SG_ 1296 eventAssert_ACCL 1;
BA_ "GenSigSendType" SG_ 11 ignoreHoodOpen_IHUB 1;
BA_ "GatewayedSignal" SG_ 11 ignoreHoodOpen_IHUB 1;
BA_ "OriginatingECU" SG_ 11 ignoreHoodOpen_IHUB "IHUB";
BA_ "GenSigSendType" SG_ 11 unlockPreference_IHUB 1;
BA_ "GatewayedSignal" SG_ 11 unlockPreference_IHUB 1;
BA_ "OriginatingECU" SG_ 11 unlockPreference_IHUB "IHUB";
BA_ "GenSigSendType" SG_ 11 liftgateTargetOpenAngle_IHUB 1;
BA_ "GatewayedSignal" SG_ 11 liftgateTargetOpenAngle_IHUB 1;
BA_ "OriginatingECU" SG_ 11 liftgateTargetOpenAngle_IHUB "IHUB";
BA_ "GenSigSendType" SG_ 11 transportMode_IHUB 1;
BA_ "GatewayedSignal" SG_ 11 transportMode_IHUB 1;
BA_ "OriginatingECU" SG_ 11 transportMode_IHUB "IHUB";
BA_ "GenSigSendType" SG_ 11 towMode_IHUB 1;
BA_ "GatewayedSignal" SG_ 11 towMode_IHUB 1;
BA_ "OriginatingECU" SG_ 11 towMode_IHUB "IHUB";
BA_ "GenSigSendType" SG_ 11 theftDetectionEnable_IHUB 1;
BA_ "GatewayedSignal" SG_ 11 theftDetectionEnable_IHUB 1;
BA_ "OriginatingECU" SG_ 11 theftDetectionEnable_IHUB "IHUB";
BA_ "GenSigSendType" SG_ 11 unlockOnPark_IHUB 1;
BA_ "GatewayedSignal" SG_ 11 unlockOnPark_IHUB 1;
BA_ "OriginatingECU" SG_ 11 unlockOnPark_IHUB "IHUB";
BA_ "GenSigSendType" SG_ 11 inactivityLock_IHUB 1;
BA_ "GatewayedSignal" SG_ 11 inactivityLock_IHUB 1;
BA_ "OriginatingECU" SG_ 11 inactivityLock_IHUB "IHUB";
BA_ "GenSigSendType" SG_ 11 mirrorPowerFoldAutoOnOff_IHUB 1;
BA_ "GatewayedSignal" SG_ 11 mirrorPowerFoldAutoOnOff_IHUB 1;
BA_ "OriginatingECU" SG_ 11 mirrorPowerFoldAutoOnOff_IHUB "IHUB";
BA_ "GenSigSendType" SG_ 11 distanceUnits_IHUB 1;
BA_ "GatewayedSignal" SG_ 11 distanceUnits_IHUB 1;
BA_ "OriginatingECU" SG_ 11 distanceUnits_IHUB "IHUB";
BA_ "GenSigSendType" SG_ 11 chargeDisplaySetting_IHUB 1;
BA_ "GatewayedSignal" SG_ 11 chargeDisplaySetting_IHUB 1;
BA_ "OriginatingECU" SG_ 11 chargeDisplaySetting_IHUB "IHUB";
BA_ "GenSigSendType" SG_ 11 autoMirrorTilt_IHUB 1;
BA_ "OriginatingECU" SG_ 11 autoMirrorTilt_IHUB "IHUB";
BA_ "GatewayedSignal" SG_ 11 autoMirrorTilt_IHUB 1;
BA_ "GenSigSendType" SG_ 11 autoDoorLock_IHUB 1;
BA_ "OriginatingECU" SG_ 11 autoDoorLock_IHUB "IHUB";
BA_ "GatewayedSignal" SG_ 11 autoDoorLock_IHUB 1;
BA_ "GenSigSendType" SG_ 11 autoLowBeamReq_IHUB 1;
BA_ "OriginatingECU" SG_ 11 autoLowBeamReq_IHUB "IHUB";
BA_ "GatewayedSignal" SG_ 11 autoLowBeamReq_IHUB 1;
BA_ "GenSigSendType" SG_ 11 tempDisplayUnits_IHUB 1;
BA_ "GatewayedSignal" SG_ 11 tempDisplayUnits_IHUB 1;
BA_ "OriginatingECU" SG_ 11 tempDisplayUnits_IHUB "IHUB";
BA_ "GenSigSendType" SG_ 11 languageSelection_IHUB 1;
BA_ "OriginatingECU" SG_ 11 languageSelection_IHUB "IHUB";
BA_ "GatewayedSignal" SG_ 11 languageSelection_IHUB 1;
BA_ "GenSigSendType" SG_ 1194 doorLatchStatus_DCRL 1;
BA_ "GatewayedSignal" SG_ 1194 doorLatchStatus_DCRL 1;
BA_ "OriginatingECU" SG_ 1194 doorLatchStatus_DCRL "DCRL";
BA_ "OriginatingECU" SG_ 1194 doorLatchDoorAjar_DCRL "DCRL";
BA_ "GenSigSendType" SG_ 1194 doorLatchDoorAjar_DCRL 1;
BA_ "GatewayedSignal" SG_ 1194 doorLatchDoorAjar_DCRL 1;
BA_ "OriginatingECU" SG_ 1194 doorLatchDoorOpen_DCRL "DCRL";
BA_ "GenSigSendType" SG_ 1194 doorLatchDoorOpen_DCRL 1;
BA_ "GatewayedSignal" SG_ 1194 doorLatchDoorOpen_DCRL 1;
BA_ "OriginatingECU" SG_ 1194 doorLatchPawlClosed_DCRL "DCRL";
BA_ "GenSigSendType" SG_ 1194 doorLatchPawlClosed_DCRL 1;
BA_ "GatewayedSignal" SG_ 1194 doorLatchPawlClosed_DCRL 1;
BA_ "OriginatingECU" SG_ 1194 doorLatchCinchHome_DCRL "DCRL";
BA_ "GenSigSendType" SG_ 1194 doorLatchCinchHome_DCRL 1;
BA_ "GatewayedSignal" SG_ 1194 doorLatchCinchHome_DCRL 1;
BA_ "OriginatingECU" SG_ 1194 doorStopSource_DCRL "DCRL";
BA_ "GenSigSendType" SG_ 1194 doorStopSource_DCRL 1;
BA_ "GatewayedSignal" SG_ 1194 doorStopSource_DCRL 1;
BA_ "OriginatingECU" SG_ 1194 doorCloseSource_DCRL "DCRL";
BA_ "GenSigSendType" SG_ 1194 doorCloseSource_DCRL 1;
BA_ "GatewayedSignal" SG_ 1194 doorCloseSource_DCRL 1;
BA_ "OriginatingECU" SG_ 1194 doorOpenSource_DCRL "DCRL";
BA_ "GenSigSendType" SG_ 1194 doorOpenSource_DCRL 1;
BA_ "GatewayedSignal" SG_ 1194 doorOpenSource_DCRL 1;
BA_ "GatewayedSignal" SG_ 1194 windowOpenSource_DCRL 1;
BA_ "GenSigSendType" SG_ 1194 windowOpenSource_DCRL 1;
BA_ "OriginatingECU" SG_ 1194 windowOpenSource_DCRL "DCRL";
BA_ "GatewayedSignal" SG_ 1194 windowCloseSource_DCRL 1;
BA_ "GenSigSendType" SG_ 1194 windowCloseSource_DCRL 1;
BA_ "OriginatingECU" SG_ 1194 windowCloseSource_DCRL "DCRL";
BA_ "OriginatingECU" SG_ 1194 ecuUpTime_DCRL "DCRL";
BA_ "GenSigSendType" SG_ 1194 ecuUpTime_DCRL 1;
BA_ "GatewayedSignal" SG_ 1194 ecuUpTime_DCRL 1;
BA_ "GenSigSendType" SG_ 1162 doorLatchStatus_DCFR 1;
BA_ "GatewayedSignal" SG_ 1162 doorLatchStatus_DCFR 1;
BA_ "OriginatingECU" SG_ 1162 doorLatchStatus_DCFR "DCFR";
BA_ "OriginatingECU" SG_ 1162 doorLatchDoorAjar_DCFR "DCFR";
BA_ "GenSigSendType" SG_ 1162 doorLatchDoorAjar_DCFR 1;
BA_ "GatewayedSignal" SG_ 1162 doorLatchDoorAjar_DCFR 1;
BA_ "OriginatingECU" SG_ 1162 doorLatchDoorOpen_DCFR "DCFR";
BA_ "GenSigSendType" SG_ 1162 doorLatchDoorOpen_DCFR 1;
BA_ "GatewayedSignal" SG_ 1162 doorLatchDoorOpen_DCFR 1;
BA_ "OriginatingECU" SG_ 1162 doorLatchPawlClosed_DCFR "DCFR";
BA_ "GenSigSendType" SG_ 1162 doorLatchPawlClosed_DCFR 1;
BA_ "GatewayedSignal" SG_ 1162 doorLatchPawlClosed_DCFR 1;
BA_ "OriginatingECU" SG_ 1162 doorLatchCinchHome_DCFR "DCFR";
BA_ "GenSigSendType" SG_ 1162 doorLatchCinchHome_DCFR 1;
BA_ "GatewayedSignal" SG_ 1162 doorLatchCinchHome_DCFR 1;
BA_ "OriginatingECU" SG_ 1162 doorStopSource_DCFR "DCFR";
BA_ "GenSigSendType" SG_ 1162 doorStopSource_DCFR 1;
BA_ "GatewayedSignal" SG_ 1162 doorStopSource_DCFR 1;
BA_ "OriginatingECU" SG_ 1162 doorCloseSource_DCFR "DCFR";
BA_ "GenSigSendType" SG_ 1162 doorCloseSource_DCFR 1;
BA_ "GatewayedSignal" SG_ 1162 doorCloseSource_DCFR 1;
BA_ "OriginatingECU" SG_ 1162 doorOpenSource_DCFR "DCFR";
BA_ "GenSigSendType" SG_ 1162 doorOpenSource_DCFR 1;
BA_ "GatewayedSignal" SG_ 1162 doorOpenSource_DCFR 1;
BA_ "GatewayedSignal" SG_ 1162 windowOpenSource_DCFR 1;
BA_ "GenSigSendType" SG_ 1162 windowOpenSource_DCFR 1;
BA_ "OriginatingECU" SG_ 1162 windowOpenSource_DCFR "DCFR";
BA_ "GatewayedSignal" SG_ 1162 windowCloseSource_DCFR 1;
BA_ "GenSigSendType" SG_ 1162 windowCloseSource_DCFR 1;
BA_ "OriginatingECU" SG_ 1162 windowCloseSource_DCFR "DCFR";
BA_ "OriginatingECU" SG_ 1162 ecuUpTime_DCFR "DCFR";
BA_ "GenSigSendType" SG_ 1162 ecuUpTime_DCFR 1;
BA_ "GatewayedSignal" SG_ 1162 ecuUpTime_DCFR 1;
BA_ "GenSigSendType" SG_ 1226 doorLatchStatus_DCRR 1;
BA_ "GatewayedSignal" SG_ 1226 doorLatchStatus_DCRR 1;
BA_ "OriginatingECU" SG_ 1226 doorLatchStatus_DCRR "DCRR";
BA_ "OriginatingECU" SG_ 1226 doorLatchDoorAjar_DCRR "DCRR";
BA_ "GenSigSendType" SG_ 1226 doorLatchDoorAjar_DCRR 1;
BA_ "GatewayedSignal" SG_ 1226 doorLatchDoorAjar_DCRR 1;
BA_ "OriginatingECU" SG_ 1226 doorLatchDoorOpen_DCRR "DCRR";
BA_ "GenSigSendType" SG_ 1226 doorLatchDoorOpen_DCRR 1;
BA_ "GatewayedSignal" SG_ 1226 doorLatchDoorOpen_DCRR 1;
BA_ "OriginatingECU" SG_ 1226 doorLatchPawlClosed_DCRR "DCRR";
BA_ "GenSigSendType" SG_ 1226 doorLatchPawlClosed_DCRR 1;
BA_ "GatewayedSignal" SG_ 1226 doorLatchPawlClosed_DCRR 1;
BA_ "OriginatingECU" SG_ 1226 doorLatchCinchHome_DCRR "DCRR";
BA_ "GenSigSendType" SG_ 1226 doorLatchCinchHome_DCRR 1;
BA_ "GatewayedSignal" SG_ 1226 doorLatchCinchHome_DCRR 1;
BA_ "OriginatingECU" SG_ 1226 doorStopSource_DCRR "DCRR";
BA_ "GenSigSendType" SG_ 1226 doorStopSource_DCRR 1;
BA_ "GatewayedSignal" SG_ 1226 doorStopSource_DCRR 1;
BA_ "OriginatingECU" SG_ 1226 doorCloseSource_DCRR "DCRR";
BA_ "GenSigSendType" SG_ 1226 doorCloseSource_DCRR 1;
BA_ "GatewayedSignal" SG_ 1226 doorCloseSource_DCRR 1;
BA_ "OriginatingECU" SG_ 1226 doorOpenSource_DCRR "DCRR";
BA_ "GenSigSendType" SG_ 1226 doorOpenSource_DCRR 1;
BA_ "GatewayedSignal" SG_ 1226 doorOpenSource_DCRR 1;
BA_ "GatewayedSignal" SG_ 1226 windowOpenSource_DCRR 1;
BA_ "GenSigSendType" SG_ 1226 windowOpenSource_DCRR 1;
BA_ "OriginatingECU" SG_ 1226 windowOpenSource_DCRR "DCRR";
BA_ "GatewayedSignal" SG_ 1226 windowCloseSource_DCRR 1;
BA_ "GenSigSendType" SG_ 1226 windowCloseSource_DCRR 1;
BA_ "OriginatingECU" SG_ 1226 windowCloseSource_DCRR "DCRR";
BA_ "OriginatingECU" SG_ 1226 ecuUpTime_DCRR "DCRR";
BA_ "GenSigSendType" SG_ 1226 ecuUpTime_DCRR 1;
BA_ "GatewayedSignal" SG_ 1226 ecuUpTime_DCRR 1;
BA_ "GenSigSendType" SG_ 1122 doorLatchStatus_DCFL 1;
BA_ "GatewayedSignal" SG_ 1122 doorLatchStatus_DCFL 1;
BA_ "OriginatingECU" SG_ 1122 doorLatchStatus_DCFL "DCFL";
BA_ "OriginatingECU" SG_ 1122 doorLatchDoorAjar_DCFL "DCFL";
BA_ "GenSigSendType" SG_ 1122 doorLatchDoorAjar_DCFL 1;
BA_ "GatewayedSignal" SG_ 1122 doorLatchDoorAjar_DCFL 1;
BA_ "OriginatingECU" SG_ 1122 doorLatchDoorOpen_DCFL "DCFL";
BA_ "GenSigSendType" SG_ 1122 doorLatchDoorOpen_DCFL 1;
BA_ "GatewayedSignal" SG_ 1122 doorLatchDoorOpen_DCFL 1;
BA_ "OriginatingECU" SG_ 1122 doorLatchPawlClosed_DCFL "DCFL";
BA_ "GenSigSendType" SG_ 1122 doorLatchPawlClosed_DCFL 1;
BA_ "GatewayedSignal" SG_ 1122 doorLatchPawlClosed_DCFL 1;
BA_ "OriginatingECU" SG_ 1122 doorLatchCinchHome_DCFL "DCFL";
BA_ "GenSigSendType" SG_ 1122 doorLatchCinchHome_DCFL 1;
BA_ "GatewayedSignal" SG_ 1122 doorLatchCinchHome_DCFL 1;
BA_ "OriginatingECU" SG_ 1122 doorStopSource_DCFL "DCFL";
BA_ "GenSigSendType" SG_ 1122 doorStopSource_DCFL 1;
BA_ "GatewayedSignal" SG_ 1122 doorStopSource_DCFL 1;
BA_ "GatewayedSignal" SG_ 1122 doorCloseSource_DCFL 1;
BA_ "GenSigSendType" SG_ 1122 doorCloseSource_DCFL 1;
BA_ "OriginatingECU" SG_ 1122 doorCloseSource_DCFL "DCFL";
BA_ "GatewayedSignal" SG_ 1122 doorOpenSource_DCFL 1;
BA_ "GenSigSendType" SG_ 1122 doorOpenSource_DCFL 1;
BA_ "OriginatingECU" SG_ 1122 doorOpenSource_DCFL "DCFL";
BA_ "GatewayedSignal" SG_ 1122 windowOpenSource_DCFL 1;
BA_ "GenSigSendType" SG_ 1122 windowOpenSource_DCFL 1;
BA_ "OriginatingECU" SG_ 1122 windowOpenSource_DCFL "DCFL";
BA_ "GatewayedSignal" SG_ 1122 windowCloseSource_DCFL 1;
BA_ "GenSigSendType" SG_ 1122 windowCloseSource_DCFL 1;
BA_ "OriginatingECU" SG_ 1122 windowCloseSource_DCFL "DCFL";
BA_ "GatewayedSignal" SG_ 1122 ecuUpTime_DCFL 1;
BA_ "GenSigSendType" SG_ 1122 ecuUpTime_DCFL 1;
BA_ "OriginatingECU" SG_ 1122 ecuUpTime_DCFL "DCFL";
BA_ "SNARequired" SG_ 12 passengerInRsdZone_BGW 1;
BA_ "OriginatingECU" SG_ 12 passengerInRsdZone_BGW "BGW";
BA_ "SNARequired" SG_ 12 driverInRsdZone_BGW 1;
BA_ "OriginatingECU" SG_ 12 driverInRsdZone_BGW "BGW";
BA_ "GenSigSendType" SG_ 1225 fimDisableWinAutoUpdownFunc_DCRR 1;
BA_ "GenSigSendType" SG_ 1225 fimLimitVehicleSpeed_DCRR 1;
BA_ "GenSigSendType" SG_ 1225 demDoorBrakeFeedbackFailure_DCRR 1;
BA_ "GenSigSendType" SG_ 1225 fimDisablePowerWindowFunc_DCRR 1;
BA_ "GenSigSendType" SG_ 1225 fimDisablePowerDoorFunction_DCRR 1;
BA_ "GenSigSendType" SG_ 1225 fimDisableMirrorMovement_DCRR 1;
BA_ "GenSigSendType" SG_ 1225 fimDisableMirrorFoldFunc_DCRR 1;
BA_ "GenSigSendType" SG_ 1225 fimDisableCinchFunction_DCRR 1;
BA_ "GenSigSendType" SG_ 1225 demWinMotorCurrentSigLoss_DCRR 1;
BA_ "GenSigSendType" SG_ 1225 demDoorUnlockSwitchSigError_DCRR 1;
BA_ "GenSigSendType" SG_ 1225 demDoorMotorUnderCurrent_DCRR 1;
BA_ "GenSigSendType" SG_ 1225 demDoorExtCapSwitchSigError_DCRR 1;
BA_ "GenSigSendType" SG_ 1225 demCinchMotorUnderCurrent_DCRR 1;
BA_ "GenSigSendType" SG_ 1225 demIRSensor2SignalError_DCRR 1;
BA_ "GenSigSendType" SG_ 1225 demIRSensor1SignalError_DCRR 1;
BA_ "GenSigSendType" SG_ 1193 fimDisableWinAutoUpdownFunc_DCRL 1;
BA_ "GenSigSendType" SG_ 1193 fimLimitVehicleSpeed_DCRL 1;
BA_ "GenSigSendType" SG_ 1193 demDoorBrakeFeedbackFailure_DCRL 1;
BA_ "GenSigSendType" SG_ 1193 fimDisablePowerWindowFunc_DCRL 1;
BA_ "GenSigSendType" SG_ 1193 fimDisablePowerDoorFunction_DCRL 1;
BA_ "GenSigSendType" SG_ 1193 fimDisableMirrorMovement_DCRL 1;
BA_ "GenSigSendType" SG_ 1193 fimDisableMirrorFoldFunc_DCRL 1;
BA_ "GenSigSendType" SG_ 1193 fimDisableCinchFunction_DCRL 1;
BA_ "GenSigSendType" SG_ 1193 demWinMotorCurrentSigLoss_DCRL 1;
BA_ "GenSigSendType" SG_ 1193 demDoorUnlockSwitchSigError_DCRL 1;
BA_ "GenSigSendType" SG_ 1193 demDoorMotorUnderCurrent_DCRL 1;
BA_ "GenSigSendType" SG_ 1193 demDoorExtCapSwitchSigError_DCRL 1;
BA_ "GenSigSendType" SG_ 1193 demCinchMotorUnderCurrent_DCRL 1;
BA_ "GenSigSendType" SG_ 1193 demIRSensor2SignalError_DCRL 1;
BA_ "GenSigSendType" SG_ 1193 demIRSensor1SignalError_DCRL 1;
BA_ "GenSigSendType" SG_ 1161 fimDisableWinAutoUpdownFunc_DCFR 1;
BA_ "GenSigSendType" SG_ 1161 fimLimitVehicleSpeed_DCFR 1;
BA_ "GenSigSendType" SG_ 1161 demDoorBrakeFeedbackFailure_DCFR 1;
BA_ "GenSigSendType" SG_ 1161 fimDisablePowerWindowFunc_DCFR 1;
BA_ "GenSigSendType" SG_ 1161 fimDisablePowerDoorFunction_DCFR 1;
BA_ "GenSigSendType" SG_ 1161 fimDisableMirrorMovement_DCFR 1;
BA_ "GenSigSendType" SG_ 1161 fimDisableMirrorFoldFunc_DCFR 1;
BA_ "GenSigSendType" SG_ 1161 fimDisableCinchFunction_DCFR 1;
BA_ "GenSigSendType" SG_ 1161 demWinMotorCurrentSigLoss_DCFR 1;
BA_ "GenSigSendType" SG_ 1161 demDoorUnlockSwitchSigError_DCFR 1;
BA_ "GenSigSendType" SG_ 1161 demDoorMotorUnderCurrent_DCFR 1;
BA_ "GenSigSendType" SG_ 1161 demDoorExtCapSwitchSigError_DCFR 1;
BA_ "GenSigSendType" SG_ 1161 demCinchMotorUnderCurrent_DCFR 1;
BA_ "GenSigSendType" SG_ 1161 demIRSensor2SignalError_DCFR 1;
BA_ "GenSigSendType" SG_ 1161 demIRSensor1SignalError_DCFR 1;
BA_ "GenSigSendType" SG_ 1121 fimDisableWinAutoUpdownFunc_DCFL 1;
BA_ "GenSigSendType" SG_ 1121 fimLimitVehicleSpeed_DCFL 1;
BA_ "GenSigSendType" SG_ 1121 fimDisablePowerWindowFunc_DCFL 1;
BA_ "GenSigSendType" SG_ 1121 fimDisablePowerDoorFunction_DCFL 1;
BA_ "GenSigSendType" SG_ 1121 fimDisableMirrorMovement_DCFL 1;
BA_ "GenSigSendType" SG_ 1121 fimDisableMirrorFoldFunc_DCFL 1;
BA_ "GenSigSendType" SG_ 1121 fimDisableCinchFunction_DCFL 1;
BA_ "GenSigSendType" SG_ 1121 demWinMotorCurrentSigLoss_DCFL 1;
BA_ "GenSigSendType" SG_ 1121 demDoorUnlockSwitchSigError_DCFL 1;
BA_ "GenSigSendType" SG_ 1121 demDoorMotorUnderCurrent_DCFL 1;
BA_ "GenSigSendType" SG_ 1121 demDoorExtCapSwitchSigError_DCFL 1;
BA_ "GenSigSendType" SG_ 1121 demDoorBrakeFeedbackFailure_DCFL 1;
BA_ "GenSigSendType" SG_ 1121 demCinchMotorUnderCurrent_DCFL 1;
BA_ "GenSigSendType" SG_ 1121 demIRSensor2SignalError_DCFL 1;
BA_ "GenSigSendType" SG_ 1121 demIRSensor1SignalError_DCFL 1;
BA_ "GenSigSendType" SG_ 13 demDEMNotification_BGW 1;
BA_ "GenSigSendType" SG_ 13 demDEMAssert_BGW 1;
BA_ "GenSigSendType" SG_ 13 demLIN2Unresponsive_BGW 1;
BA_ "GenSigSendType" SG_ 13 demLIN1Unresponsive_BGW 1;
BA_ "GenSigSendType" SG_ 13 demTelematicsCANNetworkError_BGW 1;
BA_ "GenSigSendType" SG_ 13 demThermalCANNetworkError_BGW 1;
BA_ "GenSigSendType" SG_ 13 demEthernetIHUBMIA_BGW 1;
BA_ "GenSigSendType" SG_ 13 demEthernetSDCMMIA_BGW 1;
BA_ "GenSigSendType" SG_ 13 demEthernetUnresponsive_BGW 1;
BA_ "GenSigSendType" SG_ 13 demRearFogLightNoCurrent_BGW 1;
BA_ "GenSigSendType" SG_ 13 demFBCMWakeInMIA_BGW 1;
BA_ "GenSigSendType" SG_ 13 demDCFRWakeInMIA_BGW 1;
BA_ "GenSigSendType" SG_ 13 demDCFLWakeInMIA_BGW 1;
BA_ "GenSigSendType" SG_ 13 demLiftgateLatchHomeSnLoss_BGW 1;
BA_ "GenSigSendType" SG_ 13 demLiftgatePawlSignalMissing_BGW 1;
BA_ "GenSigSendType" SG_ 13 demLiftgateAjarSignalMissing_BGW 1;
BA_ "GenSigSendType" SG_ 13 demLiftgateOpenSignalMissing_BGW 1;
BA_ "GenSigSendType" SG_ 13 demLiftgateHallSnsRtSnLoss_BGW 1;
BA_ "GenSigSendType" SG_ 13 demLiftgateHallSnsLeftSnLoss_BGW 1;
BA_ "GenSigSendType" SG_ 13 demLiftgateMotorRightOvCrn_BGW 1;
BA_ "GenSigSendType" SG_ 13 demLiftgateMotorRightSnLoss_BGW 1;
BA_ "GenSigSendType" SG_ 13 demLiftgateMotorRightSnErr_BGW 1;
BA_ "GenSigSendType" SG_ 13 demLiftgateMotorOvercurrent_BGW 1;
BA_ "GenSigSendType" SG_ 13 demLiftgateMotorLeftSnLoss_BGW 1;
BA_ "GenSigSendType" SG_ 13 demLiftgateMotorLeftSnErr_BGW 1;
BA_ "GenSigSendType" SG_ 13 demLiftgateFailsToClose_BGW 1;
BA_ "GenSigSendType" SG_ 13 demLiftgateClosesUncommanded_BGW 1;
BA_ "GenSigSendType" SG_ 13 demLgMotorOpAttLt_BGW 1;
BA_ "GenSigSendType" SG_ 13 demLiftgateMotorFailsToOpen_BGW 1;
BA_ "GenSigSendType" SG_ 1224 demIntOpenSwSnLoss_DCRR 1;
BA_ "GenSigSendType" SG_ 1224 demIntRelSwSnEr_DCRR 1;
BA_ "GenSigSendType" SG_ 1224 demInteriorReleaseSwSnLoss_DCRR 1;
BA_ "GenSigSendType" SG_ 1224 demDoorUnlockSwSnError_DCRR 1;
BA_ "GenSigSendType" SG_ 1224 demMirrorGlassPosNotReached_DCRR 1;
BA_ "GenSigSendType" SG_ 1224 demMirrorGlassMvtUcmd_DCRR 1;
BA_ "GenSigSendType" SG_ 1224 demMirrorGlassMvFail_DCRR 1;
BA_ "GenSigSendType" SG_ 1224 demIntOpenSwSnEr_DCRR 1;
BA_ "GenSigSendType" SG_ 1224 demMirrorGlassPosSnsShCir_DCRR 1;
BA_ "GenSigSendType" SG_ 1224 demMirrorGlassPosSnsOpenCir_DCRR 1;
BA_ "GenSigSendType" SG_ 1224 demMirrorGlassPosSnsSnEr_DCRR 1;
BA_ "GenSigSendType" SG_ 1224 demMirrorGlassPosSnsSnLoss_DCRR 1;
BA_ "GenSigSendType" SG_ 1224 demBodyCANIMUMsgMiss_DCRR 1;
BA_ "GenSigSendType" SG_ 1224 demBodyCANVehSpdMsgErr_DCRR 1;
BA_ "GenSigSendType" SG_ 1224 demBodyCANVehSpdMsgMiss_DCRR 1;
BA_ "GenSigSendType" SG_ 1224 demBodyCANNetworkFailure_DCRR 1;
BA_ "GenSigSendType" SG_ 1224 demBodyCANLkUnlkMsgMiss_DCRR 1;
BA_ "GenSigSendType" SG_ 1224 demBodyCANOpClMsgErr_DCRR 1;
BA_ "GenSigSendType" SG_ 1224 demBodyCANOpClMsgMiss_DCRR 1;
BA_ "GenSigSendType" SG_ 1224 demBodyCANIMUMessageError_DCRR 1;
BA_ "GenSigSendType" SG_ 1224 demBodyCANCrashMsgMiss_DCRR 1;
BA_ "GenSigSendType" SG_ 1224 demBodyCANChildLkMsgErr_DCRR 1;
BA_ "GenSigSendType" SG_ 1224 demBodyCANChildLkMsgMiss_DCRR 1;
BA_ "GenSigSendType" SG_ 1224 demBodyCANLockMessageError_DCRR 1;
BA_ "GenSigSendType" SG_ 1224 demLINNetworkFail_DCRR 1;
BA_ "GenSigSendType" SG_ 1224 demBodyCANAmbTempMsgErr_DCRR 1;
BA_ "GenSigSendType" SG_ 1224 demBodyCANAmbTempMsgMiss_DCRR 1;
BA_ "GenSigSendType" SG_ 1224 demBodyCANCrashMsgErr_DCRR 1;
BA_ "GenSigSendType" SG_ 1224 demIRSensor2MIA_DCRR 1;
BA_ "GenSigSendType" SG_ 1224 demIRSensor1MIA_DCRR 1;
BA_ "GenSigSendType" SG_ 1224 demWinSwErr_DCRR 1;
BA_ "GenSigSendType" SG_ 1224 demWinSwMIA_DCRR 1;
BA_ "GenSigSendType" SG_ 719 demDoorLockSwitchSignalLoss_DCRR 1;
BA_ "GenSigSendType" SG_ 719 demDoorExtCapSwSnEr_DCRR 1;
BA_ "GenSigSendType" SG_ 719 demDoorExtCapSwSnLoss_DCRR 1;
BA_ "GenSigSendType" SG_ 719 demDoorExtCapSwPower_DCRR 1;
BA_ "GenSigSendType" SG_ 719 demDoorExtCapSwNoPower_DCRR 1;
BA_ "GenSigSendType" SG_ 719 demDoorExtMechSwSnEr_DCRR 1;
BA_ "GenSigSendType" SG_ 719 demDoorExtMechSwSnLoss_DCRR 1;
BA_ "GenSigSendType" SG_ 719 demDoorExtMechSwPower_DCRR 1;
BA_ "GenSigSendType" SG_ 719 demDoorExtMechSwPowerLoss_DCRR 1;
BA_ "GenSigSendType" SG_ 719 demWindowHallSignalError_DCRR 1;
BA_ "GenSigSendType" SG_ 719 demWindowHallSnsPowerLoss_DCRR 1;
BA_ "GenSigSendType" SG_ 719 demWindowHallSignalLoss_DCRR 1;
BA_ "GenSigSendType" SG_ 719 demWindowVelocityTimeout_DCRR 1;
BA_ "GenSigSendType" SG_ 719 demCinchCloseSignalError_DCRR 1;
BA_ "GenSigSendType" SG_ 719 demReverseCinchTimeout_DCRR 1;
BA_ "GenSigSendType" SG_ 719 demCinchOpenSignalError_DCRR 1;
BA_ "GenSigSendType" SG_ 719 demDoorCinchTimeout_DCRR 1;
BA_ "GenSigSendType" SG_ 719 demDoorLatchOpenAlwaysOn_DCRR 1;
BA_ "GenSigSendType" SG_ 719 demDoorLatchOpenPowerLoss_DCRR 1;
BA_ "GenSigSendType" SG_ 719 demDoorLatchOpenSignalError_DCRR 1;
BA_ "GenSigSendType" SG_ 719 demDoorLatchOpenSignalLoss_DCRR 1;
BA_ "GenSigSendType" SG_ 719 demDoorLatchPawlSignalError_DCRR 1;
BA_ "GenSigSendType" SG_ 719 demDoorLatchPawlSignalLoss_DCRR 1;
BA_ "GenSigSendType" SG_ 719 demDoorLatchSensorSnError_DCRR 1;
BA_ "GenSigSendType" SG_ 719 demDoorLatchAjarSigLoss_DCRR 1;
BA_ "GenSigSendType" SG_ 719 demDoorBrakeHallSnLoss_DCRR 1;
BA_ "GenSigSendType" SG_ 719 demDoorHallSensorSnErr_DCRR 1;
BA_ "GenSigSendType" SG_ 719 doorHallSensorSlow_DCRR 1;
BA_ "GenSigSendType" SG_ 719 demDoorHallSensorFast_DCRR 1;
BA_ "GenSigSendType" SG_ 719 demDoorHallSensorSignalLoss_DCRR 1;
BA_ "GenSigSendType" SG_ 719 demMirrorMovetUncmd_DCRR 1;
BA_ "GenSigSendType" SG_ 719 demMirrorMovementFailure_DCRR 1;
BA_ "GenSigSendType" SG_ 718 demDEMNotification_DCRR 1;
BA_ "GenSigSendType" SG_ 718 demDEMAssert_DCRR 1;
BA_ "GenSigSendType" SG_ 718 demWindowDownFailure_DCRR 1;
BA_ "GenSigSendType" SG_ 718 demWindowDownUncommanded_DCRR 1;
BA_ "GenSigSendType" SG_ 718 demWindowUpUncommanded_DCRR 1;
BA_ "GenSigSendType" SG_ 718 demWindowUpFailure_DCRR 1;
BA_ "GenSigSendType" SG_ 718 demDoorCinchUncommanded_DCRR 1;
BA_ "GenSigSendType" SG_ 718 demDoorCinchReleaseFailure_DCRR 1;
BA_ "GenSigSendType" SG_ 718 demDoorMovementFault_DCRR 1;
BA_ "GenSigSendType" SG_ 718 demDoorCloseUncommanded_DCRR 1;
BA_ "GenSigSendType" SG_ 718 demDoorCloseFailure_DCRR 1;
BA_ "GenSigSendType" SG_ 718 demLatchTimeout_DCRR 1;
BA_ "GenSigSendType" SG_ 718 demDoorDirectionFault_DCRR 1;
BA_ "GenSigSendType" SG_ 718 demDoorOpenUncommanded_DCRR 1;
BA_ "GenSigSendType" SG_ 718 demDoorOpenFailure_DCRR 1;
BA_ "GenSigSendType" SG_ 718 demMirrorMotorSignalLoss_DCRR 1;
BA_ "GenSigSendType" SG_ 718 demMirrorMotorOvercurrent_DCRR 1;
BA_ "GenSigSendType" SG_ 718 demWindowMotorSignalLoss_DCRR 1;
BA_ "GenSigSendType" SG_ 718 demWindowCurrentFailure_DCRR 1;
BA_ "GenSigSendType" SG_ 718 demWindowMotorUndercurrent_DCRR 1;
BA_ "GenSigSendType" SG_ 718 demWindowMotorOvercurrent_DCRR 1;
BA_ "GenSigSendType" SG_ 718 demCinchMotorPowerLoss_DCRR 1;
BA_ "GenSigSendType" SG_ 718 demCinchMotorOvercurrent_DCRR 1;
BA_ "GenSigSendType" SG_ 718 demLatchUncommandedOpen_DCRR 1;
BA_ "GenSigSendType" SG_ 718 demDoorLatchStateError_DCRR 1;
BA_ "GenSigSendType" SG_ 718 demDoorLatchPowerLoss_DCRR 1;
BA_ "GenSigSendType" SG_ 718 demLatchMotorOvercurrent_DCRR 1;
BA_ "GenSigSendType" SG_ 718 demDoorBrakeMotorSignalLoss_DCRR 1;
BA_ "GenSigSendType" SG_ 718 demDoorBrakeOvercurrent_DCRR 1;
BA_ "GenSigSendType" SG_ 718 demDoorCurrentSignalLoss_DCRR 1;
BA_ "GenSigSendType" SG_ 718 demDoorMotorCurrentFailure_DCRR 1;
BA_ "GenSigSendType" SG_ 718 demDoorMotorOvercurrent_DCRR 1;
BA_ "GenSigSendType" SG_ 1192 demIRSensor2MIA_DCRL 1;
BA_ "GenSigSendType" SG_ 1192 demIRSensor1MIA_DCRL 1;
BA_ "GenSigSendType" SG_ 1192 demWinSwErr_DCRL 1;
BA_ "GenSigSendType" SG_ 1192 demWinSwMIA_DCRL 1;
BA_ "GenSigSendType" SG_ 1192 demLINNetworkFail_DCRL 1;
BA_ "GenSigSendType" SG_ 1192 demBodyCANAmbTempMsgErr_DCRL 1;
BA_ "GenSigSendType" SG_ 1192 demBodyCANAmbTempMsgMiss_DCRL 1;
BA_ "GenSigSendType" SG_ 1192 demBodyCANCrashMsgErr_DCRL 1;
BA_ "GenSigSendType" SG_ 1192 demBodyCANCrashMsgMiss_DCRL 1;
BA_ "GenSigSendType" SG_ 1192 demBodyCANChildLkMsgErr_DCRL 1;
BA_ "GenSigSendType" SG_ 1192 demBodyCANChildLkMsgMiss_DCRL 1;
BA_ "GenSigSendType" SG_ 1192 demBodyCANLockMessageError_DCRL 1;
BA_ "GenSigSendType" SG_ 1192 demBodyCANLkUnlkMsgMiss_DCRL 1;
BA_ "GenSigSendType" SG_ 1192 demBodyCANOpClMsgErr_DCRL 1;
BA_ "GenSigSendType" SG_ 1192 demBodyCANOpClMsgMiss_DCRL 1;
BA_ "GenSigSendType" SG_ 1192 demBodyCANIMUMessageError_DCRL 1;
BA_ "GenSigSendType" SG_ 1192 demBodyCANIMUMsgMiss_DCRL 1;
BA_ "GenSigSendType" SG_ 1192 demBodyCANVehSpdMsgErr_DCRL 1;
BA_ "GenSigSendType" SG_ 1192 demBodyCANVehSpdMsgMiss_DCRL 1;
BA_ "GenSigSendType" SG_ 1192 demBodyCANNetworkFailure_DCRL 1;
BA_ "GenSigSendType" SG_ 1192 demMirrorGlassPosSnsShCir_DCRL 1;
BA_ "GenSigSendType" SG_ 1192 demMirrorGlassPosSnsOpenCir_DCRL 1;
BA_ "GenSigSendType" SG_ 1192 demMirrorGlassPosSnsSnEr_DCRL 1;
BA_ "GenSigSendType" SG_ 1192 demMirrorGlassPosSnsSnLoss_DCRL 1;
BA_ "GenSigSendType" SG_ 1192 demMirrorGlassPosNotReached_DCRL 1;
BA_ "GenSigSendType" SG_ 1192 demMirrorGlassMvtUcmd_DCRL 1;
BA_ "GenSigSendType" SG_ 1192 demMirrorGlassMvFail_DCRL 1;
BA_ "GenSigSendType" SG_ 1192 demIntOpenSwSnEr_DCRL 1;
BA_ "GenSigSendType" SG_ 1192 demIntOpenSwSnLoss_DCRL 1;
BA_ "GenSigSendType" SG_ 1192 demIntRelSwSnEr_DCRL 1;
BA_ "GenSigSendType" SG_ 1192 demInteriorReleaseSwSnLoss_DCRL 1;
BA_ "GenSigSendType" SG_ 1192 demDoorUnlockSwSnError_DCRL 1;
BA_ "GenSigSendType" SG_ 687 demDoorLockSwitchSignalLoss_DCRL 1;
BA_ "GenSigSendType" SG_ 687 demDoorExtCapSwSnEr_DCRL 1;
BA_ "GenSigSendType" SG_ 687 demDoorExtCapSwSnLoss_DCRL 1;
BA_ "GenSigSendType" SG_ 687 demDoorExtCapSwPower_DCRL 1;
BA_ "GenSigSendType" SG_ 687 demDoorExtCapSwNoPower_DCRL 1;
BA_ "GenSigSendType" SG_ 687 demDoorExtMechSwSnEr_DCRL 1;
BA_ "GenSigSendType" SG_ 687 demDoorExtMechSwSnLoss_DCRL 1;
BA_ "GenSigSendType" SG_ 687 demDoorExtMechSwPower_DCRL 1;
BA_ "GenSigSendType" SG_ 687 demDoorExtMechSwPowerLoss_DCRL 1;
BA_ "GenSigSendType" SG_ 687 demWindowHallSignalError_DCRL 1;
BA_ "GenSigSendType" SG_ 687 demWindowHallSnsPowerLoss_DCRL 1;
BA_ "GenSigSendType" SG_ 687 demWindowHallSignalLoss_DCRL 1;
BA_ "GenSigSendType" SG_ 687 demWindowVelocityTimeout_DCRL 1;
BA_ "GenSigSendType" SG_ 687 demCinchCloseSignalError_DCRL 1;
BA_ "GenSigSendType" SG_ 687 demReverseCinchTimeout_DCRL 1;
BA_ "GenSigSendType" SG_ 687 demCinchOpenSignalError_DCRL 1;
BA_ "GenSigSendType" SG_ 687 demDoorCinchTimeout_DCRL 1;
BA_ "GenSigSendType" SG_ 687 demDoorLatchOpenAlwaysOn_DCRL 1;
BA_ "GenSigSendType" SG_ 687 demDoorLatchOpenPowerLoss_DCRL 1;
BA_ "GenSigSendType" SG_ 687 demDoorLatchOpenSignalError_DCRL 1;
BA_ "GenSigSendType" SG_ 687 demDoorLatchOpenSignalLoss_DCRL 1;
BA_ "GenSigSendType" SG_ 687 demDoorLatchPawlSignalError_DCRL 1;
BA_ "GenSigSendType" SG_ 687 demDoorLatchPawlSignalLoss_DCRL 1;
BA_ "GenSigSendType" SG_ 687 demDoorLatchSensorSnError_DCRL 1;
BA_ "GenSigSendType" SG_ 687 demDoorLatchAjarSigLoss_DCRL 1;
BA_ "GenSigSendType" SG_ 687 demDoorBrakeHallSnLoss_DCRL 1;
BA_ "GenSigSendType" SG_ 687 demDoorHallSensorSnErr_DCRL 1;
BA_ "GenSigSendType" SG_ 687 doorHallSensorSlow_DCRL 1;
BA_ "GenSigSendType" SG_ 687 demDoorHallSensorFast_DCRL 1;
BA_ "GenSigSendType" SG_ 687 demDoorHallSensorSignalLoss_DCRL 1;
BA_ "GenSigSendType" SG_ 687 demMirrorMovetUncmd_DCRL 1;
BA_ "GenSigSendType" SG_ 687 demMirrorMovementFailure_DCRL 1;
BA_ "GenSigSendType" SG_ 686 demDEMNotification_DCRL 1;
BA_ "GenSigSendType" SG_ 686 demDEMAssert_DCRL 1;
BA_ "GenSigSendType" SG_ 686 demWindowDownFailure_DCRL 1;
BA_ "GenSigSendType" SG_ 686 demWindowDownUncommanded_DCRL 1;
BA_ "GenSigSendType" SG_ 686 demWindowUpUncommanded_DCRL 1;
BA_ "GenSigSendType" SG_ 686 demWindowUpFailure_DCRL 1;
BA_ "GenSigSendType" SG_ 686 demDoorCinchUncommanded_DCRL 1;
BA_ "GenSigSendType" SG_ 686 demDoorCinchReleaseFailure_DCRL 1;
BA_ "GenSigSendType" SG_ 686 demDoorMovementFault_DCRL 1;
BA_ "GenSigSendType" SG_ 686 demDoorCloseUncommanded_DCRL 1;
BA_ "GenSigSendType" SG_ 686 demDoorCloseFailure_DCRL 1;
BA_ "GenSigSendType" SG_ 686 demLatchTimeout_DCRL 1;
BA_ "GenSigSendType" SG_ 686 demDoorDirectionFault_DCRL 1;
BA_ "GenSigSendType" SG_ 686 demDoorOpenUncommanded_DCRL 1;
BA_ "GenSigSendType" SG_ 686 demDoorOpenFailure_DCRL 1;
BA_ "GenSigSendType" SG_ 686 demMirrorMotorSignalLoss_DCRL 1;
BA_ "GenSigSendType" SG_ 686 demMirrorMotorOvercurrent_DCRL 1;
BA_ "GenSigSendType" SG_ 686 demWindowMotorSignalLoss_DCRL 1;
BA_ "GenSigSendType" SG_ 686 demWindowCurrentFailure_DCRL 1;
BA_ "GenSigSendType" SG_ 686 demWindowMotorUndercurrent_DCRL 1;
BA_ "GenSigSendType" SG_ 686 demWindowMotorOvercurrent_DCRL 1;
BA_ "GenSigSendType" SG_ 686 demCinchMotorPowerLoss_DCRL 1;
BA_ "GenSigSendType" SG_ 686 demCinchMotorOvercurrent_DCRL 1;
BA_ "GenSigSendType" SG_ 686 demLatchUncommandedOpen_DCRL 1;
BA_ "GenSigSendType" SG_ 686 demDoorLatchStateError_DCRL 1;
BA_ "GenSigSendType" SG_ 686 demDoorLatchPowerLoss_DCRL 1;
BA_ "GenSigSendType" SG_ 686 demLatchMotorOvercurrent_DCRL 1;
BA_ "GenSigSendType" SG_ 686 demDoorBrakeMotorSignalLoss_DCRL 1;
BA_ "GenSigSendType" SG_ 686 demDoorBrakeOvercurrent_DCRL 1;
BA_ "GenSigSendType" SG_ 686 demDoorCurrentSignalLoss_DCRL 1;
BA_ "GenSigSendType" SG_ 686 demDoorMotorCurrentFailure_DCRL 1;
BA_ "GenSigSendType" SG_ 686 demDoorMotorOvercurrent_DCRL 1;
BA_ "GenSigSendType" SG_ 1120 demIRSensor2MIA_DCFL 1;
BA_ "GenSigSendType" SG_ 1120 demIRSensor1MIA_DCFL 1;
BA_ "GenSigSendType" SG_ 1120 demWinSwErr_DCFL 1;
BA_ "GenSigSendType" SG_ 1120 demWinSwMIA_DCFL 1;
BA_ "GenSigSendType" SG_ 1120 demLINNetworkFail_DCFL 1;
BA_ "GenSigSendType" SG_ 1120 demBodyCANAmbTempMsgErr_DCFL 1;
BA_ "GenSigSendType" SG_ 1120 demBodyCANAmbTempMsgMiss_DCFL 1;
BA_ "GenSigSendType" SG_ 1120 demBodyCANCrashMsgErr_DCFL 1;
BA_ "GenSigSendType" SG_ 1120 demBodyCANCrashMsgMiss_DCFL 1;
BA_ "GenSigSendType" SG_ 1120 demBodyCANChildLkMsgErr_DCFL 1;
BA_ "GenSigSendType" SG_ 1120 demBodyCANChildLkMsgMiss_DCFL 1;
BA_ "GenSigSendType" SG_ 1120 demBodyCANLockMessageError_DCFL 1;
BA_ "GenSigSendType" SG_ 1120 demBodyCANLkUnlkMsgMiss_DCFL 1;
BA_ "GenSigSendType" SG_ 1120 demBodyCANOpClMsgErr_DCFL 1;
BA_ "GenSigSendType" SG_ 1120 demBodyCANOpClMsgMiss_DCFL 1;
BA_ "GenSigSendType" SG_ 1120 demBodyCANIMUMessageError_DCFL 1;
BA_ "GenSigSendType" SG_ 1120 demBodyCANIMUMsgMiss_DCFL 1;
BA_ "GenSigSendType" SG_ 1120 demBodyCANVehSpdMsgErr_DCFL 1;
BA_ "GenSigSendType" SG_ 1120 demBodyCANVehSpdMsgMiss_DCFL 1;
BA_ "GenSigSendType" SG_ 1120 demBodyCANNetworkFailure_DCFL 1;
BA_ "GenSigSendType" SG_ 1120 demMirrorGlassPosSnsShCir_DCFL 1;
BA_ "GenSigSendType" SG_ 1120 demMirrorGlassPosSnsOpenCir_DCFL 1;
BA_ "GenSigSendType" SG_ 1120 demMirrorGlassPosSnsSnEr_DCFL 1;
BA_ "GenSigSendType" SG_ 1120 demMirrorGlassPosSnsSnLoss_DCFL 1;
BA_ "GenSigSendType" SG_ 1120 demMirrorGlassPosNotReached_DCFL 1;
BA_ "GenSigSendType" SG_ 1120 demMirrorGlassMvtUcmd_DCFL 1;
BA_ "GenSigSendType" SG_ 1120 demMirrorGlassMvFail_DCFL 1;
BA_ "GenSigSendType" SG_ 1120 demIntOpenSwSnEr_DCFL 1;
BA_ "GenSigSendType" SG_ 1120 demIntOpenSwSnLoss_DCFL 1;
BA_ "GenSigSendType" SG_ 1120 demIntRelSwSnEr_DCFL 1;
BA_ "GenSigSendType" SG_ 1120 demInteriorReleaseSwSnLoss_DCFL 1;
BA_ "GenSigSendType" SG_ 1120 demDoorUnlockSwSnError_DCFL 1;
BA_ "GenSigSendType" SG_ 615 demDoorLockSwitchSignalLoss_DCFL 1;
BA_ "GenSigSendType" SG_ 615 demDoorExtCapSwSnEr_DCFL 1;
BA_ "GenSigSendType" SG_ 615 demDoorExtCapSwSnLoss_DCFL 1;
BA_ "GenSigSendType" SG_ 615 demDoorExtCapSwPower_DCFL 1;
BA_ "GenSigSendType" SG_ 615 demDoorExtCapSwNoPower_DCFL 1;
BA_ "GenSigSendType" SG_ 615 demDoorExtMechSwSnEr_DCFL 1;
BA_ "GenSigSendType" SG_ 615 demDoorExtMechSwSnLoss_DCFL 1;
BA_ "GenSigSendType" SG_ 615 demDoorExtMechSwPower_DCFL 1;
BA_ "GenSigSendType" SG_ 615 demDoorExtMechSwPowerLoss_DCFL 1;
BA_ "GenSigSendType" SG_ 615 demWindowHallSignalError_DCFL 1;
BA_ "GenSigSendType" SG_ 615 demWindowHallSnsPowerLoss_DCFL 1;
BA_ "GenSigSendType" SG_ 615 demWindowHallSignalLoss_DCFL 1;
BA_ "GenSigSendType" SG_ 615 demWindowVelocityTimeout_DCFL 1;
BA_ "GenSigSendType" SG_ 615 demCinchCloseSignalError_DCFL 1;
BA_ "GenSigSendType" SG_ 615 demReverseCinchTimeout_DCFL 1;
BA_ "GenSigSendType" SG_ 615 demCinchOpenSignalError_DCFL 1;
BA_ "GenSigSendType" SG_ 615 demDoorCinchTimeout_DCFL 1;
BA_ "GenSigSendType" SG_ 615 demDoorLatchOpenAlwaysOn_DCFL 1;
BA_ "GenSigSendType" SG_ 615 demDoorLatchOpenPowerLoss_DCFL 1;
BA_ "GenSigSendType" SG_ 615 demDoorLatchOpenSignalError_DCFL 1;
BA_ "GenSigSendType" SG_ 615 demDoorLatchOpenSignalLoss_DCFL 1;
BA_ "GenSigSendType" SG_ 615 demDoorLatchPawlSignalError_DCFL 1;
BA_ "GenSigSendType" SG_ 615 demDoorLatchPawlSignalLoss_DCFL 1;
BA_ "GenSigSendType" SG_ 615 demDoorLatchSensorSnError_DCFL 1;
BA_ "GenSigSendType" SG_ 615 demDoorLatchAjarSigLoss_DCFL 1;
BA_ "GenSigSendType" SG_ 615 demDoorBrakeHallSnLoss_DCFL 1;
BA_ "GenSigSendType" SG_ 615 demDoorHallSensorSnErr_DCFL 1;
BA_ "GenSigSendType" SG_ 615 doorHallSensorSlow_DCFL 1;
BA_ "GenSigSendType" SG_ 615 demDoorHallSensorFast_DCFL 1;
BA_ "GenSigSendType" SG_ 615 demDoorHallSensorSignalLoss_DCFL 1;
BA_ "GenSigSendType" SG_ 615 demMirrorMovetUncmd_DCFL 1;
BA_ "GenSigSendType" SG_ 615 demMirrorMovementFailure_DCFL 1;
BA_ "GenSigSendType" SG_ 614 demDEMNotification_DCFL 1;
BA_ "GenSigSendType" SG_ 614 demDEMAssert_DCFL 1;
BA_ "GenSigSendType" SG_ 614 demWindowDownFailure_DCFL 1;
BA_ "GenSigSendType" SG_ 614 demWindowDownUncommanded_DCFL 1;
BA_ "GenSigSendType" SG_ 614 demWindowUpUncommanded_DCFL 1;
BA_ "GenSigSendType" SG_ 614 demWindowUpFailure_DCFL 1;
BA_ "GenSigSendType" SG_ 614 demDoorCinchUncommanded_DCFL 1;
BA_ "GenSigSendType" SG_ 614 demDoorCinchReleaseFailure_DCFL 1;
BA_ "GenSigSendType" SG_ 614 demDoorMovementFault_DCFL 1;
BA_ "GenSigSendType" SG_ 614 demDoorCloseUncommanded_DCFL 1;
BA_ "GenSigSendType" SG_ 614 demDoorCloseFailure_DCFL 1;
BA_ "GenSigSendType" SG_ 614 demLatchTimeout_DCFL 1;
BA_ "GenSigSendType" SG_ 614 demDoorDirectionFault_DCFL 1;
BA_ "GenSigSendType" SG_ 614 demDoorOpenUncommanded_DCFL 1;
BA_ "GenSigSendType" SG_ 614 demDoorOpenFailure_DCFL 1;
BA_ "GenSigSendType" SG_ 614 demMirrorMotorSignalLoss_DCFL 1;
BA_ "GenSigSendType" SG_ 614 demMirrorMotorOvercurrent_DCFL 1;
BA_ "GenSigSendType" SG_ 614 demWindowMotorSignalLoss_DCFL 1;
BA_ "GenSigSendType" SG_ 614 demWindowCurrentFailure_DCFL 1;
BA_ "GenSigSendType" SG_ 614 demWindowMotorUndercurrent_DCFL 1;
BA_ "GenSigSendType" SG_ 614 demWindowMotorOvercurrent_DCFL 1;
BA_ "GenSigSendType" SG_ 614 demCinchMotorPowerLoss_DCFL 1;
BA_ "GenSigSendType" SG_ 614 demCinchMotorOvercurrent_DCFL 1;
BA_ "GenSigSendType" SG_ 614 demLatchUncommandedOpen_DCFL 1;
BA_ "GenSigSendType" SG_ 614 demDoorLatchStateError_DCFL 1;
BA_ "GenSigSendType" SG_ 614 demDoorLatchPowerLoss_DCFL 1;
BA_ "GenSigSendType" SG_ 614 demLatchMotorOvercurrent_DCFL 1;
BA_ "GenSigSendType" SG_ 614 demDoorBrakeMotorSignalLoss_DCFL 1;
BA_ "GenSigSendType" SG_ 614 demDoorBrakeOvercurrent_DCFL 1;
BA_ "GenSigSendType" SG_ 614 demDoorCurrentSignalLoss_DCFL 1;
BA_ "GenSigSendType" SG_ 614 demDoorMotorCurrentFailure_DCFL 1;
BA_ "GenSigSendType" SG_ 614 demDoorMotorOvercurrent_DCFL 1;
VAL_ 632 doorDemGesture_DEMFL 3 "SNA" 1 "Swipe" 0 "Tap" ;
VAL_ 664 doorDemGesture_DEMFR 3 "SNA" 1 "Swipe" 0 "Tap" ;
VAL_ 696 doorDemGesture_DEMRL 3 "SNA" 1 "Swipe" 0 "Tap" ;
VAL_ 736 doorDemGesture_DEMRR 3 "SNA" 1 "Swipe" 0 "Tap" ;
VAL_ 808 doorDosObstruction_DOSFL 3 "SNA" 1 "True" 0 "False" ;
VAL_ 872 doorDosObstruction_DOSFR 3 "SNA" 1 "True" 0 "False" ;
VAL_ 880 doorDosObstruction_DOSRL 3 "SNA" 1 "True" 0 "False" ;
VAL_ 888 doorDosObstruction_DOSRR 3 "SNA" 1 "True" 0 "False" ;
VAL_ 1036 lightDomer_IHUB 3 "SNA" 1 "On" 0 "Off" ;
VAL_ 1036 lightMrlrr_IHUB 3 "SNA" 1 "On" 0 "Off" ;
VAL_ 1036 lightMrlrl_IHUB 3 "SNA" 1 "On" 0 "Off" ;
VAL_ 1036 lightAllFunctional_IHUB 3 "SNA" 1 "On" 0 "Off" ;
VAL_ 1036 lightRightDomef_IHUB 3 "SNA" 1 "On" 0 "Off" ;
VAL_ 1036 lightCenterDomef_IHUB 3 "SNA" 1 "On" 0 "Off" ;
VAL_ 1036 lightLeftDomef_IHUB 3 "SNA" 1 "On" 0 "Off" ;
VAL_ 1794 resetCause_RCLR 255 "SNA" 18 "EcuSpecificReason3" 17 "EcuSpecificReason2" 16 "EcuSpecificReason1" 15 "Reserved10" 14 "Reserved9" 13 "Reserved8" 12 "Reserved7" 11 "Reserved6" 10 "Reserved5" 9 "Reserved4" 8 "Reserved3" 7 "Reserved2" 6 "Reserved1" 5 "SoftwareException" 4 "UdsResetRequest" 3 "PowerMonitor" 2 "WatchdogTimer" 1 "WakeSignal" 0 "NormalWakeCanOrRtc" ;
VAL_ 1794 bootloaderStuckSignal_RCLR 255 "SNA" 18 "EcuSpecificReason3" 17 "EcuSpecificReason2" 16 "EcuSpecificReason1" 15 "Reserved12" 14 "Reserved11" 13 "Reserved10" 12 "Reserved9" 11 "Reserved8" 10 "Reserved7" 9 "Reserved6" 8 "Reserved5" 7 "Reserved4" 6 "Reserved3" 5 "Reserved2" 4 "Reserved1" 3 "BootloaderSelfCheckFail" 2 "ApplicationCrcfail" 1 "ApplicationNotPresent" 0 "NormalStartup" ;
VAL_ 1786 resetCause_RCLL 255 "SNA" 18 "EcuSpecificReason3" 17 "EcuSpecificReason2" 16 "EcuSpecificReason1" 15 "Reserved10" 14 "Reserved9" 13 "Reserved8" 12 "Reserved7" 11 "Reserved6" 10 "Reserved5" 9 "Reserved4" 8 "Reserved3" 7 "Reserved2" 6 "Reserved1" 5 "SoftwareException" 4 "UdsResetRequest" 3 "PowerMonitor" 2 "WatchdogTimer" 1 "WakeSignal" 0 "NormalWakeCanOrRtc" ;
VAL_ 1786 bootloaderStuckSignal_RCLL 255 "SNA" 18 "EcuSpecificReason3" 17 "EcuSpecificReason2" 16 "EcuSpecificReason1" 15 "Reserved12" 14 "Reserved11" 13 "Reserved10" 12 "Reserved9" 11 "Reserved8" 10 "Reserved7" 9 "Reserved6" 8 "Reserved5" 7 "Reserved4" 6 "Reserved3" 5 "Reserved2" 4 "Reserved1" 3 "BootloaderSelfCheckFail" 2 "ApplicationCrcfail" 1 "ApplicationNotPresent" 0 "NormalStartup" ;
VAL_ 1770 resetCause_LGL 255 "SNA" 18 "EcuSpecificReason3" 17 "EcuSpecificReason2" 16 "EcuSpecificReason1" 15 "Reserved10" 14 "Reserved9" 13 "Reserved8" 12 "Reserved7" 11 "Reserved6" 10 "Reserved5" 9 "Reserved4" 8 "Reserved3" 7 "Reserved2" 6 "Reserved1" 5 "SoftwareException" 4 "UdsResetRequest" 3 "PowerMonitor" 2 "WatchdogTimer" 1 "WakeSignal" 0 "NormalWakeCanOrRtc" ;
VAL_ 1770 bootloaderStuckSignal_LGL 255 "SNA" 18 "EcuSpecificReason3" 17 "EcuSpecificReason2" 16 "EcuSpecificReason1" 15 "Reserved12" 14 "Reserved11" 13 "Reserved10" 12 "Reserved9" 11 "Reserved8" 10 "Reserved7" 9 "Reserved6" 8 "Reserved5" 7 "Reserved4" 6 "Reserved3" 5 "Reserved2" 4 "Reserved1" 3 "BootloaderSelfCheckFail" 2 "ApplicationCrcfail" 1 "ApplicationNotPresent" 0 "NormalStartup" ;
VAL_ 1810 resetCause_ACCL 255 "SNA" 18 "EcuSpecificReason3" 17 "EcuSpecificReason2" 16 "EcuSpecificReason1" 15 "Reserved10" 14 "Reserved9" 13 "Reserved8" 12 "Reserved7" 11 "Reserved6" 10 "Reserved5" 9 "Reserved4" 8 "Reserved3" 7 "Reserved2" 6 "Reserved1" 5 "SoftwareException" 4 "UdsResetRequest" 3 "PowerMonitor" 2 "WatchdogTimer" 1 "WakeSignal" 0 "NormalWakeCanOrRtc" ;
VAL_ 1810 bootloaderStuckSignal_ACCL 255 "SNA" 18 "EcuSpecificReason3" 17 "EcuSpecificReason2" 16 "EcuSpecificReason1" 15 "Reserved12" 14 "Reserved11" 13 "Reserved10" 12 "Reserved9" 11 "Reserved8" 10 "Reserved7" 9 "Reserved6" 8 "Reserved5" 7 "Reserved4" 6 "Reserved3" 5 "Reserved2" 4 "Reserved1" 3 "BootloaderSelfCheckFail" 2 "ApplicationCrcfail" 1 "ApplicationNotPresent" 0 "NormalStartup" ;
VAL_ 531 rsdStatus_FBCM 3 "SNA" 2 "Unknown" 1 "Moving" 0 "Idle" ;
VAL_ 1288 seatCushionTiltCmdRR_BGW 3 "SNA" 2 "MoveDown" 1 "MoveUp" 0 "Stop" ;
VAL_ 1288 seatCushionTiltCmdRL_BGW 3 "SNA" 2 "MoveDown" 1 "MoveUp" 0 "Stop" ;
VAL_ 1288 seatLegExtCmdRR_BGW 3 "SNA" 2 "MoveBackward" 1 "MoveForward" 0 "Stop" ;
VAL_ 1288 seatBackCmdRR_BGW 3 "SNA" 2 "MoveBackward" 1 "MoveForward" 0 "Stop" ;
VAL_ 1288 seatShoulderBolsterCmdRR_BGW 3 "SNA" 2 "MoveBackward" 1 "MoveForward" 0 "NoCommand" ;
VAL_ 1288 seatShoulderBolsterCmdRL_BGW 3 "SNA" 2 "MoveBackward" 1 "MoveForward" 0 "NoCommand" ;
VAL_ 1288 seatBackCmdRL_BGW 3 "SNA" 2 "MoveBackward" 1 "MoveForward" 0 "Stop" ;
VAL_ 1288 seatLegSwivelCmdRL_BGW 3 "SNA" 2 "MoveDown" 1 "MoveUp" 0 "Stop" ;
VAL_ 1288 seatLegSwivelCmdRR_BGW 3 "SNA" 2 "MoveDown" 1 "MoveUp" 0 "Stop" ;
VAL_ 1288 seatLegExtCmdRL_BGW 3 "SNA" 2 "MoveBackward" 1 "MoveForward" 0 "Stop" ;
VAL_ 1288 seatBackLumbarCmdRR_BGW 7 "SNA" 4 "MoveDown" 3 "MoveUp" 2 "MoveRearward" 1 "MoveForward" 0 "NoCommand" ;
VAL_ 1288 seatBackLumbarCmdRL_BGW 7 "SNA" 4 "MoveDown" 3 "MoveUp" 2 "MoveRearward" 1 "MoveForward" 0 "NoCommand" ;
VAL_ 780 bPillarScreenReq_BGW 7 "SNA" 4 "Doors" 3 "Charging" 2 "Welcome" 1 "Home" 0 "Off" ;
VAL_ 823 eventsUnread_DBPC 3 "SNA" 2 "NotUsed" 1 "NewEvents" 0 "NoNewEvents" ;
VAL_ 823 eventNotification_DBPC 3 "SNA" 2 "Untested" 1 "Set" 0 "Cleared" ;
VAL_ 823 eventAssert_DBPC 3 "SNA" 2 "Untested" 1 "Set" 0 "Cleared" ;
VAL_ 723 eventsUnread_RRSM 3 "SNA" 2 "NotUsed" 1 "NewEvents" 0 "NoNewEvents" ;
VAL_ 723 eventNotification_RRSM 3 "SNA" 2 "Untested" 1 "Set" 0 "Cleared" ;
VAL_ 723 eventAssert_RRSM 3 "SNA" 2 "Untested" 1 "Set" 0 "Cleared" ;
VAL_ 871 eventsUnread_RRDC 3 "SNA" 2 "NotUsed" 1 "NewEvents" 0 "NoNewEvents" ;
VAL_ 871 eventNotification_RRDC 3 "SNA" 2 "Untested" 1 "Set" 0 "Cleared" ;
VAL_ 871 eventAssert_RRDC 3 "SNA" 2 "Untested" 1 "Set" 0 "Cleared" ;
VAL_ 691 eventAssert_RLSM 3 "SNA" 2 "Untested" 1 "Set" 0 "Cleared" ;
VAL_ 691 eventsUnread_RLSM 3 "SNA" 2 "NotUsed" 1 "NewEvents" 0 "NoNewEvents" ;
VAL_ 691 eventNotification_RLSM 3 "SNA" 2 "Untested" 1 "Set" 0 "Cleared" ;
VAL_ 863 eventsUnread_RLDC 3 "SNA" 2 "NotUsed" 1 "NewEvents" 0 "NoNewEvents" ;
VAL_ 863 eventNotification_RLDC 3 "SNA" 2 "Untested" 1 "Set" 0 "Cleared" ;
VAL_ 863 eventAssert_RLDC 3 "SNA" 2 "Untested" 1 "Set" 0 "Cleared" ;
VAL_ 1280 eventsUnread_RCLR 3 "SNA" 2 "NotUsed" 1 "NewEvents" 0 "NoNewEvents" ;
VAL_ 1280 eventNotification_RCLR 3 "SNA" 2 "Untested" 1 "Set" 0 "Cleared" ;
VAL_ 1280 eventAssert_RCLR 3 "SNA" 2 "Untested" 1 "Set" 0 "Cleared" ;
VAL_ 1272 eventsUnread_RCLL 3 "SNA" 2 "NotUsed" 1 "NewEvents" 0 "NoNewEvents" ;
VAL_ 1272 eventNotification_RCLL 3 "SNA" 2 "Untested" 1 "Set" 0 "Cleared" ;
VAL_ 1272 eventAssert_RCLL 3 "SNA" 2 "Untested" 1 "Set" 0 "Cleared" ;
VAL_ 659 eventsUnread_PSM 3 "SNA" 2 "NotUsed" 1 "NewEvents" 0 "NoNewEvents" ;
VAL_ 659 eventNotification_PSM 3 "SNA" 2 "Untested" 1 "Set" 0 "Cleared" ;
VAL_ 659 eventAssert_PSM 3 "SNA" 2 "Untested" 1 "Set" 0 "Cleared" ;
VAL_ 1258 eventsUnread_LGL 3 "SNA" 2 "NotUsed" 1 "NewEvents" 0 "NoNewEvents" ;
VAL_ 1258 eventNotification_LGL 3 "SNA" 2 "Untested" 1 "Set" 0 "Cleared" ;
VAL_ 1258 eventAssert_LGL 3 "SNA" 2 "Untested" 1 "Set" 0 "Cleared" ;
VAL_ 591 eventsUnread_HLR 3 "SNA" 2 "NotUsed" 1 "NewEvents" 0 "NoNewEvents" ;
VAL_ 591 eventNotification_HLR 3 "SNA" 2 "Untested" 1 "Set" 0 "Cleared" ;
VAL_ 591 eventAssert_HLR 3 "SNA" 2 "Untested" 1 "Set" 0 "Cleared" ;
VAL_ 583 eventsUnread_HLL 3 "SNA" 2 "NotUsed" 1 "NewEvents" 0 "NoNewEvents" ;
VAL_ 583 eventNotification_HLL 3 "SNA" 2 "Untested" 1 "Set" 0 "Cleared" ;
VAL_ 583 eventAssert_HLL 3 "SNA" 2 "Untested" 1 "Set" 0 "Cleared" ;
VAL_ 855 eventsUnread_FRDC 3 "SNA" 2 "NotUsed" 1 "NewEvents" 0 "NoNewEvents" ;
VAL_ 855 eventNotification_FRDC 3 "SNA" 2 "Untested" 1 "Set" 0 "Cleared" ;
VAL_ 855 eventAssert_FRDC 3 "SNA" 2 "Untested" 1 "Set" 0 "Cleared" ;
VAL_ 847 eventsUnread_FLDC 3 "SNA" 2 "NotUsed" 1 "NewEvents" 0 "NoNewEvents" ;
VAL_ 847 eventNotification_FLDC 3 "SNA" 2 "Untested" 1 "Set" 0 "Cleared" ;
VAL_ 847 eventAssert_FLDC 3 "SNA" 2 "Untested" 1 "Set" 0 "Cleared" ;
VAL_ 1345 eventsUnread_FFL 3 "SNA" 2 "NotUsed" 1 "NewEvents" 0 "NoNewEvents" ;
VAL_ 1345 eventNotification_FFL 3 "SNA" 2 "Untested" 1 "Set" 0 "Cleared" ;
VAL_ 1345 eventAssert_FFL 3 "SNA" 2 "Untested" 1 "Set" 0 "Cleared" ;
VAL_ 806 eventsUnread_ECPM 3 "SNA" 2 "NotUsed" 1 "NewEvents" 0 "NoNewEvents" ;
VAL_ 806 eventNotification_ECPM 3 "SNA" 2 "Untested" 1 "Set" 0 "Cleared" ;
VAL_ 806 eventAssert_ECPM 3 "SNA" 2 "Untested" 1 "Set" 0 "Cleared" ;
VAL_ 627 eventsUnread_DSM 3 "SNA" 2 "NotUsed" 1 "NewEvents" 0 "NoNewEvents" ;
VAL_ 627 eventNotification_DSM 3 "SNA" 2 "Untested" 1 "Set" 0 "Cleared" ;
VAL_ 627 eventAssert_DSM 3 "SNA" 2 "Untested" 1 "Set" 0 "Cleared" ;
VAL_ 1296 eventsUnread_ACCL 3 "SNA" 2 "NotUsed" 1 "NewEvents" 0 "NoNewEvents" ;
VAL_ 1296 eventNotification_ACCL 3 "SNA" 2 "Untested" 1 "Set" 0 "Cleared" ;
VAL_ 1296 eventAssert_ACCL 3 "SNA" 2 "Untested" 1 "Set" 0 "Cleared" ;
VAL_ 11 ignoreHoodOpen_IHUB 3 "SNA" 1 "True" 0 "False" ;
VAL_ 11 unlockPreference_IHUB 3 "SNA" 1 "UnlockAllDoors" 0 "UnlockNearestDoor" ;
VAL_ 11 transportMode_IHUB 3 "SNA" 1 "On" 0 "Off" ;
VAL_ 11 towMode_IHUB 3 "SNA" 1 "On" 0 "Off" ;
VAL_ 11 theftDetectionEnable_IHUB 3 "SNA" 1 "Enable" 0 "Disable" ;
VAL_ 11 unlockOnPark_IHUB 3 "SNA" 1 "True" 0 "False" ;
VAL_ 11 inactivityLock_IHUB 3 "SNA" 1 "True" 0 "False" ;
VAL_ 11 mirrorPowerFoldAutoOnOff_IHUB 3 "SNA" 1 "On" 0 "Off" ;
VAL_ 11 distanceUnits_IHUB 3 "SNA" 1 "Mile" 0 "Kilometer" ;
VAL_ 11 chargeDisplaySetting_IHUB 3 "SNA" 1 "Percentage" 0 "Miles" ;
VAL_ 11 autoMirrorTilt_IHUB 3 "SNA" 1 "True" 0 "False" ;
VAL_ 11 autoDoorLock_IHUB 3 "SNA" 1 "True" 0 "False" ;
VAL_ 11 autoLowBeamReq_IHUB 3 "SNA" 1 "On" 0 "Off" ;
VAL_ 11 tempDisplayUnits_IHUB 3 "SNA" 1 "Fahrenheit" 0 "Celsius" ;
VAL_ 11 languageSelection_IHUB 3 "SNA" 1 "Chinese" 0 "English" ;
VAL_ 1194 doorLatchStatus_DCRL 6 "Unknown" 7 "SNA" 3 "Error" 2 "Primary" 1 "Secondary" 0 "Open" ;
VAL_ 1194 doorLatchDoorAjar_DCRL 3 "SNA" 2 "Error" 1 "On" 0 "Off" ;
VAL_ 1194 doorLatchDoorOpen_DCRL 3 "SNA" 2 "Error" 1 "On" 0 "Off" ;
VAL_ 1194 doorLatchPawlClosed_DCRL 3 "SNA" 2 "Error" 1 "On" 0 "Off" ;
VAL_ 1194 doorStopSource_DCRL 15 "SNA" 7 "Overcurrent" 6 "PreventativeObstacleDetection" 5 "ReactiveObstacleDetection" 4 "InteriorButton" 3 "ExteriorButton" 2 "Cpillar" 1 "Bpillar" 0 "Ihub" ;
VAL_ 1194 doorCloseSource_DCRL 6 "CpillarClose" 7 "SNA" 5 "BpillarClose" 4 "BrakePressed" 3 "ExteriorButton" 2 "InteriorButton" 1 "EdgeSwitch" 0 "IhubClose" ;
VAL_ 1194 doorOpenSource_DCRL 255 "SNA" 10 "CpillarOpen" 9 "CpillarPop" 8 "BpillarOpen" 7 "BpillarPop" 6 "InteriorButtonPop" 5 "InteriorButtonOpen" 4 "ExteriorButtonPop" 3 "ExteriorButtonOpen" 2 "EdgeSwitch" 1 "IhubOpen" 0 "IhubPop" ;
VAL_ 1194 windowOpenSource_DCRL 7 "SNA" 4 "IhubOpen" 3 "Dcrr" 2 "Dcrl" 1 "Dcfr" 0 "Dcfl" ;
VAL_ 1194 windowCloseSource_DCRL 7 "SNA" 4 "IhubClose" 3 "Dcrr" 2 "Dcrl" 1 "Dcfr" 0 "Dcfl" ;
VAL_ 1162 doorLatchStatus_DCFR 6 "Unknown" 7 "SNA" 3 "Error" 2 "Primary" 1 "Secondary" 0 "Open" ;
VAL_ 1162 doorLatchDoorAjar_DCFR 3 "SNA" 2 "Error" 1 "On" 0 "Off" ;
VAL_ 1162 doorLatchDoorOpen_DCFR 3 "SNA" 2 "Error" 1 "On" 0 "Off" ;
VAL_ 1162 doorLatchPawlClosed_DCFR 3 "SNA" 2 "Error" 1 "On" 0 "Off" ;
VAL_ 1162 doorStopSource_DCFR 15 "SNA" 7 "Overcurrent" 6 "PreventativeObstacleDetection" 5 "ReactiveObstacleDetection" 4 "InteriorButton" 3 "ExteriorButton" 2 "Cpillar" 1 "Bpillar" 0 "Ihub" ;
VAL_ 1162 doorCloseSource_DCFR 6 "CpillarClose" 7 "SNA" 5 "BpillarClose" 4 "BrakePressed" 3 "ExteriorButton" 2 "InteriorButton" 1 "EdgeSwitch" 0 "IhubClose" ;
VAL_ 1162 doorOpenSource_DCFR 255 "SNA" 10 "CpillarOpen" 9 "CpillarPop" 8 "BpillarOpen" 7 "BpillarPop" 6 "InteriorButtonPop" 5 "InteriorButtonOpen" 4 "ExteriorButtonPop" 3 "ExteriorButtonOpen" 2 "EdgeSwitch" 1 "IhubOpen" 0 "IhubPop" ;
VAL_ 1162 windowOpenSource_DCFR 7 "SNA" 4 "IhubOpen" 3 "Dcrr" 2 "Dcrl" 1 "Dcfr" 0 "Dcfl" ;
VAL_ 1162 windowCloseSource_DCFR 7 "SNA" 4 "IhubClose" 3 "Dcrr" 2 "Dcrl" 1 "Dcfr" 0 "Dcfl" ;
VAL_ 1226 doorLatchStatus_DCRR 6 "Unknown" 7 "SNA" 3 "Error" 2 "Primary" 1 "Secondary" 0 "Open" ;
VAL_ 1226 doorLatchDoorAjar_DCRR 3 "SNA" 2 "Error" 1 "On" 0 "Off" ;
VAL_ 1226 doorLatchDoorOpen_DCRR 3 "SNA" 2 "Error" 1 "On" 0 "Off" ;
VAL_ 1226 doorLatchPawlClosed_DCRR 3 "SNA" 2 "Error" 1 "On" 0 "Off" ;
VAL_ 1226 doorStopSource_DCRR 15 "SNA" 7 "Overcurrent" 6 "PreventativeObstacleDetection" 5 "ReactiveObstacleDetection" 4 "InteriorButton" 3 "ExteriorButton" 2 "Cpillar" 1 "Bpillar" 0 "Ihub" ;
VAL_ 1226 doorCloseSource_DCRR 6 "CpillarClose" 7 "SNA" 5 "BpillarClose" 4 "BrakePressed" 3 "ExteriorButton" 2 "InteriorButton" 1 "EdgeSwitch" 0 "IhubClose" ;
VAL_ 1226 doorOpenSource_DCRR 255 "SNA" 10 "CpillarOpen" 9 "CpillarPop" 8 "BpillarOpen" 7 "BpillarPop" 6 "InteriorButtonPop" 5 "InteriorButtonOpen" 4 "ExteriorButtonPop" 3 "ExteriorButtonOpen" 2 "EdgeSwitch" 1 "IhubOpen" 0 "IhubPop" ;
VAL_ 1226 windowOpenSource_DCRR 7 "SNA" 4 "IhubOpen" 3 "Dcrr" 2 "Dcrl" 1 "Dcfr" 0 "Dcfl" ;
VAL_ 1226 windowCloseSource_DCRR 7 "SNA" 4 "IhubClose" 3 "Dcrr" 2 "Dcrl" 1 "Dcfr" 0 "Dcfl" ;
VAL_ 1122 doorLatchStatus_DCFL 6 "Unknown" 7 "SNA" 3 "Error" 2 "Primary" 1 "Secondary" 0 "Open" ;
VAL_ 1122 doorLatchDoorAjar_DCFL 3 "SNA" 2 "Error" 1 "On" 0 "Off" ;
VAL_ 1122 doorLatchDoorOpen_DCFL 3 "SNA" 2 "Error" 1 "On" 0 "Off" ;
VAL_ 1122 doorLatchPawlClosed_DCFL 3 "SNA" 2 "Error" 1 "On" 0 "Off" ;
VAL_ 1122 doorStopSource_DCFL 15 "SNA" 7 "Overcurrent" 6 "PreventativeObstacleDetection" 5 "ReactiveObstacleDetection" 4 "InteriorButton" 3 "ExteriorButton" 2 "Cpillar" 1 "Bpillar" 0 "Ihub" ;
VAL_ 1122 doorCloseSource_DCFL 6 "CpillarClose" 7 "SNA" 5 "BpillarClose" 4 "BrakePressed" 3 "ExteriorButton" 2 "InteriorButton" 1 "EdgeSwitch" 0 "IhubClose" ;
VAL_ 1122 doorOpenSource_DCFL 255 "SNA" 10 "CpillarOpen" 9 "CpillarPop" 8 "BpillarOpen" 7 "BpillarPop" 6 "InteriorButtonPop" 5 "InteriorButtonOpen" 4 "ExteriorButtonPop" 3 "ExteriorButtonOpen" 2 "EdgeSwitch" 1 "IhubOpen" 0 "IhubPop" ;
VAL_ 1122 windowOpenSource_DCFL 7 "SNA" 4 "IhubOpen" 3 "Dcrr" 2 "Dcrl" 1 "Dcfr" 0 "Dcfl" ;
VAL_ 1122 windowCloseSource_DCFL 7 "SNA" 4 "IhubClose" 3 "Dcrr" 2 "Dcrl" 1 "Dcfr" 0 "Dcfl" ;
VAL_ 12 passengerInRsdZone_BGW 1 "True" 0 "False" ;
VAL_ 12 driverInRsdZone_BGW 1 "True" 0 "False" ;
VAL_ 12 roofShadePosStatusFront_BGW 255 "SNA" ;
VAL_ 12 roofShadePosStatusRear_BGW 255 "SNA" ;
VAL_ 1225 fimDisableWinAutoUpdownFunc_DCRR 3 "SNA" 2 "InhibitedOnlyRemoteCause" 1 "InhibitedLocalCause" 0 "NotInhibited" ;
VAL_ 1225 fimLimitVehicleSpeed_DCRR 3 "SNA" 2 "InhibitedOnlyRemoteCause" 1 "InhibitedLocalCause" 0 "NotInhibited" ;
VAL_ 1225 demDoorBrakeFeedbackFailure_DCRR 3 "SNA" 2 "Untested" 1 "Set" 0 "Cleared" ;
VAL_ 1225 fimDisablePowerWindowFunc_DCRR 3 "SNA" 2 "InhibitedOnlyRemoteCause" 1 "InhibitedLocalCause" 0 "NotInhibited" ;
VAL_ 1225 fimDisablePowerDoorFunction_DCRR 3 "SNA" 2 "InhibitedOnlyRemoteCause" 1 "InhibitedLocalCause" 0 "NotInhibited" ;
VAL_ 1225 fimDisableMirrorMovement_DCRR 3 "SNA" 2 "InhibitedOnlyRemoteCause" 1 "InhibitedLocalCause" 0 "NotInhibited" ;
VAL_ 1225 fimDisableMirrorFoldFunc_DCRR 3 "SNA" 2 "InhibitedOnlyRemoteCause" 1 "InhibitedLocalCause" 0 "NotInhibited" ;
VAL_ 1225 fimDisableCinchFunction_DCRR 3 "SNA" 2 "InhibitedOnlyRemoteCause" 1 "InhibitedLocalCause" 0 "NotInhibited" ;
VAL_ 1225 demWinMotorCurrentSigLoss_DCRR 3 "SNA" 2 "Untested" 1 "Set" 0 "Cleared" ;
VAL_ 1225 demDoorUnlockSwitchSigError_DCRR 3 "SNA" 2 "Untested" 1 "Set" 0 "Cleared" ;
VAL_ 1225 demDoorMotorUnderCurrent_DCRR 3 "SNA" 2 "Untested" 1 "Set" 0 "Cleared" ;
VAL_ 1225 demDoorExtCapSwitchSigError_DCRR 3 "SNA" 2 "Untested" 1 "Set" 0 "Cleared" ;
VAL_ 1225 demCinchMotorUnderCurrent_DCRR 3 "SNA" 2 "Untested" 1 "Set" 0 "Cleared" ;
VAL_ 1225 demIRSensor2SignalError_DCRR 3 "SNA" 2 "Untested" 1 "Set" 0 "Cleared" ;
VAL_ 1225 demIRSensor1SignalError_DCRR 3 "SNA" 2 "Untested" 1 "Set" 0 "Cleared" ;
VAL_ 1193 fimDisableWinAutoUpdownFunc_DCRL 3 "SNA" 2 "InhibitedOnlyRemoteCause" 1 "InhibitedLocalCause" 0 "NotInhibited" ;
VAL_ 1193 fimLimitVehicleSpeed_DCRL 3 "SNA" 2 "InhibitedOnlyRemoteCause" 1 "InhibitedLocalCause" 0 "NotInhibited" ;
VAL_ 1193 demDoorBrakeFeedbackFailure_DCRL 3 "SNA" 2 "Untested" 1 "Set" 0 "Cleared" ;
VAL_ 1193 fimDisablePowerWindowFunc_DCRL 3 "SNA" 2 "InhibitedOnlyRemoteCause" 1 "InhibitedLocalCause" 0 "NotInhibited" ;
VAL_ 1193 fimDisablePowerDoorFunction_DCRL 3 "SNA" 2 "InhibitedOnlyRemoteCause" 1 "InhibitedLocalCause" 0 "NotInhibited" ;
VAL_ 1193 fimDisableMirrorMovement_DCRL 3 "SNA" 2 "InhibitedOnlyRemoteCause" 1 "InhibitedLocalCause" 0 "NotInhibited" ;
VAL_ 1193 fimDisableMirrorFoldFunc_DCRL 3 "SNA" 2 "InhibitedOnlyRemoteCause" 1 "InhibitedLocalCause" 0 "NotInhibited" ;
VAL_ 1193 fimDisableCinchFunction_DCRL 3 "SNA" 2 "InhibitedOnlyRemoteCause" 1 "InhibitedLocalCause" 0 "NotInhibited" ;
VAL_ 1193 demWinMotorCurrentSigLoss_DCRL 3 "SNA" 2 "Untested" 1 "Set" 0 "Cleared" ;
VAL_ 1193 demDoorUnlockSwitchSigError_DCRL 3 "SNA" 2 "Untested" 1 "Set" 0 "Cleared" ;
VAL_ 1193 demDoorMotorUnderCurrent_DCRL 3 "SNA" 2 "Untested" 1 "Set" 0 "Cleared" ;
VAL_ 1193 demDoorExtCapSwitchSigError_DCRL 3 "SNA" 2 "Untested" 1 "Set" 0 "Cleared" ;
VAL_ 1193 demCinchMotorUnderCurrent_DCRL 3 "SNA" 2 "Untested" 1 "Set" 0 "Cleared" ;
VAL_ 1193 demIRSensor2SignalError_DCRL 3 "SNA" 2 "Untested" 1 "Set" 0 "Cleared" ;
VAL_ 1193 demIRSensor1SignalError_DCRL 3 "SNA" 2 "Untested" 1 "Set" 0 "Cleared" ;
VAL_ 1161 fimDisableWinAutoUpdownFunc_DCFR 3 "SNA" 2 "InhibitedOnlyRemoteCause" 1 "InhibitedLocalCause" 0 "NotInhibited" ;
VAL_ 1161 fimLimitVehicleSpeed_DCFR 3 "SNA" 2 "InhibitedOnlyRemoteCause" 1 "InhibitedLocalCause" 0 "NotInhibited" ;
VAL_ 1161 demDoorBrakeFeedbackFailure_DCFR 3 "SNA" 2 "Untested" 1 "Set" 0 "Cleared" ;
VAL_ 1161 fimDisablePowerWindowFunc_DCFR 3 "SNA" 2 "InhibitedOnlyRemoteCause" 1 "InhibitedLocalCause" 0 "NotInhibited" ;
VAL_ 1161 fimDisablePowerDoorFunction_DCFR 3 "SNA" 2 "InhibitedOnlyRemoteCause" 1 "InhibitedLocalCause" 0 "NotInhibited" ;
VAL_ 1161 fimDisableMirrorMovement_DCFR 3 "SNA" 2 "InhibitedOnlyRemoteCause" 1 "InhibitedLocalCause" 0 "NotInhibited" ;
VAL_ 1161 fimDisableMirrorFoldFunc_DCFR 3 "SNA" 2 "InhibitedOnlyRemoteCause" 1 "InhibitedLocalCause" 0 "NotInhibited" ;
VAL_ 1161 fimDisableCinchFunction_DCFR 3 "SNA" 2 "InhibitedOnlyRemoteCause" 1 "InhibitedLocalCause" 0 "NotInhibited" ;
VAL_ 1161 demWinMotorCurrentSigLoss_DCFR 3 "SNA" 2 "Untested" 1 "Set" 0 "Cleared" ;
VAL_ 1161 demDoorUnlockSwitchSigError_DCFR 3 "SNA" 2 "Untested" 1 "Set" 0 "Cleared" ;
VAL_ 1161 demDoorMotorUnderCurrent_DCFR 3 "SNA" 2 "Untested" 1 "Set" 0 "Cleared" ;
VAL_ 1161 demDoorExtCapSwitchSigError_DCFR 3 "SNA" 2 "Untested" 1 "Set" 0 "Cleared" ;
VAL_ 1161 demCinchMotorUnderCurrent_DCFR 3 "SNA" 2 "Untested" 1 "Set" 0 "Cleared" ;
VAL_ 1161 demIRSensor2SignalError_DCFR 3 "SNA" 2 "Untested" 1 "Set" 0 "Cleared" ;
VAL_ 1161 demIRSensor1SignalError_DCFR 3 "SNA" 2 "Untested" 1 "Set" 0 "Cleared" ;
VAL_ 1121 fimDisableWinAutoUpdownFunc_DCFL 3 "SNA" 2 "InhibitedOnlyRemoteCause" 1 "InhibitedLocalCause" 0 "NotInhibited" ;
VAL_ 1121 fimLimitVehicleSpeed_DCFL 3 "SNA" 2 "InhibitedOnlyRemoteCause" 1 "InhibitedLocalCause" 0 "NotInhibited" ;
VAL_ 1121 fimDisablePowerWindowFunc_DCFL 3 "SNA" 2 "InhibitedOnlyRemoteCause" 1 "InhibitedLocalCause" 0 "NotInhibited" ;
VAL_ 1121 fimDisablePowerDoorFunction_DCFL 3 "SNA" 2 "InhibitedOnlyRemoteCause" 1 "InhibitedLocalCause" 0 "NotInhibited" ;
VAL_ 1121 fimDisableMirrorMovement_DCFL 3 "SNA" 2 "InhibitedOnlyRemoteCause" 1 "InhibitedLocalCause" 0 "NotInhibited" ;
VAL_ 1121 fimDisableMirrorFoldFunc_DCFL 3 "SNA" 2 "InhibitedOnlyRemoteCause" 1 "InhibitedLocalCause" 0 "NotInhibited" ;
VAL_ 1121 fimDisableCinchFunction_DCFL 3 "SNA" 2 "InhibitedOnlyRemoteCause" 1 "InhibitedLocalCause" 0 "NotInhibited" ;
VAL_ 1121 demWinMotorCurrentSigLoss_DCFL 3 "SNA" 2 "Untested" 1 "Set" 0 "Cleared" ;
VAL_ 1121 demDoorUnlockSwitchSigError_DCFL 3 "SNA" 2 "Untested" 1 "Set" 0 "Cleared" ;
VAL_ 1121 demDoorMotorUnderCurrent_DCFL 3 "SNA" 2 "Untested" 1 "Set" 0 "Cleared" ;
VAL_ 1121 demDoorExtCapSwitchSigError_DCFL 3 "SNA" 2 "Untested" 1 "Set" 0 "Cleared" ;
VAL_ 1121 demDoorBrakeFeedbackFailure_DCFL 3 "SNA" 2 "Untested" 1 "Set" 0 "Cleared" ;
VAL_ 1121 demCinchMotorUnderCurrent_DCFL 3 "SNA" 2 "Untested" 1 "Set" 0 "Cleared" ;
VAL_ 1121 demIRSensor2SignalError_DCFL 3 "SNA" 2 "Untested" 1 "Set" 0 "Cleared" ;
VAL_ 1121 demIRSensor1SignalError_DCFL 3 "SNA" 2 "Untested" 1 "Set" 0 "Cleared" ;
VAL_ 13 demDEMNotification_BGW 3 "SNA" 2 "Untested" 1 "Set" 0 "Cleared" ;
VAL_ 13 demDEMAssert_BGW 3 "SNA" 2 "Untested" 1 "Set" 0 "Cleared" ;
VAL_ 13 demLIN2Unresponsive_BGW 3 "SNA" 2 "Untested" 1 "Set" 0 "Cleared" ;
VAL_ 13 demLIN1Unresponsive_BGW 3 "SNA" 2 "Untested" 1 "Set" 0 "Cleared" ;
VAL_ 13 demTelematicsCANNetworkError_BGW 3 "SNA" 2 "Untested" 1 "Set" 0 "Cleared" ;
VAL_ 13 demThermalCANNetworkError_BGW 3 "SNA" 2 "Untested" 1 "Set" 0 "Cleared" ;
VAL_ 13 demEthernetIHUBMIA_BGW 3 "SNA" 2 "Untested" 1 "Set" 0 "Cleared" ;
VAL_ 13 demEthernetSDCMMIA_BGW 3 "SNA" 2 "Untested" 1 "Set" 0 "Cleared" ;
VAL_ 13 demEthernetUnresponsive_BGW 3 "SNA" 2 "Untested" 1 "Set" 0 "Cleared" ;
VAL_ 13 demRearFogLightNoCurrent_BGW 3 "SNA" 2 "Untested" 1 "Set" 0 "Cleared" ;
VAL_ 13 demFBCMWakeInMIA_BGW 3 "SNA" 2 "Untested" 1 "Set" 0 "Cleared" ;
VAL_ 13 demDCFRWakeInMIA_BGW 3 "SNA" 2 "Untested" 1 "Set" 0 "Cleared" ;
VAL_ 13 demDCFLWakeInMIA_BGW 3 "SNA" 2 "Untested" 1 "Set" 0 "Cleared" ;
VAL_ 13 demLiftgateLatchHomeSnLoss_BGW 3 "SNA" 2 "Untested" 1 "Set" 0 "Cleared" ;
VAL_ 13 demLiftgatePawlSignalMissing_BGW 3 "SNA" 2 "Untested" 1 "Set" 0 "Cleared" ;
VAL_ 13 demLiftgateAjarSignalMissing_BGW 3 "SNA" 2 "Untested" 1 "Set" 0 "Cleared" ;
VAL_ 13 demLiftgateOpenSignalMissing_BGW 3 "SNA" 2 "Untested" 1 "Set" 0 "Cleared" ;
VAL_ 13 demLiftgateHallSnsRtSnLoss_BGW 3 "SNA" 2 "Untested" 1 "Set" 0 "Cleared" ;
VAL_ 13 demLiftgateHallSnsLeftSnLoss_BGW 3 "SNA" 2 "Untested" 1 "Set" 0 "Cleared" ;
VAL_ 13 demLiftgateMotorRightOvCrn_BGW 3 "SNA" 2 "Untested" 1 "Set" 0 "Cleared" ;
VAL_ 13 demLiftgateMotorRightSnLoss_BGW 3 "SNA" 2 "Untested" 1 "Set" 0 "Cleared" ;
VAL_ 13 demLiftgateMotorRightSnErr_BGW 3 "SNA" 2 "Untested" 1 "Set" 0 "Cleared" ;
VAL_ 13 demLiftgateMotorOvercurrent_BGW 3 "SNA" 2 "Untested" 1 "Set" 0 "Cleared" ;
VAL_ 13 demLiftgateMotorLeftSnLoss_BGW 3 "SNA" 2 "Untested" 1 "Set" 0 "Cleared" ;
VAL_ 13 demLiftgateMotorLeftSnErr_BGW 3 "SNA" 2 "Untested" 1 "Set" 0 "Cleared" ;
VAL_ 13 demLiftgateFailsToClose_BGW 3 "SNA" 2 "Untested" 1 "Set" 0 "Cleared" ;
VAL_ 13 demLiftgateClosesUncommanded_BGW 3 "SNA" 2 "Untested" 1 "Set" 0 "Cleared" ;
VAL_ 13 demLgMotorOpAttLt_BGW 3 "SNA" 2 "Untested" 1 "Set" 0 "Cleared" ;
VAL_ 13 demLiftgateMotorFailsToOpen_BGW 3 "SNA" 2 "Untested" 1 "Set" 0 "Cleared" ;
VAL_ 1224 demIntOpenSwSnLoss_DCRR 3 "SNA" 2 "Untested" 1 "Set" 0 "Cleared" ;
VAL_ 1224 demIntRelSwSnEr_DCRR 3 "SNA" 2 "Untested" 1 "Set" 0 "Cleared" ;
VAL_ 1224 demInteriorReleaseSwSnLoss_DCRR 3 "SNA" 2 "Untested" 1 "Set" 0 "Cleared" ;
VAL_ 1224 demDoorUnlockSwSnError_DCRR 3 "SNA" 2 "Untested" 1 "Set" 0 "Cleared" ;
VAL_ 1224 demMirrorGlassPosNotReached_DCRR 3 "SNA" 2 "Untested" 1 "Set" 0 "Cleared" ;
VAL_ 1224 demMirrorGlassMvtUcmd_DCRR 3 "SNA" 2 "Untested" 1 "Set" 0 "Cleared" ;
VAL_ 1224 demMirrorGlassMvFail_DCRR 3 "SNA" 2 "Untested" 1 "Set" 0 "Cleared" ;
VAL_ 1224 demIntOpenSwSnEr_DCRR 3 "SNA" 2 "Untested" 1 "Set" 0 "Cleared" ;
VAL_ 1224 demMirrorGlassPosSnsShCir_DCRR 3 "SNA" 2 "Untested" 1 "Set" 0 "Cleared" ;
VAL_ 1224 demMirrorGlassPosSnsOpenCir_DCRR 3 "SNA" 2 "Untested" 1 "Set" 0 "Cleared" ;
VAL_ 1224 demMirrorGlassPosSnsSnEr_DCRR 3 "SNA" 2 "Untested" 1 "Set" 0 "Cleared" ;
VAL_ 1224 demMirrorGlassPosSnsSnLoss_DCRR 3 "SNA" 2 "Untested" 1 "Set" 0 "Cleared" ;
VAL_ 1224 demBodyCANIMUMsgMiss_DCRR 3 "SNA" 2 "Untested" 1 "Set" 0 "Cleared" ;
VAL_ 1224 demBodyCANVehSpdMsgErr_DCRR 3 "SNA" 2 "Untested" 1 "Set" 0 "Cleared" ;
VAL_ 1224 demBodyCANVehSpdMsgMiss_DCRR 3 "SNA" 2 "Untested" 1 "Set" 0 "Cleared" ;
VAL_ 1224 demBodyCANNetworkFailure_DCRR 3 "SNA" 2 "Untested" 1 "Set" 0 "Cleared" ;
VAL_ 1224 demBodyCANLkUnlkMsgMiss_DCRR 3 "SNA" 2 "Untested" 1 "Set" 0 "Cleared" ;
VAL_ 1224 demBodyCANOpClMsgErr_DCRR 3 "SNA" 2 "Untested" 1 "Set" 0 "Cleared" ;
VAL_ 1224 demBodyCANOpClMsgMiss_DCRR 3 "SNA" 2 "Untested" 1 "Set" 0 "Cleared" ;
VAL_ 1224 demBodyCANIMUMessageError_DCRR 3 "SNA" 2 "Untested" 1 "Set" 0 "Cleared" ;
VAL_ 1224 demBodyCANCrashMsgMiss_DCRR 3 "SNA" 2 "Untested" 1 "Set" 0 "Cleared" ;
VAL_ 1224 demBodyCANChildLkMsgErr_DCRR 3 "SNA" 2 "Untested" 1 "Set" 0 "Cleared" ;
VAL_ 1224 demBodyCANChildLkMsgMiss_DCRR 3 "SNA" 2 "Untested" 1 "Set" 0 "Cleared" ;
VAL_ 1224 demBodyCANLockMessageError_DCRR 3 "SNA" 2 "Untested" 1 "Set" 0 "Cleared" ;
VAL_ 1224 demLINNetworkFail_DCRR 3 "SNA" 2 "Untested" 1 "Set" 0 "Cleared" ;
VAL_ 1224 demBodyCANAmbTempMsgErr_DCRR 3 "SNA" 2 "Untested" 1 "Set" 0 "Cleared" ;
VAL_ 1224 demBodyCANAmbTempMsgMiss_DCRR 3 "SNA" 2 "Untested" 1 "Set" 0 "Cleared" ;
VAL_ 1224 demBodyCANCrashMsgErr_DCRR 3 "SNA" 2 "Untested" 1 "Set" 0 "Cleared" ;
VAL_ 1224 demIRSensor2MIA_DCRR 3 "SNA" 2 "Untested" 1 "Set" 0 "Cleared" ;
VAL_ 1224 demIRSensor1MIA_DCRR 3 "SNA" 2 "Untested" 1 "Set" 0 "Cleared" ;
VAL_ 1224 demWinSwErr_DCRR 3 "SNA" 2 "Untested" 1 "Set" 0 "Cleared" ;
VAL_ 1224 demWinSwMIA_DCRR 3 "SNA" 2 "Untested" 1 "Set" 0 "Cleared" ;
VAL_ 719 demDoorLockSwitchSignalLoss_DCRR 3 "SNA" 2 "Untested" 1 "Set" 0 "Cleared" ;
VAL_ 719 demDoorExtCapSwSnEr_DCRR 3 "SNA" 2 "Untested" 1 "Set" 0 "Cleared" ;
VAL_ 719 demDoorExtCapSwSnLoss_DCRR 3 "SNA" 2 "Untested" 1 "Set" 0 "Cleared" ;
VAL_ 719 demDoorExtCapSwPower_DCRR 3 "SNA" 2 "Untested" 1 "Set" 0 "Cleared" ;
VAL_ 719 demDoorExtCapSwNoPower_DCRR 3 "SNA" 2 "Untested" 1 "Set" 0 "Cleared" ;
VAL_ 719 demDoorExtMechSwSnEr_DCRR 3 "SNA" 2 "Untested" 1 "Set" 0 "Cleared" ;
VAL_ 719 demDoorExtMechSwSnLoss_DCRR 3 "SNA" 2 "Untested" 1 "Set" 0 "Cleared" ;
VAL_ 719 demDoorExtMechSwPower_DCRR 3 "SNA" 2 "Untested" 1 "Set" 0 "Cleared" ;
VAL_ 719 demDoorExtMechSwPowerLoss_DCRR 3 "SNA" 2 "Untested" 1 "Set" 0 "Cleared" ;
VAL_ 719 demWindowHallSignalError_DCRR 3 "SNA" 2 "Untested" 1 "Set" 0 "Cleared" ;
VAL_ 719 demWindowHallSnsPowerLoss_DCRR 3 "SNA" 2 "Untested" 1 "Set" 0 "Cleared" ;
VAL_ 719 demWindowHallSignalLoss_DCRR 3 "SNA" 2 "Untested" 1 "Set" 0 "Cleared" ;
VAL_ 719 demWindowVelocityTimeout_DCRR 3 "SNA" 2 "Untested" 1 "Set" 0 "Cleared" ;
VAL_ 719 demCinchCloseSignalError_DCRR 3 "SNA" 2 "Untested" 1 "Set" 0 "Cleared" ;
VAL_ 719 demReverseCinchTimeout_DCRR 3 "SNA" 2 "Untested" 1 "Set" 0 "Cleared" ;
VAL_ 719 demCinchOpenSignalError_DCRR 3 "SNA" 2 "Untested" 1 "Set" 0 "Cleared" ;
VAL_ 719 demDoorCinchTimeout_DCRR 3 "SNA" 2 "Untested" 1 "Set" 0 "Cleared" ;
VAL_ 719 demDoorLatchOpenAlwaysOn_DCRR 3 "SNA" 2 "Untested" 1 "Set" 0 "Cleared" ;
VAL_ 719 demDoorLatchOpenPowerLoss_DCRR 3 "SNA" 2 "Untested" 1 "Set" 0 "Cleared" ;
VAL_ 719 demDoorLatchOpenSignalError_DCRR 3 "SNA" 2 "Untested" 1 "Set" 0 "Cleared" ;
VAL_ 719 demDoorLatchOpenSignalLoss_DCRR 3 "SNA" 2 "Untested" 1 "Set" 0 "Cleared" ;
VAL_ 719 demDoorLatchPawlSignalError_DCRR 3 "SNA" 2 "Untested" 1 "Set" 0 "Cleared" ;
VAL_ 719 demDoorLatchPawlSignalLoss_DCRR 3 "SNA" 2 "Untested" 1 "Set" 0 "Cleared" ;
VAL_ 719 demDoorLatchSensorSnError_DCRR 3 "SNA" 2 "Untested" 1 "Set" 0 "Cleared" ;
VAL_ 719 demDoorLatchAjarSigLoss_DCRR 3 "SNA" 2 "Untested" 1 "Set" 0 "Cleared" ;
VAL_ 719 demDoorBrakeHallSnLoss_DCRR 3 "SNA" 2 "Untested" 1 "Set" 0 "Cleared" ;
VAL_ 719 demDoorHallSensorSnErr_DCRR 3 "SNA" 2 "Untested" 1 "Set" 0 "Cleared" ;
VAL_ 719 doorHallSensorSlow_DCRR 3 "SNA" 2 "Untested" 1 "Set" 0 "Cleared" ;
VAL_ 719 demDoorHallSensorFast_DCRR 3 "SNA" 2 "Untested" 1 "Set" 0 "Cleared" ;
VAL_ 719 demDoorHallSensorSignalLoss_DCRR 3 "SNA" 2 "Untested" 1 "Set" 0 "Cleared" ;
VAL_ 719 demMirrorMovetUncmd_DCRR 3 "SNA" 2 "Untested" 1 "Set" 0 "Cleared" ;
VAL_ 719 demMirrorMovementFailure_DCRR 3 "SNA" 2 "Untested" 1 "Set" 0 "Cleared" ;
VAL_ 718 demDEMNotification_DCRR 3 "SNA" 2 "Untested" 1 "Set" 0 "Cleared" ;
VAL_ 718 demDEMAssert_DCRR 3 "SNA" 2 "Untested" 1 "Set" 0 "Cleared" ;
VAL_ 718 demWindowDownFailure_DCRR 3 "SNA" 2 "Untested" 1 "Set" 0 "Cleared" ;
VAL_ 718 demWindowDownUncommanded_DCRR 3 "SNA" 2 "Untested" 1 "Set" 0 "Cleared" ;
VAL_ 718 demWindowUpUncommanded_DCRR 3 "SNA" 2 "Untested" 1 "Set" 0 "Cleared" ;
VAL_ 718 demWindowUpFailure_DCRR 3 "SNA" 2 "Untested" 1 "Set" 0 "Cleared" ;
VAL_ 718 demDoorCinchUncommanded_DCRR 3 "SNA" 2 "Untested" 1 "Set" 0 "Cleared" ;
VAL_ 718 demDoorCinchReleaseFailure_DCRR 3 "SNA" 2 "Untested" 1 "Set" 0 "Cleared" ;
VAL_ 718 demDoorMovementFault_DCRR 3 "SNA" 2 "Untested" 1 "Set" 0 "Cleared" ;
VAL_ 718 demDoorCloseUncommanded_DCRR 3 "SNA" 2 "Untested" 1 "Set" 0 "Cleared" ;
VAL_ 718 demDoorCloseFailure_DCRR 3 "SNA" 2 "Untested" 1 "Set" 0 "Cleared" ;
VAL_ 718 demLatchTimeout_DCRR 3 "SNA" 2 "Untested" 1 "Set" 0 "Cleared" ;
VAL_ 718 demDoorDirectionFault_DCRR 3 "SNA" 2 "Untested" 1 "Set" 0 "Cleared" ;
VAL_ 718 demDoorOpenUncommanded_DCRR 3 "SNA" 2 "Untested" 1 "Set" 0 "Cleared" ;
VAL_ 718 demDoorOpenFailure_DCRR 3 "SNA" 2 "Untested" 1 "Set" 0 "Cleared" ;
VAL_ 718 demMirrorMotorSignalLoss_DCRR 3 "SNA" 2 "Untested" 1 "Set" 0 "Cleared" ;
VAL_ 718 demMirrorMotorOvercurrent_DCRR 3 "SNA" 2 "Untested" 1 "Set" 0 "Cleared" ;
VAL_ 718 demWindowMotorSignalLoss_DCRR 3 "SNA" 2 "Untested" 1 "Set" 0 "Cleared" ;
VAL_ 718 demWindowCurrentFailure_DCRR 3 "SNA" 2 "Untested" 1 "Set" 0 "Cleared" ;
VAL_ 718 demWindowMotorUndercurrent_DCRR 3 "SNA" 2 "Untested" 1 "Set" 0 "Cleared" ;
VAL_ 718 demWindowMotorOvercurrent_DCRR 3 "SNA" 2 "Untested" 1 "Set" 0 "Cleared" ;
VAL_ 718 demCinchMotorPowerLoss_DCRR 3 "SNA" 2 "Untested" 1 "Set" 0 "Cleared" ;
VAL_ 718 demCinchMotorOvercurrent_DCRR 3 "SNA" 2 "Untested" 1 "Set" 0 "Cleared" ;
VAL_ 718 demLatchUncommandedOpen_DCRR 3 "SNA" 2 "Untested" 1 "Set" 0 "Cleared" ;
VAL_ 718 demDoorLatchStateError_DCRR 3 "SNA" 2 "Untested" 1 "Set" 0 "Cleared" ;
VAL_ 718 demDoorLatchPowerLoss_DCRR 3 "SNA" 2 "Untested" 1 "Set" 0 "Cleared" ;
VAL_ 718 demLatchMotorOvercurrent_DCRR 3 "SNA" 2 "Untested" 1 "Set" 0 "Cleared" ;
VAL_ 718 demDoorBrakeMotorSignalLoss_DCRR 3 "SNA" 2 "Untested" 1 "Set" 0 "Cleared" ;
VAL_ 718 demDoorBrakeOvercurrent_DCRR 3 "SNA" 2 "Untested" 1 "Set" 0 "Cleared" ;
VAL_ 718 demDoorCurrentSignalLoss_DCRR 3 "SNA" 2 "Untested" 1 "Set" 0 "Cleared" ;
VAL_ 718 demDoorMotorCurrentFailure_DCRR 3 "SNA" 2 "Untested" 1 "Set" 0 "Cleared" ;
VAL_ 718 demDoorMotorOvercurrent_DCRR 3 "SNA" 2 "Untested" 1 "Set" 0 "Cleared" ;
VAL_ 1192 demIRSensor2MIA_DCRL 3 "SNA" 2 "Untested" 1 "Set" 0 "Cleared" ;
VAL_ 1192 demIRSensor1MIA_DCRL 3 "SNA" 2 "Untested" 1 "Set" 0 "Cleared" ;
VAL_ 1192 demWinSwErr_DCRL 3 "SNA" 2 "Untested" 1 "Set" 0 "Cleared" ;
VAL_ 1192 demWinSwMIA_DCRL 3 "SNA" 2 "Untested" 1 "Set" 0 "Cleared" ;
VAL_ 1192 demLINNetworkFail_DCRL 3 "SNA" 2 "Untested" 1 "Set" 0 "Cleared" ;
VAL_ 1192 demBodyCANAmbTempMsgErr_DCRL 3 "SNA" 2 "Untested" 1 "Set" 0 "Cleared" ;
VAL_ 1192 demBodyCANAmbTempMsgMiss_DCRL 3 "SNA" 2 "Untested" 1 "Set" 0 "Cleared" ;
VAL_ 1192 demBodyCANCrashMsgErr_DCRL 3 "SNA" 2 "Untested" 1 "Set" 0 "Cleared" ;
VAL_ 1192 demBodyCANCrashMsgMiss_DCRL 3 "SNA" 2 "Untested" 1 "Set" 0 "Cleared" ;
VAL_ 1192 demBodyCANChildLkMsgErr_DCRL 3 "SNA" 2 "Untested" 1 "Set" 0 "Cleared" ;
VAL_ 1192 demBodyCANChildLkMsgMiss_DCRL 3 "SNA" 2 "Untested" 1 "Set" 0 "Cleared" ;
VAL_ 1192 demBodyCANLockMessageError_DCRL 3 "SNA" 2 "Untested" 1 "Set" 0 "Cleared" ;
VAL_ 1192 demBodyCANLkUnlkMsgMiss_DCRL 3 "SNA" 2 "Untested" 1 "Set" 0 "Cleared" ;
VAL_ 1192 demBodyCANOpClMsgErr_DCRL 3 "SNA" 2 "Untested" 1 "Set" 0 "Cleared" ;
VAL_ 1192 demBodyCANOpClMsgMiss_DCRL 3 "SNA" 2 "Untested" 1 "Set" 0 "Cleared" ;
VAL_ 1192 demBodyCANIMUMessageError_DCRL 3 "SNA" 2 "Untested" 1 "Set" 0 "Cleared" ;
VAL_ 1192 demBodyCANIMUMsgMiss_DCRL 3 "SNA" 2 "Untested" 1 "Set" 0 "Cleared" ;
VAL_ 1192 demBodyCANVehSpdMsgErr_DCRL 3 "SNA" 2 "Untested" 1 "Set" 0 "Cleared" ;
VAL_ 1192 demBodyCANVehSpdMsgMiss_DCRL 3 "SNA" 2 "Untested" 1 "Set" 0 "Cleared" ;
VAL_ 1192 demBodyCANNetworkFailure_DCRL 3 "SNA" 2 "Untested" 1 "Set" 0 "Cleared" ;
VAL_ 1192 demMirrorGlassPosSnsShCir_DCRL 3 "SNA" 2 "Untested" 1 "Set" 0 "Cleared" ;
VAL_ 1192 demMirrorGlassPosSnsOpenCir_DCRL 3 "SNA" 2 "Untested" 1 "Set" 0 "Cleared" ;
VAL_ 1192 demMirrorGlassPosSnsSnEr_DCRL 3 "SNA" 2 "Untested" 1 "Set" 0 "Cleared" ;
VAL_ 1192 demMirrorGlassPosSnsSnLoss_DCRL 3 "SNA" 2 "Untested" 1 "Set" 0 "Cleared" ;
VAL_ 1192 demMirrorGlassPosNotReached_DCRL 3 "SNA" 2 "Untested" 1 "Set" 0 "Cleared" ;
VAL_ 1192 demMirrorGlassMvtUcmd_DCRL 3 "SNA" 2 "Untested" 1 "Set" 0 "Cleared" ;
VAL_ 1192 demMirrorGlassMvFail_DCRL 3 "SNA" 2 "Untested" 1 "Set" 0 "Cleared" ;
VAL_ 1192 demIntOpenSwSnEr_DCRL 3 "SNA" 2 "Untested" 1 "Set" 0 "Cleared" ;
VAL_ 1192 demIntOpenSwSnLoss_DCRL 3 "SNA" 2 "Untested" 1 "Set" 0 "Cleared" ;
VAL_ 1192 demIntRelSwSnEr_DCRL 3 "SNA" 2 "Untested" 1 "Set" 0 "Cleared" ;
VAL_ 1192 demInteriorReleaseSwSnLoss_DCRL 3 "SNA" 2 "Untested" 1 "Set" 0 "Cleared" ;
VAL_ 1192 demDoorUnlockSwSnError_DCRL 3 "SNA" 2 "Untested" 1 "Set" 0 "Cleared" ;
VAL_ 687 demDoorLockSwitchSignalLoss_DCRL 3 "SNA" 2 "Untested" 1 "Set" 0 "Cleared" ;
VAL_ 687 demDoorExtCapSwSnEr_DCRL 3 "SNA" 2 "Untested" 1 "Set" 0 "Cleared" ;
VAL_ 687 demDoorExtCapSwSnLoss_DCRL 3 "SNA" 2 "Untested" 1 "Set" 0 "Cleared" ;
VAL_ 687 demDoorExtCapSwPower_DCRL 3 "SNA" 2 "Untested" 1 "Set" 0 "Cleared" ;
VAL_ 687 demDoorExtCapSwNoPower_DCRL 3 "SNA" 2 "Untested" 1 "Set" 0 "Cleared" ;
VAL_ 687 demDoorExtMechSwSnEr_DCRL 3 "SNA" 2 "Untested" 1 "Set" 0 "Cleared" ;
VAL_ 687 demDoorExtMechSwSnLoss_DCRL 3 "SNA" 2 "Untested" 1 "Set" 0 "Cleared" ;
VAL_ 687 demDoorExtMechSwPower_DCRL 3 "SNA" 2 "Untested" 1 "Set" 0 "Cleared" ;
VAL_ 687 demDoorExtMechSwPowerLoss_DCRL 3 "SNA" 2 "Untested" 1 "Set" 0 "Cleared" ;
VAL_ 687 demWindowHallSignalError_DCRL 3 "SNA" 2 "Untested" 1 "Set" 0 "Cleared" ;
VAL_ 687 demWindowHallSnsPowerLoss_DCRL 3 "SNA" 2 "Untested" 1 "Set" 0 "Cleared" ;
VAL_ 687 demWindowHallSignalLoss_DCRL 3 "SNA" 2 "Untested" 1 "Set" 0 "Cleared" ;
VAL_ 687 demWindowVelocityTimeout_DCRL 3 "SNA" 2 "Untested" 1 "Set" 0 "Cleared" ;
VAL_ 687 demCinchCloseSignalError_DCRL 3 "SNA" 2 "Untested" 1 "Set" 0 "Cleared" ;
VAL_ 687 demReverseCinchTimeout_DCRL 3 "SNA" 2 "Untested" 1 "Set" 0 "Cleared" ;
VAL_ 687 demCinchOpenSignalError_DCRL 3 "SNA" 2 "Untested" 1 "Set" 0 "Cleared" ;
VAL_ 687 demDoorCinchTimeout_DCRL 3 "SNA" 2 "Untested" 1 "Set" 0 "Cleared" ;
VAL_ 687 demDoorLatchOpenAlwaysOn_DCRL 3 "SNA" 2 "Untested" 1 "Set" 0 "Cleared" ;
VAL_ 687 demDoorLatchOpenPowerLoss_DCRL 3 "SNA" 2 "Untested" 1 "Set" 0 "Cleared" ;
VAL_ 687 demDoorLatchOpenSignalError_DCRL 3 "SNA" 2 "Untested" 1 "Set" 0 "Cleared" ;
VAL_ 687 demDoorLatchOpenSignalLoss_DCRL 3 "SNA" 2 "Untested" 1 "Set" 0 "Cleared" ;
VAL_ 687 demDoorLatchPawlSignalError_DCRL 3 "SNA" 2 "Untested" 1 "Set" 0 "Cleared" ;
VAL_ 687 demDoorLatchPawlSignalLoss_DCRL 3 "SNA" 2 "Untested" 1 "Set" 0 "Cleared" ;
VAL_ 687 demDoorLatchSensorSnError_DCRL 3 "SNA" 2 "Untested" 1 "Set" 0 "Cleared" ;
VAL_ 687 demDoorLatchAjarSigLoss_DCRL 3 "SNA" 2 "Untested" 1 "Set" 0 "Cleared" ;
VAL_ 687 demDoorBrakeHallSnLoss_DCRL 3 "SNA" 2 "Untested" 1 "Set" 0 "Cleared" ;
VAL_ 687 demDoorHallSensorSnErr_DCRL 3 "SNA" 2 "Untested" 1 "Set" 0 "Cleared" ;
VAL_ 687 doorHallSensorSlow_DCRL 3 "SNA" 2 "Untested" 1 "Set" 0 "Cleared" ;
VAL_ 687 demDoorHallSensorFast_DCRL 3 "SNA" 2 "Untested" 1 "Set" 0 "Cleared" ;
VAL_ 687 demDoorHallSensorSignalLoss_DCRL 3 "SNA" 2 "Untested" 1 "Set" 0 "Cleared" ;
VAL_ 687 demMirrorMovetUncmd_DCRL 3 "SNA" 2 "Untested" 1 "Set" 0 "Cleared" ;
VAL_ 687 demMirrorMovementFailure_DCRL 3 "SNA" 2 "Untested" 1 "Set" 0 "Cleared" ;
VAL_ 686 demDEMNotification_DCRL 3 "SNA" 2 "Untested" 1 "Set" 0 "Cleared" ;
VAL_ 686 demDEMAssert_DCRL 3 "SNA" 2 "Untested" 1 "Set" 0 "Cleared" ;
VAL_ 686 demWindowDownFailure_DCRL 3 "SNA" 2 "Untested" 1 "Set" 0 "Cleared" ;
VAL_ 686 demWindowDownUncommanded_DCRL 3 "SNA" 2 "Untested" 1 "Set" 0 "Cleared" ;
VAL_ 686 demWindowUpUncommanded_DCRL 3 "SNA" 2 "Untested" 1 "Set" 0 "Cleared" ;
VAL_ 686 demWindowUpFailure_DCRL 3 "SNA" 2 "Untested" 1 "Set" 0 "Cleared" ;
VAL_ 686 demDoorCinchUncommanded_DCRL 3 "SNA" 2 "Untested" 1 "Set" 0 "Cleared" ;
VAL_ 686 demDoorCinchReleaseFailure_DCRL 3 "SNA" 2 "Untested" 1 "Set" 0 "Cleared" ;
VAL_ 686 demDoorMovementFault_DCRL 3 "SNA" 2 "Untested" 1 "Set" 0 "Cleared" ;
VAL_ 686 demDoorCloseUncommanded_DCRL 3 "SNA" 2 "Untested" 1 "Set" 0 "Cleared" ;
VAL_ 686 demDoorCloseFailure_DCRL 3 "SNA" 2 "Untested" 1 "Set" 0 "Cleared" ;
VAL_ 686 demLatchTimeout_DCRL 3 "SNA" 2 "Untested" 1 "Set" 0 "Cleared" ;
VAL_ 686 demDoorDirectionFault_DCRL 3 "SNA" 2 "Untested" 1 "Set" 0 "Cleared" ;
VAL_ 686 demDoorOpenUncommanded_DCRL 3 "SNA" 2 "Untested" 1 "Set" 0 "Cleared" ;
VAL_ 686 demDoorOpenFailure_DCRL 3 "SNA" 2 "Untested" 1 "Set" 0 "Cleared" ;
VAL_ 686 demMirrorMotorSignalLoss_DCRL 3 "SNA" 2 "Untested" 1 "Set" 0 "Cleared" ;
VAL_ 686 demMirrorMotorOvercurrent_DCRL 3 "SNA" 2 "Untested" 1 "Set" 0 "Cleared" ;
VAL_ 686 demWindowMotorSignalLoss_DCRL 3 "SNA" 2 "Untested" 1 "Set" 0 "Cleared" ;
VAL_ 686 demWindowCurrentFailure_DCRL 3 "SNA" 2 "Untested" 1 "Set" 0 "Cleared" ;
VAL_ 686 demWindowMotorUndercurrent_DCRL 3 "SNA" 2 "Untested" 1 "Set" 0 "Cleared" ;
VAL_ 686 demWindowMotorOvercurrent_DCRL 3 "SNA" 2 "Untested" 1 "Set" 0 "Cleared" ;
VAL_ 686 demCinchMotorPowerLoss_DCRL 3 "SNA" 2 "Untested" 1 "Set" 0 "Cleared" ;
VAL_ 686 demCinchMotorOvercurrent_DCRL 3 "SNA" 2 "Untested" 1 "Set" 0 "Cleared" ;
VAL_ 686 demLatchUncommandedOpen_DCRL 3 "SNA" 2 "Untested" 1 "Set" 0 "Cleared" ;
VAL_ 686 demDoorLatchStateError_DCRL 3 "SNA" 2 "Untested" 1 "Set" 0 "Cleared" ;
VAL_ 686 demDoorLatchPowerLoss_DCRL 3 "SNA" 2 "Untested" 1 "Set" 0 "Cleared" ;
VAL_ 686 demLatchMotorOvercurrent_DCRL 3 "SNA" 2 "Untested" 1 "Set" 0 "Cleared" ;
VAL_ 686 demDoorBrakeMotorSignalLoss_DCRL 3 "SNA" 2 "Untested" 1 "Set" 0 "Cleared" ;
VAL_ 686 demDoorBrakeOvercurrent_DCRL 3 "SNA" 2 "Untested" 1 "Set" 0 "Cleared" ;
VAL_ 686 demDoorCurrentSignalLoss_DCRL 3 "SNA" 2 "Untested" 1 "Set" 0 "Cleared" ;
VAL_ 686 demDoorMotorCurrentFailure_DCRL 3 "SNA" 2 "Untested" 1 "Set" 0 "Cleared" ;
VAL_ 686 demDoorMotorOvercurrent_DCRL 3 "SNA" 2 "Untested" 1 "Set" 0 "Cleared" ;
VAL_ 1120 demIRSensor2MIA_DCFL 3 "SNA" 2 "Untested" 1 "Set" 0 "Cleared" ;
VAL_ 1120 demIRSensor1MIA_DCFL 3 "SNA" 2 "Untested" 1 "Set" 0 "Cleared" ;
VAL_ 1120 demWinSwErr_DCFL 3 "SNA" 2 "Untested" 1 "Set" 0 "Cleared" ;
VAL_ 1120 demWinSwMIA_DCFL 3 "SNA" 2 "Untested" 1 "Set" 0 "Cleared" ;
VAL_ 1120 demLINNetworkFail_DCFL 3 "SNA" 2 "Untested" 1 "Set" 0 "Cleared" ;
VAL_ 1120 demBodyCANAmbTempMsgErr_DCFL 3 "SNA" 2 "Untested" 1 "Set" 0 "Cleared" ;
VAL_ 1120 demBodyCANAmbTempMsgMiss_DCFL 3 "SNA" 2 "Untested" 1 "Set" 0 "Cleared" ;
VAL_ 1120 demBodyCANCrashMsgErr_DCFL 3 "SNA" 2 "Untested" 1 "Set" 0 "Cleared" ;
VAL_ 1120 demBodyCANCrashMsgMiss_DCFL 3 "SNA" 2 "Untested" 1 "Set" 0 "Cleared" ;
VAL_ 1120 demBodyCANChildLkMsgErr_DCFL 3 "SNA" 2 "Untested" 1 "Set" 0 "Cleared" ;
VAL_ 1120 demBodyCANChildLkMsgMiss_DCFL 3 "SNA" 2 "Untested" 1 "Set" 0 "Cleared" ;
VAL_ 1120 demBodyCANLockMessageError_DCFL 3 "SNA" 2 "Untested" 1 "Set" 0 "Cleared" ;
VAL_ 1120 demBodyCANLkUnlkMsgMiss_DCFL 3 "SNA" 2 "Untested" 1 "Set" 0 "Cleared" ;
VAL_ 1120 demBodyCANOpClMsgErr_DCFL 3 "SNA" 2 "Untested" 1 "Set" 0 "Cleared" ;
VAL_ 1120 demBodyCANOpClMsgMiss_DCFL 3 "SNA" 2 "Untested" 1 "Set" 0 "Cleared" ;
VAL_ 1120 demBodyCANIMUMessageError_DCFL 3 "SNA" 2 "Untested" 1 "Set" 0 "Cleared" ;
VAL_ 1120 demBodyCANIMUMsgMiss_DCFL 3 "SNA" 2 "Untested" 1 "Set" 0 "Cleared" ;
VAL_ 1120 demBodyCANVehSpdMsgErr_DCFL 3 "SNA" 2 "Untested" 1 "Set" 0 "Cleared" ;
VAL_ 1120 demBodyCANVehSpdMsgMiss_DCFL 3 "SNA" 2 "Untested" 1 "Set" 0 "Cleared" ;
VAL_ 1120 demBodyCANNetworkFailure_DCFL 3 "SNA" 2 "Untested" 1 "Set" 0 "Cleared" ;
VAL_ 1120 demMirrorGlassPosSnsShCir_DCFL 3 "SNA" 2 "Untested" 1 "Set" 0 "Cleared" ;
VAL_ 1120 demMirrorGlassPosSnsOpenCir_DCFL 3 "SNA" 2 "Untested" 1 "Set" 0 "Cleared" ;
VAL_ 1120 demMirrorGlassPosSnsSnEr_DCFL 3 "SNA" 2 "Untested" 1 "Set" 0 "Cleared" ;
VAL_ 1120 demMirrorGlassPosSnsSnLoss_DCFL 3 "SNA" 2 "Untested" 1 "Set" 0 "Cleared" ;
VAL_ 1120 demMirrorGlassPosNotReached_DCFL 3 "SNA" 2 "Untested" 1 "Set" 0 "Cleared" ;
VAL_ 1120 demMirrorGlassMvtUcmd_DCFL 3 "SNA" 2 "Untested" 1 "Set" 0 "Cleared" ;
VAL_ 1120 demMirrorGlassMvFail_DCFL 3 "SNA" 2 "Untested" 1 "Set" 0 "Cleared" ;
VAL_ 1120 demIntOpenSwSnEr_DCFL 3 "SNA" 2 "Untested" 1 "Set" 0 "Cleared" ;
VAL_ 1120 demIntOpenSwSnLoss_DCFL 3 "SNA" 2 "Untested" 1 "Set" 0 "Cleared" ;
VAL_ 1120 demIntRelSwSnEr_DCFL 3 "SNA" 2 "Untested" 1 "Set" 0 "Cleared" ;
VAL_ 1120 demInteriorReleaseSwSnLoss_DCFL 3 "SNA" 2 "Untested" 1 "Set" 0 "Cleared" ;
VAL_ 1120 demDoorUnlockSwSnError_DCFL 3 "SNA" 2 "Untested" 1 "Set" 0 "Cleared" ;
VAL_ 615 demDoorLockSwitchSignalLoss_DCFL 3 "SNA" 2 "Untested" 1 "Set" 0 "Cleared" ;
VAL_ 615 demDoorExtCapSwSnEr_DCFL 3 "SNA" 2 "Untested" 1 "Set" 0 "Cleared" ;
VAL_ 615 demDoorExtCapSwSnLoss_DCFL 3 "SNA" 2 "Untested" 1 "Set" 0 "Cleared" ;
VAL_ 615 demDoorExtCapSwPower_DCFL 3 "SNA" 2 "Untested" 1 "Set" 0 "Cleared" ;
VAL_ 615 demDoorExtCapSwNoPower_DCFL 3 "SNA" 2 "Untested" 1 "Set" 0 "Cleared" ;
VAL_ 615 demDoorExtMechSwSnEr_DCFL 3 "SNA" 2 "Untested" 1 "Set" 0 "Cleared" ;
VAL_ 615 demDoorExtMechSwSnLoss_DCFL 3 "SNA" 2 "Untested" 1 "Set" 0 "Cleared" ;
VAL_ 615 demDoorExtMechSwPower_DCFL 3 "SNA" 2 "Untested" 1 "Set" 0 "Cleared" ;
VAL_ 615 demDoorExtMechSwPowerLoss_DCFL 3 "SNA" 2 "Untested" 1 "Set" 0 "Cleared" ;
VAL_ 615 demWindowHallSignalError_DCFL 3 "SNA" 2 "Untested" 1 "Set" 0 "Cleared" ;
VAL_ 615 demWindowHallSnsPowerLoss_DCFL 3 "SNA" 2 "Untested" 1 "Set" 0 "Cleared" ;
VAL_ 615 demWindowHallSignalLoss_DCFL 3 "SNA" 2 "Untested" 1 "Set" 0 "Cleared" ;
VAL_ 615 demWindowVelocityTimeout_DCFL 3 "SNA" 2 "Untested" 1 "Set" 0 "Cleared" ;
VAL_ 615 demCinchCloseSignalError_DCFL 3 "SNA" 2 "Untested" 1 "Set" 0 "Cleared" ;
VAL_ 615 demReverseCinchTimeout_DCFL 3 "SNA" 2 "Untested" 1 "Set" 0 "Cleared" ;
VAL_ 615 demCinchOpenSignalError_DCFL 3 "SNA" 2 "Untested" 1 "Set" 0 "Cleared" ;
VAL_ 615 demDoorCinchTimeout_DCFL 3 "SNA" 2 "Untested" 1 "Set" 0 "Cleared" ;
VAL_ 615 demDoorLatchOpenAlwaysOn_DCFL 3 "SNA" 2 "Untested" 1 "Set" 0 "Cleared" ;
VAL_ 615 demDoorLatchOpenPowerLoss_DCFL 3 "SNA" 2 "Untested" 1 "Set" 0 "Cleared" ;
VAL_ 615 demDoorLatchOpenSignalError_DCFL 3 "SNA" 2 "Untested" 1 "Set" 0 "Cleared" ;
VAL_ 615 demDoorLatchOpenSignalLoss_DCFL 3 "SNA" 2 "Untested" 1 "Set" 0 "Cleared" ;
VAL_ 615 demDoorLatchPawlSignalError_DCFL 3 "SNA" 2 "Untested" 1 "Set" 0 "Cleared" ;
VAL_ 615 demDoorLatchPawlSignalLoss_DCFL 3 "SNA" 2 "Untested" 1 "Set" 0 "Cleared" ;
VAL_ 615 demDoorLatchSensorSnError_DCFL 3 "SNA" 2 "Untested" 1 "Set" 0 "Cleared" ;
VAL_ 615 demDoorLatchAjarSigLoss_DCFL 3 "SNA" 2 "Untested" 1 "Set" 0 "Cleared" ;
VAL_ 615 demDoorBrakeHallSnLoss_DCFL 3 "SNA" 2 "Untested" 1 "Set" 0 "Cleared" ;
VAL_ 615 demDoorHallSensorSnErr_DCFL 3 "SNA" 2 "Untested" 1 "Set" 0 "Cleared" ;
VAL_ 615 doorHallSensorSlow_DCFL 3 "SNA" 2 "Untested" 1 "Set" 0 "Cleared" ;
VAL_ 615 demDoorHallSensorFast_DCFL 3 "SNA" 2 "Untested" 1 "Set" 0 "Cleared" ;
VAL_ 615 demDoorHallSensorSignalLoss_DCFL 3 "SNA" 2 "Untested" 1 "Set" 0 "Cleared" ;
VAL_ 615 demMirrorMovetUncmd_DCFL 3 "SNA" 2 "Untested" 1 "Set" 0 "Cleared" ;
VAL_ 615 demMirrorMovementFailure_DCFL 3 "SNA" 2 "Untested" 1 "Set" 0 "Cleared" ;
VAL_ 614 demDEMNotification_DCFL 3 "SNA" 2 "Untested" 1 "Set" 0 "Cleared" ;
VAL_ 614 demDEMAssert_DCFL 3 "SNA" 2 "Untested" 1 "Set" 0 "Cleared" ;
VAL_ 614 demWindowDownFailure_DCFL 3 "SNA" 2 "Untested" 1 "Set" 0 "Cleared" ;
VAL_ 614 demWindowDownUncommanded_DCFL 3 "SNA" 2 "Untested" 1 "Set" 0 "Cleared" ;
VAL_ 614 demWindowUpUncommanded_DCFL 3 "SNA" 2 "Untested" 1 "Set" 0 "Cleared" ;
VAL_ 614 demWindowUpFailure_DCFL 3 "SNA" 2 "Untested" 1 "Set" 0 "Cleared" ;
VAL_ 614 demDoorCinchUncommanded_DCFL 3 "SNA" 2 "Untested" 1 "Set" 0 "Cleared" ;
VAL_ 614 demDoorCinchReleaseFailure_DCFL 3 "SNA" 2 "Untested" 1 "Set" 0 "Cleared" ;
VAL_ 614 demDoorMovementFault_DCFL 3 "SNA" 2 "Untested" 1 "Set" 0 "Cleared" ;
VAL_ 614 demDoorCloseUncommanded_DCFL 3 "SNA" 2 "Untested" 1 "Set" 0 "Cleared" ;
VAL_ 614 demDoorCloseFailure_DCFL 3 "SNA" 2 "Untested" 1 "Set" 0 "Cleared" ;
VAL_ 614 demLatchTimeout_DCFL 3 "SNA" 2 "Untested" 1 "Set" 0 "Cleared" ;
VAL_ 614 demDoorDirectionFault_DCFL 3 "SNA" 2 "Untested" 1 "Set" 0 "Cleared" ;
VAL_ 614 demDoorOpenUncommanded_DCFL 3 "SNA" 2 "Untested" 1 "Set" 0 "Cleared" ;
VAL_ 614 demDoorOpenFailure_DCFL 3 "SNA" 2 "Untested" 1 "Set" 0 "Cleared" ;
VAL_ 614 demMirrorMotorSignalLoss_DCFL 3 "SNA" 2 "Untested" 1 "Set" 0 "Cleared" ;
VAL_ 614 demMirrorMotorOvercurrent_DCFL 3 "SNA" 2 "Untested" 1 "Set" 0 "Cleared" ;
VAL_ 614 demWindowMotorSignalLoss_DCFL 3 "SNA" 2 "Untested" 1 "Set" 0 "Cleared" ;
VAL_ 614 demWindowCurrentFailure_DCFL 3 "SNA" 2 "Untested" 1 "Set" 0 "Cleared" ;
VAL_ 614 demWindowMotorUndercurrent_DCFL 3 "SNA" 2 "Untested" 1 "Set" 0 "Cleared" ;
VAL_ 614 demWindowMotorOvercurrent_DCFL 3 "SNA" 2 "Untested" 1 "Set" 0 "Cleared" ;
VAL_ 614 demCinchMotorPowerLoss_DCFL 3 "SNA" 2 "Untested" 1 "Set" 0 "Cleared" ;
VAL_ 614 demCinchMotorOvercurrent_DCFL 3 "SNA" 2 "Untested" 1 "Set" 0 "Cleared" ;
VAL_ 614 demLatchUncommandedOpen_DCFL 3 "SNA" 2 "Untested" 1 "Set" 0 "Cleared" ;
VAL_ 614 demDoorLatchStateError_DCFL 3 "SNA" 2 "Untested" 1 "Set" 0 "Cleared" ;
VAL_ 614 demDoorLatchPowerLoss_DCFL 3 "SNA" 2 "Untested" 1 "Set" 0 "Cleared" ;
VAL_ 614 demLatchMotorOvercurrent_DCFL 3 "SNA" 2 "Untested" 1 "Set" 0 "Cleared" ;
VAL_ 614 demDoorBrakeMotorSignalLoss_DCFL 3 "SNA" 2 "Untested" 1 "Set" 0 "Cleared" ;
VAL_ 614 demDoorBrakeOvercurrent_DCFL 3 "SNA" 2 "Untested" 1 "Set" 0 "Cleared" ;
VAL_ 614 demDoorCurrentSignalLoss_DCFL 3 "SNA" 2 "Untested" 1 "Set" 0 "Cleared" ;
VAL_ 614 demDoorMotorCurrentFailure_DCFL 3 "SNA" 2 "Untested" 1 "Set" 0 "Cleared" ;
VAL_ 614 demDoorMotorOvercurrent_DCFL 3 "SNA" 2 "Untested" 1 "Set" 0 "Cleared" ;
